VERSION ""

NS_ :

BS_:

BU_: WPC2 RLPSU DPSU APSU PSB SHVU_RR vHS_B2 FCS EMCU SLB ARS RCM CGW_CCU vDummy_HS_B ATS RLHV SGU PFSU ALBCU DSAU SWRC SHVU_FR RCS RRPSU BLTN_CAM SCM DLBCU OHCL RWPC RRHV WPC HOD ASAU

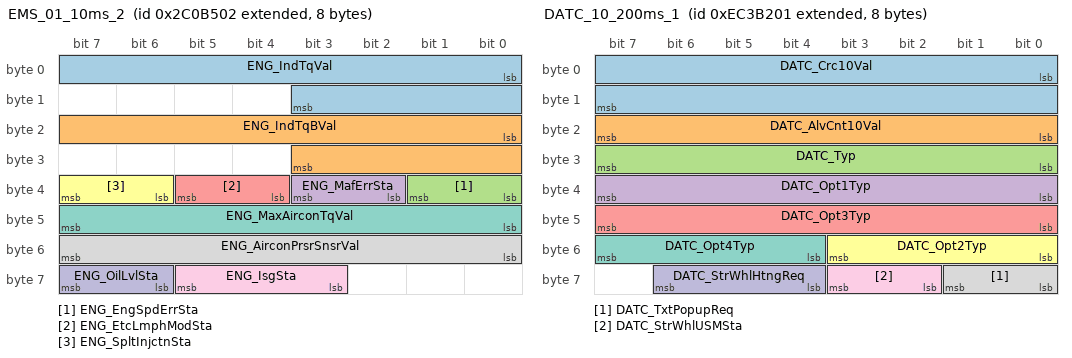
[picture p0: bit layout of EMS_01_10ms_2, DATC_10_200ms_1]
BO_ 2193667330 EMS_01_10ms_2: 8 CGW_CCU
 SG_ ENG_IndTqVal : 0|12@1- (1,0) [0|0] "Nm"  Vector__XXX
 SG_ ENG_IndTqBVal : 16|12@1- (1,0) [0|0] "Nm"  Vector__XXX
 SG_ ENG_EngSpdErrSta : 32|2@1+ (1,0) [0|0] ""  Vector__XXX
 SG_ ENG_MafErrSta : 34|2@1+ (1,0) [0|0] ""  Vector__XXX
 SG_ ENG_EtcLmphModSta : 36|2@1+ (1,0) [0|0] ""  Vector__XXX
 SG_ ENG_SpltInjctnSta : 38|2@1+ (1,0) [0|0] ""  Vector__XXX
 SG_ ENG_MaxAirconTqVal : 40|8@1+ (0.2,0) [0|0] "Nm"  Vector__XXX
 SG_ ENG_AirconPrsrSnsrVal : 48|8@1+ (125,0) [0|0] "hPa"  Vector__XXX
 SG_ ENG_IsgSta : 59|3@1+ (1,0) [0|0] ""  APSU,RLHV,RRHV,SHVU_FR,SHVU_RR,DPSU,RRPSU,RLPSU,EMCU
 SG_ ENG_OilLvlSta : 62|2@1+ (1,0) [0|0] ""  Vector__XXX

BO_ 2395189761 DATC_10_200ms_1: 8 CGW_CCU
 SG_ DATC_Crc10Val : 0|16@1+ (1,0) [0|0] ""  Vector__XXX
 SG_ DATC_AlvCnt10Val : 16|8@1+ (1,0) [0|0] ""  Vector__XXX
 SG_ DATC_Typ : 24|8@1+ (1,0) [0|0] ""  RLHV,RRHV,SHVU_FR,SHVU_RR,ATS
 SG_ DATC_Opt1Typ : 32|8@1+ (1,0) [0|0] ""  ATS
 SG_ DATC_Opt3Typ : 40|8@1+ (1,0) [0|0] ""  ATS
 SG_ DATC_Opt2Typ : 48|4@1+ (1,0) [0|0] ""  ATS
 SG_ DATC_Opt4Typ : 52|4@1+ (1,0) [0|0] ""  ATS
 SG_ DATC_TxtPopupReq : 56|2@1+ (1,0) [0|0] ""  Vector__XXX
 SG_ DATC_StrWhlUSMSta : 58|2@1+ (1,0) [0|0] ""  APSU
 SG_ DATC_StrWhlHtngReq : 60|3@1+ (1,0) [0|0] ""  Vector__XXX

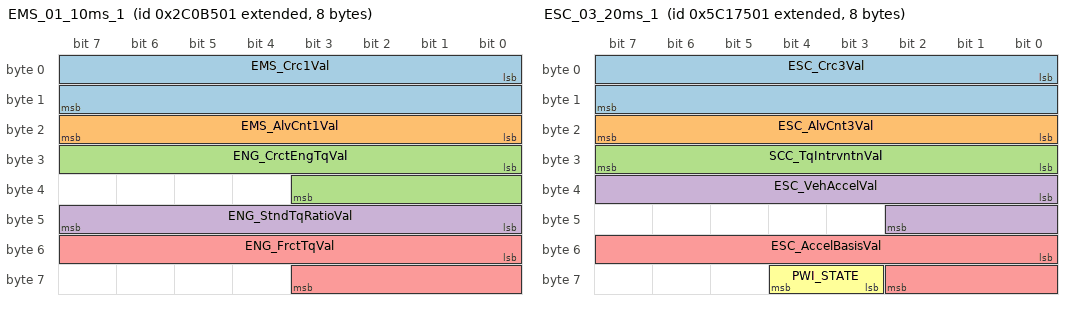
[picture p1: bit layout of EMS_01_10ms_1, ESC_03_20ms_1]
BO_ 2193667329 EMS_01_10ms_1: 8 CGW_CCU
 SG_ EMS_Crc1Val : 0|16@1+ (1,0) [0|0] ""  Vector__XXX
 SG_ EMS_AlvCnt1Val : 16|8@1+ (1,0) [0|0] ""  Vector__XXX
 SG_ ENG_CrctEngTqVal : 24|12@1- (1,0) [0|0] "Nm"  Vector__XXX
 SG_ ENG_StndTqRatioVal : 40|8@1+ (0.0078,0) [0|0] ""  Vector__XXX
 SG_ ENG_FrctTqVal : 48|12@1- (1,0) [0|0] "Nm"  Vector__XXX

BO_ 2214659332 EMS_07_10ms_4: 8 CGW_CCU

BO_ 2214659331 EMS_07_10ms_3: 8 CGW_CCU

BO_ 2244048129 ESC_03_20ms_1: 8 CGW_CCU
 SG_ ESC_Crc3Val : 0|16@1+ (1,0) [0|0] ""  Vector__XXX
 SG_ ESC_AlvCnt3Val : 16|8@1+ (1,0) [0|0] ""  Vector__XXX
 SG_ SCC_TqIntrvntnVal : 24|8@1+ (0.390625,0) [0|0] "%"  Vector__XXX
 SG_ ESC_VehAccelVal : 32|11@1+ (0.01,-10.23) [0|0] "m/s^2"  Vector__XXX
 SG_ ESC_AccelBasisVal : 48|11@1+ (0.01,-10.23) [0|0] "m/s^2"  Vector__XXX
 SG_ PWI_STATE : 59|2@1+ (1,0) [0|0] ""  Vector__XXX

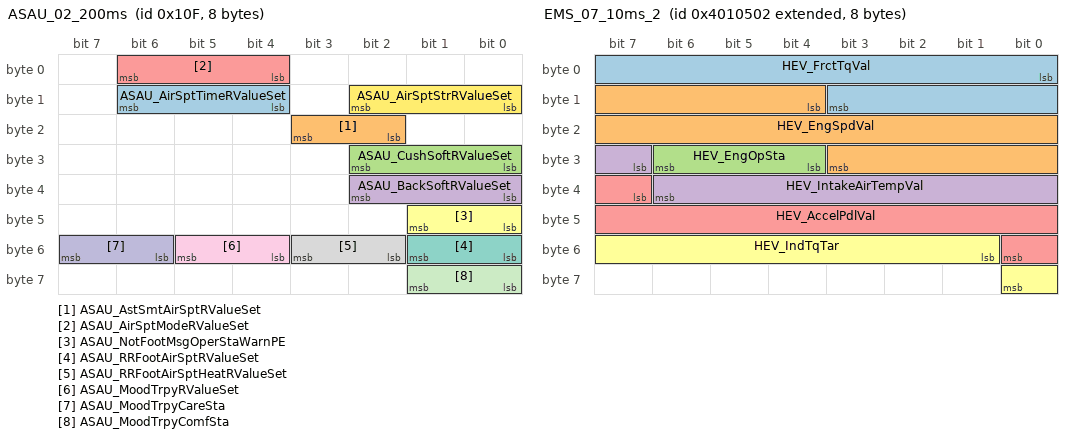
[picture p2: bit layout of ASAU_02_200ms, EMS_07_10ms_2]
BO_ 271 ASAU_02_200ms: 8 ASAU
 SG_ ASAU_AirSptTimeRValueSet : 12|3@1+ (1,0) [0|0] ""  CGW_CCU
 SG_ ASAU_AstSmtAirSptRValueSet : 18|2@1+ (1,0) [0|0] ""  CGW_CCU
 SG_ ASAU_CushSoftRValueSet : 24|3@1+ (1,0) [0|0] ""  CGW_CCU
 SG_ ASAU_BackSoftRValueSet : 32|3@1+ (1,0) [0|0] ""  CGW_CCU
 SG_ ASAU_AirSptModeRValueSet : 4|3@1+ (1,0) [0|0] ""  CGW_CCU
 SG_ ASAU_NotFootMsgOperStaWarnPE : 40|2@1+ (1,0) [0|0] ""  ATS
 SG_ ASAU_RRFootAirSptRValueSet : 48|2@1+ (1,0) [0|0] ""  ATS
 SG_ ASAU_RRFootAirSptHeatRValueSet : 50|2@1+ (1,0) [0|0] ""  ATS
 SG_ ASAU_MoodTrpyRValueSet : 52|2@1+ (1,0) [0|0] ""  CGW_CCU
 SG_ ASAU_MoodTrpyCareSta : 54|2@1+ (1,0) [0|0] ""  CGW_CCU
 SG_ ASAU_MoodTrpyComfSta : 56|2@1+ (1,0) [0|0] ""  CGW_CCU
 SG_ ASAU_AirSptStrRValueSet : 8|3@1+ (1,0) [0|0] ""  CGW_CCU

BO_ 2214659330 EMS_07_10ms_2: 8 CGW_CCU
 SG_ HEV_FrctTqVal : 0|12@1+ (0.1,0) [0|0] "Nm"  Vector__XXX
 SG_ HEV_EngSpdVal : 12|16@1+ (0.25,0) [0|0] "rpm"  Vector__XXX
 SG_ HEV_EngOpSta : 28|3@1+ (1,0) [0|0] ""  WPC,RWPC,PFSU,WPC2
 SG_ HEV_IntakeAirTempVal : 31|8@1+ (0.75,-48) [0|0] "¡É"  Vector__XXX
 SG_ HEV_AccelPdlVal : 39|10@1+ (0.09784,0) [0|0] "%"  BLTN_CAM
 SG_ HEV_IndTqTar : 49|8@1+ (0.3906,0) [0|0] "%"  Vector__XXX

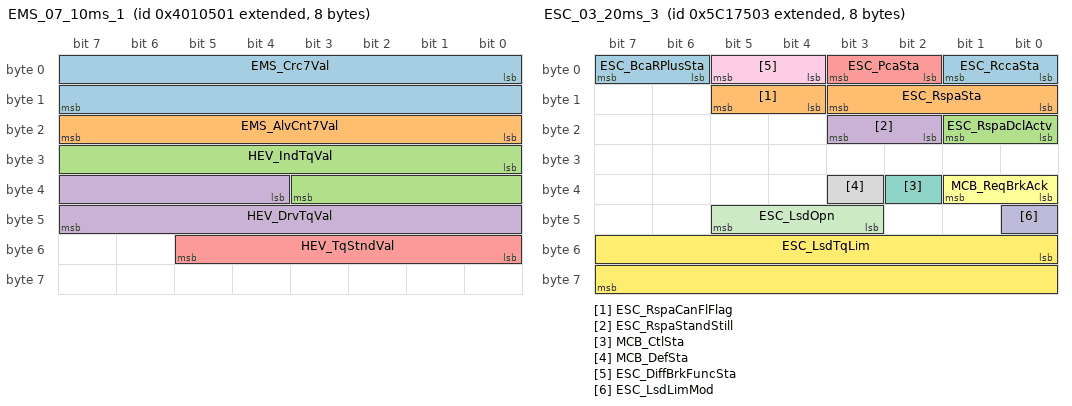
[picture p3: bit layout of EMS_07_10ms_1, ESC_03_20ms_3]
BO_ 2214659329 EMS_07_10ms_1: 8 CGW_CCU
 SG_ EMS_Crc7Val : 0|16@1+ (1,0) [0|0] ""  Vector__XXX
 SG_ EMS_AlvCnt7Val : 16|8@1+ (1,0) [0|0] ""  Vector__XXX
 SG_ HEV_IndTqVal : 24|12@1+ (0.1,0) [0|0] "Nm"  Vector__XXX
 SG_ HEV_DrvTqVal : 36|12@1+ (0.390625,0) [0|0] "%"  Vector__XXX
 SG_ HEV_TqStndVal : 48|6@1+ (10,0) [0|0] "Nm"  Vector__XXX

BO_ 2244048131 ESC_03_20ms_3: 8 CGW_CCU
 SG_ ESC_RccaSta : 0|2@1+ (1,0) [0|0] ""  Vector__XXX
 SG_ ESC_RspaCanFlFlag : 12|2@1+ (1,0) [0|0] ""  Vector__XXX
 SG_ ESC_RspaDclActv : 16|2@1+ (1,0) [0|0] ""  Vector__XXX
 SG_ ESC_RspaStandStill : 18|2@1+ (1,0) [0|0] ""  Vector__XXX
 SG_ ESC_PcaSta : 2|2@1+ (1,0) [0|0] ""  Vector__XXX
 SG_ MCB_ReqBrkAck : 32|2@1+ (1,0) [0|0] ""  Vector__XXX
 SG_ MCB_CtlSta : 34|1@1+ (1,0) [0|0] ""  Vector__XXX
 SG_ MCB_DefSta : 35|1@1+ (1,0) [0|0] ""  Vector__XXX
 SG_ ESC_DiffBrkFuncSta : 4|2@1+ (1,0) [0|0] ""  Vector__XXX
 SG_ ESC_LsdLimMod : 40|1@1+ (1,0) [0|0] ""  Vector__XXX
 SG_ ESC_LsdOpn : 43|3@1+ (1,0) [0|0] ""  Vector__XXX
 SG_ ESC_LsdTqLim : 48|16@1+ (1,0) [0|0] "Nm"  Vector__XXX
 SG_ ESC_BcaRPlusSta : 6|2@1+ (1,0) [0|0] ""  Vector__XXX
 SG_ ESC_RspaSta : 8|4@1+ (1,0) [0|0] ""  Vector__XXX

BO_ 2244048130 ESC_03_20ms_2: 8 CGW_CCU
 SG_ SCC_OptTyp : 0|2@1+ (1,0) [0|0] ""  Vector__XXX
 SG_ ESC_BrkLtReq : 10|2@1+ (1,0) [0|0] ""  Vector__XXX
 SG_ ESC_DclEnblReq : 12|2@1+ (1,0) [0|0] ""  Vector__XXX
 SG_ ESC_DrvOvrdSta : 16|2@1+ (1,0) [0|0] ""  Vector__XXX
 SG_ ESC_DrvBrkSta : 18|2@1+ (1,0) [0|0] ""  Vector__XXX
 SG_ SCC_EnblReq : 2|2@1+ (1,0) [0|0] ""  Vector__XXX
 SG_ ESC_DrvBrkActvSta : 20|2@1+ (1,0) [0|0] ""  Vector__XXX
 SG_ ESC_PrkBrkActvSta : 22|2@1+ (1,0) [0|0] ""  Vector__XXX
 SG_ ESC_HDP_FltMonSta : 24|3@1+ (1,0) [0|0] ""  PSB
 SG_ FCA_EquipSta : 32|2@1+ (1,0) [0|0] ""  Vector__XXX
 SG_ FCA_AvlblSta : 34|2@1+ (1,0) [0|0] ""  Vector__XXX
 SG_ ESC_FCA_ActvSta : 36|2@1+ (1,0) [0|0] ""  Vector__XXX
 SG_ ESC_DBS_ActvSta : 38|2@1+ (1,0) [0|0] ""  Vector__XXX
 SG_ SCC_TqReq : 4|2@1+ (1,0) [0|0] ""  Vector__XXX
 SG_ ESC_HDP_EgSta : 40|3@1+ (1,0) [0|0] ""  Vector__XXX
 SG_ ESC_HDP_EnblReq : 43|3@1+ (1,0) [0|0] ""  Vector__XXX
 SG_ CSC_WrngSta : 50|2@1+ (1,0) [0|0] ""  Vector__XXX
 SG_ ESC_BrkdFltStndstill : 56|2@1+ (1,0) [0|0] ""  Vector__XXX
 SG_ SCC_ReqLimSta : 6|2@1+ (1,0) [0|0] ""  Vector__XXX
 SG_ ESC_StdStillVal : 8|2@1+ (1,0) [0|0] ""  Vector__XXX

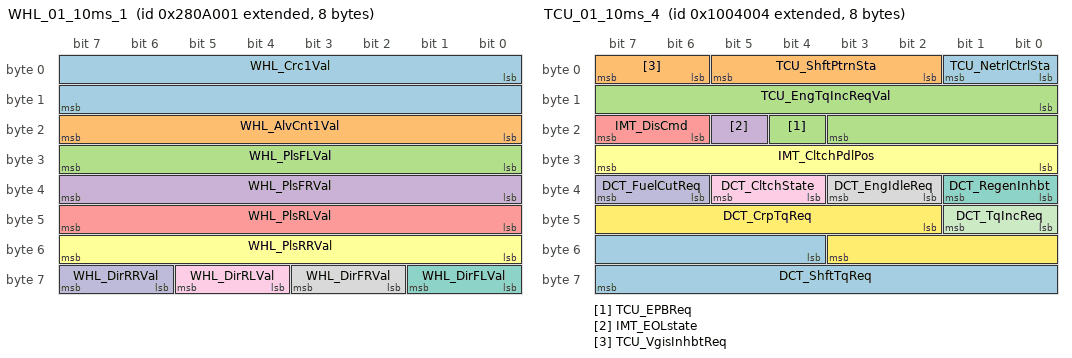
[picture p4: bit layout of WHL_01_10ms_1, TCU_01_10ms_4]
BO_ 2189467649 WHL_01_10ms_1: 8 CGW_CCU
 SG_ WHL_Crc1Val : 0|16@1+ (1,0) [0|0] ""  Vector__XXX
 SG_ WHL_AlvCnt1Val : 16|8@1+ (1,0) [0|0] ""  Vector__XXX
 SG_ WHL_PlsFLVal : 24|8@1+ (0.5,0) [0|0] "pulse count"  Vector__XXX
 SG_ WHL_PlsFRVal : 32|8@1+ (0.5,0) [0|0] "pulse count"  Vector__XXX
 SG_ WHL_PlsRLVal : 40|8@1+ (0.5,0) [0|0] "pulse count"  Vector__XXX
 SG_ WHL_PlsRRVal : 48|8@1+ (0.5,0) [0|0] "pulse count"  Vector__XXX
 SG_ WHL_DirFLVal : 56|2@1+ (1,0) [0|0] ""  Vector__XXX
 SG_ WHL_DirFRVal : 58|2@1+ (1,0) [0|0] ""  Vector__XXX
 SG_ WHL_DirRLVal : 60|2@1+ (1,0) [0|0] ""  Vector__XXX
 SG_ WHL_DirRRVal : 62|2@1+ (1,0) [0|0] ""  Vector__XXX

BO_ 2164277252 TCU_01_10ms_4: 8 CGW_CCU
 SG_ TCU_NetrlCtrlSta : 0|2@1+ (1,0) [0|0] ""  Vector__XXX
 SG_ TCU_ShftPtrnSta : 2|4@1+ (1,0) [0|0] ""  Vector__XXX
 SG_ TCU_EPBReq : 20|1@1+ (1,0) [0|0] ""  Vector__XXX
 SG_ IMT_EOLstate : 21|1@1+ (1,0) [0|0] ""  Vector__XXX
 SG_ IMT_DisCmd : 22|2@1+ (1,0) [0|0] ""  Vector__XXX
 SG_ IMT_CltchPdlPos : 24|8@1+ (0.390625,0) [0|0] "%"  Vector__XXX
 SG_ DCT_RegenInhbt : 32|2@1+ (1,0) [0|0] ""  Vector__XXX
 SG_ DCT_EngIdleReq : 34|2@1+ (1,0) [0|0] ""  Vector__XXX
 SG_ DCT_CltchState : 36|2@1+ (1,0) [0|0] ""  Vector__XXX
 SG_ DCT_FuelCutReq : 38|2@1+ (1,0) [0|0] ""  Vector__XXX
 SG_ DCT_TqIncReq : 40|2@1+ (1,0) [0|0] ""  Vector__XXX
 SG_ DCT_CrpTqReq : 42|10@1+ (1,-512) [0|0] "Nm"  Vector__XXX
 SG_ DCT_ShftTqReq : 52|12@1- (1,0) [0|0] "Nm"  Vector__XXX
 SG_ TCU_VgisInhbtReq : 6|2@1+ (1,0) [0|0] ""  Vector__XXX
 SG_ TCU_EngTqIncReqVal : 8|12@1- (1,0) [0|0] "Nm"  Vector__XXX

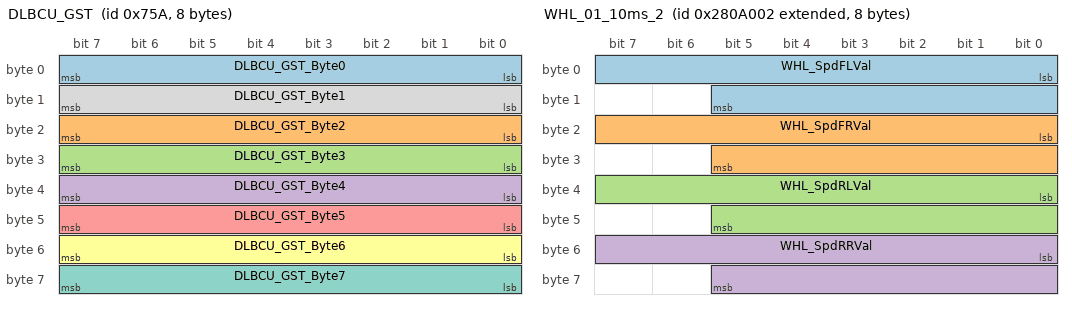
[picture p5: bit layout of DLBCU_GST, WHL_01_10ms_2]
BO_ 1882 DLBCU_GST: 8 DLBCU
 SG_ DLBCU_GST_Byte0 : 0|8@1+ (1,0) [0|0] ""  CGW_CCU
 SG_ DLBCU_GST_Byte2 : 16|8@1+ (1,0) [0|0] ""  CGW_CCU
 SG_ DLBCU_GST_Byte3 : 24|8@1+ (1,0) [0|0] ""  CGW_CCU
 SG_ DLBCU_GST_Byte4 : 32|8@1+ (1,0) [0|0] ""  CGW_CCU
 SG_ DLBCU_GST_Byte5 : 40|8@1+ (1,0) [0|0] ""  CGW_CCU
 SG_ DLBCU_GST_Byte6 : 48|8@1+ (1,0) [0|0] ""  CGW_CCU
 SG_ DLBCU_GST_Byte7 : 56|8@1+ (1,0) [0|0] ""  CGW_CCU
 SG_ DLBCU_GST_Byte1 : 8|8@1+ (1,0) [0|0] ""  CGW_CCU

BO_ 2189467650 WHL_01_10ms_2: 8 CGW_CCU
 SG_ WHL_SpdFLVal : 0|14@1+ (0.03125,0) [0|0] "km^h"  PSB
 SG_ WHL_SpdFRVal : 16|14@1+ (0.03125,0) [0|0] "km^h"  PSB
 SG_ WHL_SpdRLVal : 32|14@1+ (0.03125,0) [0|0] "km^h"  PSB,APSU
 SG_ WHL_SpdRRVal : 48|14@1+ (0.03125,0) [0|0] "km^h"  PSB,APSU

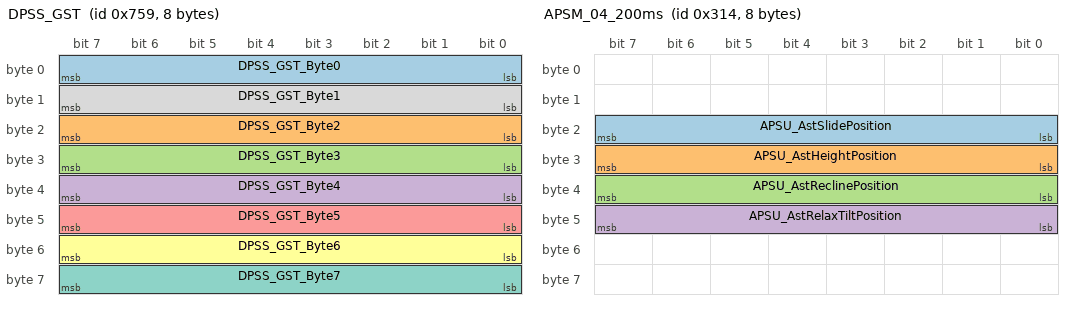
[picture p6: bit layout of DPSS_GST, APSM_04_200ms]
BO_ 1881 DPSS_GST: 8 DPSU
 SG_ DPSS_GST_Byte0 : 0|8@1+ (1,0) [0|0] ""  CGW_CCU
 SG_ DPSS_GST_Byte2 : 16|8@1+ (1,0) [0|0] ""  CGW_CCU
 SG_ DPSS_GST_Byte3 : 24|8@1+ (1,0) [0|0] ""  CGW_CCU
 SG_ DPSS_GST_Byte4 : 32|8@1+ (1,0) [0|0] ""  CGW_CCU
 SG_ DPSS_GST_Byte5 : 40|8@1+ (1,0) [0|0] ""  CGW_CCU
 SG_ DPSS_GST_Byte6 : 48|8@1+ (1,0) [0|0] ""  CGW_CCU
 SG_ DPSS_GST_Byte7 : 56|8@1+ (1,0) [0|0] ""  CGW_CCU
 SG_ DPSS_GST_Byte1 : 8|8@1+ (1,0) [0|0] ""  CGW_CCU

BO_ 2189467651 WHL_01_10ms_3: 8 CGW_CCU
 SG_ WHL_SpdCalParmtr : 8|9@1+ (0.5,200) [0|0] "mm"  Vector__XXX

BO_ 788 APSM_04_200ms: 8 APSU
 SG_ APSU_AstSlidePosition : 16|8@1+ (1,0) [0|0] ""  CGW_CCU
 SG_ APSU_AstHeightPosition : 24|8@1+ (1,0) [0|0] ""  CGW_CCU
 SG_ APSU_AstReclinePosition : 32|8@1+ (1,0) [0|0] ""  CGW_CCU
 SG_ APSU_AstRelaxTiltPosition : 40|8@1+ (1,0) [0|0] ""  CGW_CCU

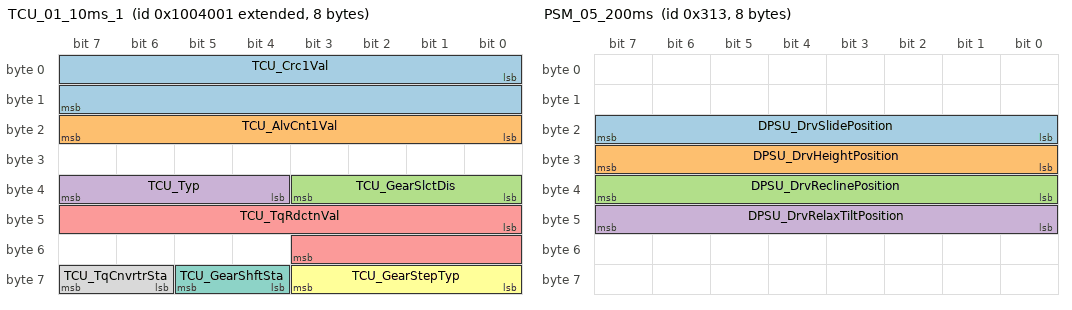
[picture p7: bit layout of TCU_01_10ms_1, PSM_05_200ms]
BO_ 2164277249 TCU_01_10ms_1: 8 CGW_CCU
 SG_ TCU_Crc1Val : 0|16@1+ (1,0) [0|0] ""  Vector__XXX
 SG_ TCU_AlvCnt1Val : 16|8@1+ (1,0) [0|0] ""  EMCU
 SG_ TCU_GearSlctDis : 32|4@1+ (1,0) [0|0] ""  SWRC,APSU,RLHV,RRHV,PFSU,RRPSU,RLPSU,BLTN_CAM
 SG_ TCU_Typ : 36|4@1+ (1,0) [0|0] ""  APSU,PFSU
 SG_ TCU_TqRdctnVal : 40|12@1- (1,0) [0|0] "Nm"  Vector__XXX
 SG_ TCU_GearStepTyp : 56|4@1+ (1,0) [0|0] ""  Vector__XXX
 SG_ TCU_GearShftSta : 60|2@1+ (1,0) [0|0] ""  Vector__XXX
 SG_ TCU_TqCnvrtrSta : 62|2@1+ (1,0) [0|0] ""  EMCU

BO_ 787 PSM_05_200ms: 8 DPSU
 SG_ DPSU_DrvSlidePosition : 16|8@1+ (1,0) [0|0] ""  CGW_CCU
 SG_ DPSU_DrvHeightPosition : 24|8@1+ (1,0) [0|0] ""  CGW_CCU
 SG_ DPSU_DrvReclinePosition : 32|8@1+ (1,0) [0|0] ""  CGW_CCU
 SG_ DPSU_DrvRelaxTiltPosition : 40|8@1+ (1,0) [0|0] ""  CGW_CCU

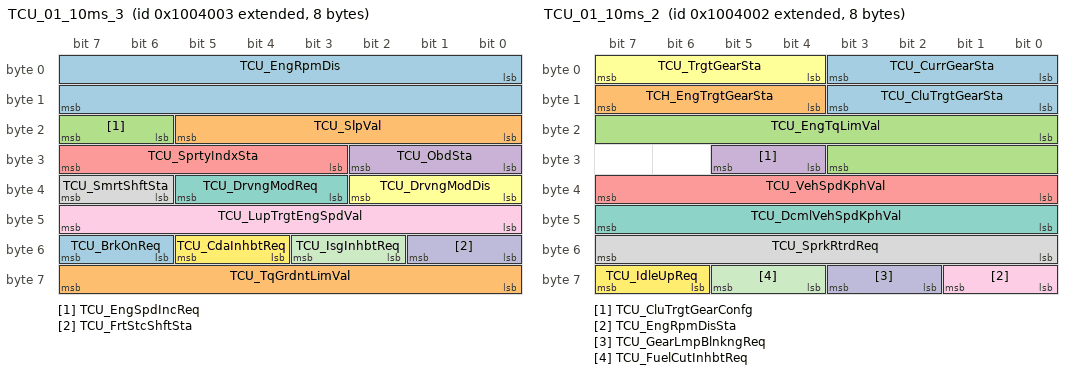
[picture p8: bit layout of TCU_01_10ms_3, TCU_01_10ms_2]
BO_ 2164277251 TCU_01_10ms_3: 8 CGW_CCU
 SG_ TCU_EngRpmDis : 0|16@1+ (0.25,0) [0|0] "rpm"  Vector__XXX
 SG_ TCU_SlpVal : 16|6@1+ (0.5,-16) [0|0] "%"  Vector__XXX
 SG_ TCU_EngSpdIncReq : 22|2@1+ (1,0) [0|0] ""  Vector__XXX
 SG_ TCU_ObdSta : 24|3@1+ (1,0) [0|0] ""  Vector__XXX
 SG_ TCU_SprtyIndxSta : 27|5@1+ (1,0) [0|0] ""  Vector__XXX
 SG_ TCU_DrvngModDis : 32|3@1+ (1,0) [0|0] ""  Vector__XXX
 SG_ TCU_DrvngModReq : 35|3@1+ (1,0) [0|0] ""  Vector__XXX
 SG_ TCU_SmrtShftSta : 38|2@1+ (1,0) [0|0] ""  Vector__XXX
 SG_ TCU_LupTrgtEngSpdVal : 40|8@1+ (10,500) [0|0] "rpm"  Vector__XXX
 SG_ TCU_FrtStcShftSta : 48|2@1+ (1,0) [0|0] ""  Vector__XXX
 SG_ TCU_IsgInhbtReq : 50|2@1+ (1,0) [0|0] ""  Vector__XXX
 SG_ TCU_CdaInhbtReq : 52|2@1+ (1,0) [0|0] ""  Vector__XXX
 SG_ TCU_BrkOnReq : 54|2@1+ (1,0) [0|0] ""  Vector__XXX
 SG_ TCU_TqGrdntLimVal : 56|8@1+ (10,0) [0|0] "Nm/s"  Vector__XXX

BO_ 2164277250 TCU_01_10ms_2: 8 CGW_CCU
 SG_ TCU_CurrGearSta : 0|4@1+ (1,0) [0|0] ""  EMCU
 SG_ TCH_EngTrgtGearSta : 12|4@1+ (1,0) [0|0] ""  Vector__XXX
 SG_ TCU_EngTqLimVal : 16|12@1- (1,0) [0|0] "Nm"  Vector__XXX
 SG_ TCU_CluTrgtGearConfg : 28|2@1+ (1,0) [0|0] ""  Vector__XXX
 SG_ TCU_VehSpdKphVal : 32|8@1+ (1,0) [0|0] "km/h"  Vector__XXX
 SG_ TCU_TrgtGearSta : 4|4@1+ (1,0) [0|0] ""  Vector__XXX
 SG_ TCU_DcmlVehSpdKphVal : 40|8@1+ (0.0078125,0) [0|0] "km/h"  Vector__XXX
 SG_ TCU_SprkRtrdReq : 48|8@1+ (0.375,-23.625) [0|0] "¢ª"  Vector__XXX
 SG_ TCU_EngRpmDisSta : 56|2@1+ (1,0) [0|0] ""  Vector__XXX
 SG_ TCU_GearLmpBlnkngReq : 58|2@1+ (1,0) [0|0] ""  Vector__XXX
 SG_ TCU_FuelCutInhbtReq : 60|2@1+ (1,0) [0|0] ""  Vector__XXX
 SG_ TCU_IdleUpReq : 62|2@1+ (1,0) [0|0] ""  Vector__XXX
 SG_ TCU_CluTrgtGearSta : 8|4@1+ (1,0) [0|0] ""  Vector__XXX

BO_ 799 SBCM_DRV_01_200ms: 8 CGW_CCU
 SG_ SBCM_DRV_Crc1Val : 0|8@1+ (1,0) [0|0] ""  Vector__XXX
 SG_ DRV_CrashUnlockCmd : 10|1@1+ (1,0) [0|0] ""  BLTN_CAM
 SG_ C_ApprOpenStatus : 11|1@1+ (1,0) [0|0] ""  Vector__XXX
 SG_ SBCM_DRV_AlvCnt1Val : 12|4@1+ (1,0) [0|0] ""  Vector__XXX
 SG_ DoorLock_DrvKeyLkSwSta_SBCM : 16|2@1+ (1,0) [0|0] ""  Vector__XXX
 SG_ DoorLock_DrvKeyUnLkSwSta_SBCM : 18|2@1+ (1,0) [0|0] ""  Vector__XXX
 SG_ Warn_DrvDrSwSta_SBCM : 20|2@1+ (1,0) [0|0] ""  WPC,RWPC,DPSU,ATS,BLTN_CAM,WPC2
 SG_ DoorLock_DrvDrUnLkSta_SBCM : 22|2@1+ (1,0) [0|0] ""  ATS
 SG_ DRV_SEAWarn_LH : 24|2@1+ (1,0) [0|0] ""  Vector__XXX
 SG_ DRV_SEAWarn_RH : 26|2@1+ (1,0) [0|0] ""  Vector__XXX
 SG_ DRV_SEWWarn_LH : 28|2@1+ (1,0) [0|0] ""  Vector__XXX
 SG_ DRV_SEWWarn_RH : 30|2@1+ (1,0) [0|0] ""  Vector__XXX
 SG_ DRV_MRActivationAlarm : 32|2@1+ (1,0) [0|0] ""  Vector__XXX
 SG_ DRV_ReleaseWarn : 34|2@1+ (1,0) [0|0] ""  Vector__XXX
 SG_ Latch_TypeOption_DRV : 36|2@1+ (1,0) [0|0] ""  Vector__XXX
 SG_ DRV_SWFailAlarm : 38|2@1+ (1,0) [0|0] ""  Vector__XXX
 SG_ USM_PwrDRApprOpnSetSta : 40|2@1+ (1,0) [0|0] ""  Vector__XXX
 SG_ USM_PwrDRApprOpnSetOpt : 42|2@1+ (1,0) [0|0] ""  Vector__XXX
 SG_ USM_PwrDRCloseByRKELockSta : 44|2@1+ (1,0) [0|0] ""  Vector__XXX
 SG_ USM_PwrDRCloseByRKELockOpt : 46|2@1+ (1,0) [0|0] ""  Vector__XXX
 SG_ USM_PwrDRCloseByBrakeSta : 48|2@1+ (1,0) [0|0] ""  Vector__XXX
 SG_ USM_PwrDRCloseByBrakeOpt : 50|2@1+ (1,0) [0|0] ""  Vector__XXX
 SG_ USM_PwrDRBuzzerSta : 52|2@1+ (1,0) [0|0] ""  Vector__XXX
 SG_ USM_PwrDRBuzzerOpt : 54|2@1+ (1,0) [0|0] ""  Vector__XXX
 SG_ PDS_TypeOption_DRV : 56|2@1+ (1,0) [0|0] ""  Vector__XXX
 SG_ C_DrvDoorApproachOpen : 58|2@1+ (1,0) [0|0] ""  Vector__XXX
 SG_ C_DrvDoorApproachClose : 60|2@1+ (1,0) [0|0] ""  Vector__XXX
 SG_ DoorLock_PDSLkSwSta_DRV : 62|2@1+ (1,0) [0|0] ""  Vector__XXX
 SG_ DRVDoorPushAlarm : 8|2@1+ (1,0) [0|0] ""  Vector__XXX

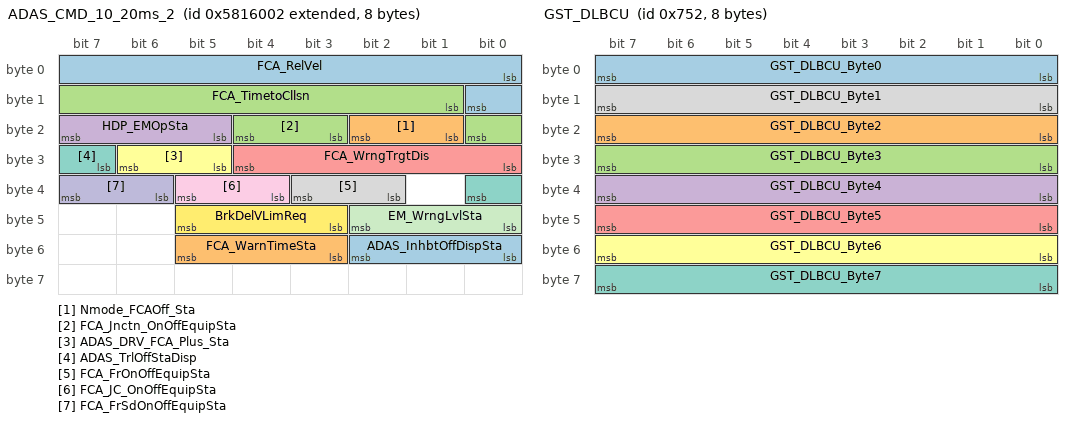
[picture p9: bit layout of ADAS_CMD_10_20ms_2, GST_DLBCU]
BO_ 2239848450 ADAS_CMD_10_20ms_2: 8 CGW_CCU
 SG_ FCA_RelVel : 0|9@1+ (0.1,-25.5) [0|0] "m/s"  Vector__XXX
 SG_ Nmode_FCAOff_Sta : 17|2@1+ (1,0) [0|0] ""  Vector__XXX
 SG_ FCA_Jnctn_OnOffEquipSta : 19|2@1+ (1,0) [0|0] ""  PSB
 SG_ HDP_EMOpSta : 21|3@1+ (1,0) [0|0] ""  Vector__XXX
 SG_ FCA_WrngTrgtDis : 24|5@1+ (1,0) [0|0] ""  APSU
 SG_ ADAS_DRV_FCA_Plus_Sta : 29|2@1+ (1,0) [0|0] ""  Vector__XXX
 SG_ ADAS_TrlOffStaDisp : 31|2@1+ (1,0) [0|0] ""  Vector__XXX
 SG_ FCA_FrOnOffEquipSta : 34|2@1+ (1,0) [0|0] ""  Vector__XXX
 SG_ FCA_JC_OnOffEquipSta : 36|2@1+ (1,0) [0|0] ""  Vector__XXX
 SG_ FCA_FrSdOnOffEquipSta : 38|2@1+ (1,0) [0|0] ""  Vector__XXX
 SG_ EM_WrngLvlSta : 40|3@1+ (1,0) [0|0] ""  Vector__XXX
 SG_ BrkDelVLimReq : 43|3@1+ (1,0) [0|0] ""  Vector__XXX
 SG_ ADAS_InhbtOffDispSta : 48|3@1+ (1,0) [0|0] ""  Vector__XXX
 SG_ FCA_WarnTimeSta : 51|3@1+ (1,0) [0|0] ""  Vector__XXX
 SG_ FCA_TimetoCllsn : 9|8@1+ (10,0) [0|0] "ms"  Vector__XXX

BO_ 1874 GST_DLBCU: 8 CGW_CCU
 SG_ GST_DLBCU_Byte0 : 0|8@1+ (1,0) [0|0] ""  DLBCU
 SG_ GST_DLBCU_Byte2 : 16|8@1+ (1,0) [0|0] ""  DLBCU
 SG_ GST_DLBCU_Byte3 : 24|8@1+ (1,0) [0|0] ""  DLBCU
 SG_ GST_DLBCU_Byte4 : 32|8@1+ (1,0) [0|0] ""  DLBCU
 SG_ GST_DLBCU_Byte5 : 40|8@1+ (1,0) [0|0] ""  DLBCU
 SG_ GST_DLBCU_Byte6 : 48|8@1+ (1,0) [0|0] ""  DLBCU
 SG_ GST_DLBCU_Byte7 : 56|8@1+ (1,0) [0|0] ""  DLBCU
 SG_ GST_DLBCU_Byte1 : 8|8@1+ (1,0) [0|0] ""  DLBCU

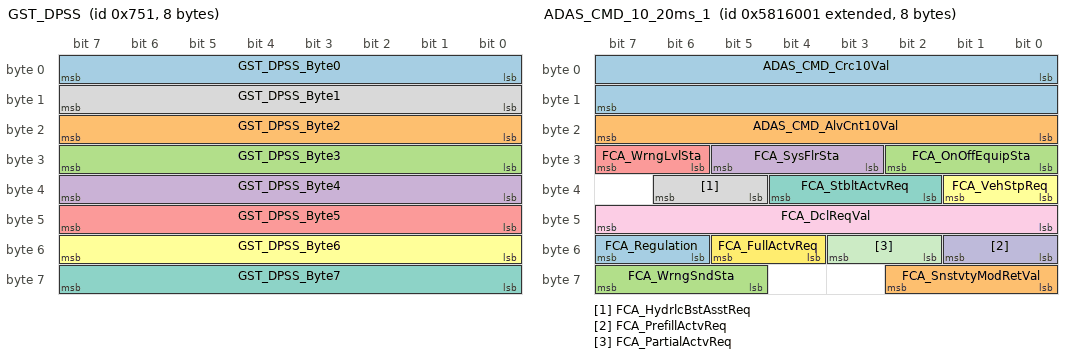
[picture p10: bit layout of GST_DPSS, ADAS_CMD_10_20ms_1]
BO_ 1873 GST_DPSS: 8 CGW_CCU
 SG_ GST_DPSS_Byte0 : 0|8@1+ (1,0) [0|0] ""  DPSU
 SG_ GST_DPSS_Byte2 : 16|8@1+ (1,0) [0|0] ""  DPSU
 SG_ GST_DPSS_Byte3 : 24|8@1+ (1,0) [0|0] ""  DPSU
 SG_ GST_DPSS_Byte4 : 32|8@1+ (1,0) [0|0] ""  DPSU
 SG_ GST_DPSS_Byte5 : 40|8@1+ (1,0) [0|0] ""  DPSU
 SG_ GST_DPSS_Byte6 : 48|8@1+ (1,0) [0|0] ""  DPSU
 SG_ GST_DPSS_Byte7 : 56|8@1+ (1,0) [0|0] ""  DPSU
 SG_ GST_DPSS_Byte1 : 8|8@1+ (1,0) [0|0] ""  DPSU

BO_ 2239848449 ADAS_CMD_10_20ms_1: 8 CGW_CCU
 SG_ ADAS_CMD_Crc10Val : 0|16@1+ (1,0) [0|0] ""  PSB
 SG_ ADAS_CMD_AlvCnt10Val : 16|8@1+ (1,0) [0|0] ""  PSB
 SG_ FCA_OnOffEquipSta : 24|3@1+ (1,0) [0|0] ""  PSB
 SG_ FCA_SysFlrSta : 27|3@1+ (1,0) [0|0] ""  PSB
 SG_ FCA_WrngLvlSta : 30|2@1+ (1,0) [0|0] ""  SWRC,APSU,RRPSU,RLPSU
 SG_ FCA_VehStpReq : 32|2@1+ (1,0) [0|0] ""  SWRC
 SG_ FCA_StbltActvReq : 34|3@1+ (1,0) [0|0] ""  PSB
 SG_ FCA_HydrlcBstAsstReq : 37|2@1+ (1,0) [0|0] ""  Vector__XXX
 SG_ FCA_DclReqVal : 40|8@1+ (0.01,0) [0|0] "g"  Vector__XXX
 SG_ FCA_PrefillActvReq : 48|2@1+ (1,0) [0|0] ""  Vector__XXX
 SG_ FCA_PartialActvReq : 50|2@1+ (1,0) [0|0] ""  Vector__XXX
 SG_ FCA_FullActvReq : 52|2@1+ (1,0) [0|0] ""  APSU,RRPSU,RLPSU
 SG_ FCA_Regulation : 54|2@1+ (1,0) [0|0] ""  Vector__XXX
 SG_ FCA_SnstvtyModRetVal : 56|3@1+ (1,0) [0|0] ""  Vector__XXX
 SG_ FCA_WrngSndSta : 61|3@1+ (1,0) [0|0] ""  Vector__XXX

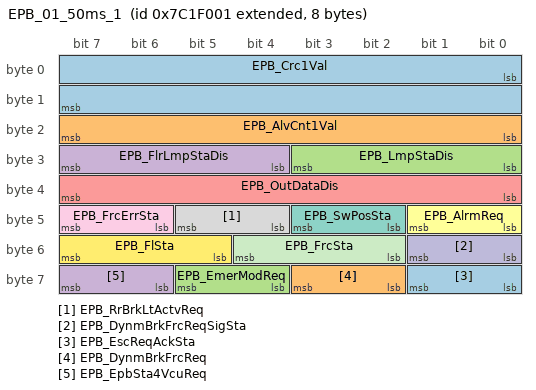
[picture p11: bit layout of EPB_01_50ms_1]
BO_ 2277634049 EPB_01_50ms_1: 8 CGW_CCU
 SG_ EPB_Crc1Val : 0|16@1+ (1,0) [0|0] ""  Vector__XXX
 SG_ EPB_AlvCnt1Val : 16|8@1+ (1,0) [0|0] ""  Vector__XXX
 SG_ EPB_LmpStaDis : 24|4@1+ (1,0) [0|0] ""  APSU,RLHV,RRHV,DPSU,PFSU,RRPSU,RLPSU
 SG_ EPB_FlrLmpStaDis : 28|4@1+ (1,0) [0|0] ""  Vector__XXX
 SG_ EPB_OutDataDis : 32|8@1+ (1,0) [0|0] ""  Vector__XXX
 SG_ EPB_AlrmReq : 40|2@1+ (1,0) [0|0] ""  Vector__XXX
 SG_ EPB_SwPosSta : 42|2@1+ (1,0) [0|0] ""  Vector__XXX
 SG_ EPB_RrBrkLtActvReq : 44|2@1+ (1,0) [0|0] ""  Vector__XXX
 SG_ EPB_FrcErrSta : 46|2@1+ (1,0) [0|0] ""  Vector__XXX
 SG_ EPB_DynmBrkFrcReqSigSta : 48|2@1+ (1,0) [0|0] ""  Vector__XXX
 SG_ EPB_FrcSta : 50|3@1+ (1,0) [0|0] ""  Vector__XXX
 SG_ EPB_FlSta : 53|3@1+ (1,0) [0|0] ""  Vector__XXX
 SG_ EPB_EscReqAckSta : 56|2@1+ (1,0) [0|0] ""  Vector__XXX
 SG_ EPB_DynmBrkFrcReq : 58|2@1+ (1,0) [0|0] ""  Vector__XXX
 SG_ EPB_EmerModReq : 60|2@1+ (1,0) [0|0] ""  Vector__XXX
 SG_ EPB_EpbSta4VcuReq : 62|2@1+ (1,0) [0|0] ""  Vector__XXX

BO_ 2277634050 EPB_01_50ms_2: 8 CGW_CCU
 SG_ EPB_ActlFrcVal : 0|12@1+ (1,-1000) [0|0] ""  Vector__XXX
 SG_ EPB_DynmBrkFrcDclReq : 16|8@1+ (0.01,0) [0|0] "g"  Vector__XXX

CM_ BO_ 2239848449 "[P] Periodic";
CM_ SG_ 2239848449 ADAS_CMD_Crc10Val "ADAS_CMD_CyclicRedundancyCheck10Value ##2G##FCA - FCA11 - CR_FCA_ChkSum";
CM_ SG_ 2239848449 ADAS_CMD_AlvCnt10Val "ADAS_CMD_AliveCounter10Value ##2G##FCA - FCA11 - CR_FCA_Alive";
CM_ SG_ 2239848449 FCA_OnOffEquipSta "FCA_OnOffEquipmentStatus ##2G##FCA - FCA12 - FCA_USM";
CM_ SG_ 2239848449 FCA_SysFlrSta "FCA_SystemFailureStatus ##2G##FCA - FCA11 - FCA_Failinfo";
CM_ SG_ 2239848449 FCA_WrngLvlSta "FCA_WarningLevelStatus ##2G##FCA - FCA11 - CF_VSM_Warn";
CM_ SG_ 2239848449 FCA_VehStpReq "FCA_VehicleStopRequest ##2G##FCA - FCA11 - FCA_StopReq";
CM_ SG_ 2239848449 FCA_StbltActvReq "FCA_SeatBeltActivateRequest ##2G##FCA - FCA11 - CF_VSM_BeltCmd";
CM_ SG_ 2239848449 FCA_HydrlcBstAsstReq "FCA_HydraulicBoostAssistRequest ##2G##FCA - FCA11 - CF_VSM_HBACmd";
CM_ SG_ 2239848449 FCA_DclReqVal "FCA_DecelerationRequestValue ##2G##FCA - FCA11 - CR_VSM_DecCmd";
CM_ SG_ 2239848449 FCA_PrefillActvReq "FCA_PrefillActivateRequest ##2G##FCA - FCA11 - CF_VSM_Prefill";
CM_ SG_ 2239848449 FCA_PartialActvReq "FCA_PartialActivateRequest";
CM_ SG_ 2239848449 FCA_FullActvReq "FCA_FullActivateRequest";
CM_ SG_ 2239848449 FCA_Regulation "FCA_Regulation";
CM_ SG_ 2239848449 FCA_SnstvtyModRetVal "FCA_SensitivityModeReturnValue ##2G##FCA - FCA12 - FCA_DrvSetState";
CM_ SG_ 2239848449 FCA_WrngSndSta "FCA warning sound status";
CM_ BO_ 2239848450 "[P] Periodic";
CM_ SG_ 2239848450 FCA_RelVel "FCA_RelativeVelocity ##2G##FCA - FCA11_FS - FCA_RelativeVelocity";
CM_ SG_ 2239848450 Nmode_FCAOff_Sta "Nmode_FCAOff_Status ##2G##FCA - FCA12 - Nmode_FCAOff_Status";
CM_ SG_ 2239848450 FCA_Jnctn_OnOffEquipSta "FCA_Junction_OnOffEquipStatus";
CM_ SG_ 2239848450 HDP_EMOpSta "HDP EM Operating State";
CM_ SG_ 2239848450 FCA_WrngTrgtDis "FCA_WarningTargetDisplay";
CM_ SG_ 2239848450 ADAS_DRV_FCA_Plus_Sta "Àü¹æÄ«¸Þ¶ó, Àü¹æ·¹ÀÌ´õ ¹× ÀüÃø¹æ ·¹ÀÌ´õ/ÈÄÃø¹æ ·¹ÀÌÅÍ Ç»Àü Æ®·¢À» ÅëÇØ FCA-Car Å¸°Ù ¹× ÀÚÂ÷ ÁÂÃø/¿ìÃø ¿µ¿ª È¸ÇÇ ºÒ°¡´É ¿©ºÎ¸¦ ÆÇ´ÜÇÏ¿© FCA-Car/Ped/Cyc+ Flag¸¦ Ãâ·Â";
CM_ SG_ 2239848450 ADAS_TrlOffStaDisp "ADAS_Trailer Off State Display";
CM_ SG_ 2239848450 FCA_FrOnOffEquipSta "FCA Front On Off Equipment State";
CM_ SG_ 2239848450 FCA_JC_OnOffEquipSta "FCA_JC On Off Equipment State";
CM_ SG_ 2239848450 FCA_FrSdOnOffEquipSta "FCA Front Side On Off Equipment State";
CM_ SG_ 2239848450 EM_WrngLvlSta "EM_WarningLevelStatus";
CM_ SG_ 2239848450 BrkDelVLimReq "Brake Delta V Limit Request";
CM_ SG_ 2239848450 ADAS_InhbtOffDispSta "ADAS Inhibit Off Display State";
CM_ SG_ 2239848450 FCA_WarnTimeSta "FCA Warning Timing State";
CM_ SG_ 2239848450 FCA_TimetoCllsn "FCA_TimetoCollision ##2G##FCA - FCA11_FS - FCA_TimetoCollision";
CM_ BO_ 788 "[PE] Periodic and On Event";
CM_ BO_ 271 "[PE] Periodic and On Event";
CM_ SG_ 271 ASAU_AirSptTimeRValueSet "Air Support Time(Massage Time) USM R Value";
CM_ SG_ 271 ASAU_AstSmtAirSptRValueSet "Seat Smart Air Support Function USM R Value";
CM_ SG_ 271 ASAU_CushSoftRValueSet "Cushion Soft R Value";
CM_ SG_ 271 ASAU_BackSoftRValueSet "Back Soft USM R Value";
CM_ SG_ 271 ASAU_AirSptModeRValueSet "Air Support Mode(Massage Mode) USM R Value";
CM_ SG_ 271 ASAU_NotFootMsgOperStaWarnPE "Passenger Foot Massage Operation Disable Mode";
CM_ SG_ 271 ASAU_RRFootAirSptRValueSet "Foot Air Support USM R Value";
CM_ SG_ 271 ASAU_RRFootAirSptHeatRValueSet "Foot Air Support Heat USM R Value";
CM_ SG_ 271 ASAU_MoodTrpyRValueSet "Passenger Seat Mood Therapy R Value";
CM_ SG_ 271 ASAU_MoodTrpyCareSta "Passenger Seat Mood Therapy Care Mode R Value";
CM_ SG_ 271 ASAU_MoodTrpyComfSta "Passenger Seat Mood Therapy Comfort Mode R Value";
CM_ SG_ 271 ASAU_AirSptStrRValueSet "Air Support Strenth(Massage Strenth) USM R Value";
CM_ BO_ 2395189761 "[PE] Periodic and On Event";
CM_ SG_ 2395189761 DATC_Crc10Val "DATC_CyclicRedundancyCheck10Value";
CM_ SG_ 2395189761 DATC_AlvCnt10Val "DATC_AliveCounter10Value";
CM_ SG_ 2395189761 DATC_Typ "DATC_Type";
CM_ SG_ 2395189761 DATC_Opt1Typ "DATC_Option1Type";
CM_ SG_ 2395189761 DATC_Opt3Typ "DATC_Option3Type";
CM_ SG_ 2395189761 DATC_Opt2Typ "DATC_Option2Type";
CM_ SG_ 2395189761 DATC_Opt4Typ "HTR CONTROL OPTION";
CM_ SG_ 2395189761 DATC_TxtPopupReq "DATC_TextPopupReq";
CM_ SG_ 2395189761 DATC_StrWhlUSMSta "DATC_SteeringWheelUSMState";
CM_ SG_ 2395189761 DATC_StrWhlHtngReq "DATC_SteeringWheelHeatReq";
CM_ BO_ 1882 "[TP] Transport Protocol";
CM_ BO_ 1881 "[TP] Transport Protocol";
CM_ BO_ 2193667329 "[P] Periodic";
CM_ SG_ 2193667329 EMS_Crc1Val "EMS_CyclicRedundancyCheck1Value";
CM_ SG_ 2193667329 EMS_AlvCnt1Val "EMS_AliveCounter1Value";
CM_ SG_ 2193667329 ENG_CrctEngTqVal "ENG_CorrectedEngineTorqueValue ##2G##EMS - EMS11 - TQI_ACOR";
CM_ SG_ 2193667329 ENG_StndTqRatioVal "ENG_StandardTorqueRatioValue ##2G##EMS - EMS11 - RATIO_TQI_BAS_MAX_STND";
CM_ SG_ 2193667329 ENG_FrctTqVal "ENG_FrictionTorqueValue ##2G##EMS - EMS11 - TQFR";
CM_ BO_ 2193667330 "[P] Periodic";
CM_ SG_ 2193667330 ENG_IndTqVal "ENG_IndicatedTorqueValue ##2G##EMS - EMS11 - TQI";
CM_ SG_ 2193667330 ENG_IndTqBVal "ENG_IndicatedTorqueBValue ##2G##EMS - EMS_H12 - TQI_B";
CM_ SG_ 2193667330 ENG_EngSpdErrSta "ENG_EngineSpeedErrorStatus ##2G##EMS - EMS11 - F_N_ENG";
CM_ SG_ 2193667330 ENG_MafErrSta "ENG_MassAirFlowErrorStatus ##2G##EMS - EMS11 - F_SUB_TQI";
CM_ SG_ 2193667330 ENG_EtcLmphModSta "ENG_EtcLimphomeModeStatus ##2G##EMS - EMS_H12 - CF_Ems_EtcLimpMod";
CM_ SG_ 2193667330 ENG_SpltInjctnSta "ENG_SplitInjectionStatus";
CM_ SG_ 2193667330 ENG_MaxAirconTqVal "ENG_MaximumAirconTorqueValue ##2G##EMS - EMS_H12 - R_TqAcnApvC";
CM_ SG_ 2193667330 ENG_AirconPrsrSnsrVal "ENG_AirconPressureSensorValue ##2G##EMS - EMS_H12 - R_PAcnC";
CM_ SG_ 2193667330 ENG_IsgSta "ENG_IsgStatus ##2G##EMS - EMS_H12 - CF_Ems_IsgStat";
CM_ SG_ 2193667330 ENG_OilLvlSta "ENG_OilLevelStatus ##2G##EMS - EMS_H12 - CF_Ems_OilChg";
CM_ BO_ 2214659329 "[P] Periodic";
CM_ SG_ 2214659329 EMS_Crc7Val "EMS_CyclicRedundancyCheck7Value";
CM_ SG_ 2214659329 EMS_AlvCnt7Val "EMS_AliveCounter7Value";
CM_ SG_ 2214659329 HEV_IndTqVal "HEV_IndicatedTorqueValue";
CM_ SG_ 2214659329 HEV_DrvTqVal "HEV_DriverTorqueValue";
CM_ SG_ 2214659329 HEV_TqStndVal "HEV_TorqueStandardValue";
CM_ BO_ 2214659330 "[P] Periodic";
CM_ SG_ 2214659330 HEV_FrctTqVal "HEV_FrictionTorqueValue";
CM_ SG_ 2214659330 HEV_EngSpdVal "HEV_EngineSpeedValue";
CM_ SG_ 2214659330 HEV_EngOpSta "HEV_EngineOperatingStatus";
CM_ SG_ 2214659330 HEV_IntakeAirTempVal "HEV_IntakeAirTemperatureValue";
CM_ SG_ 2214659330 HEV_AccelPdlVal "HEV_AcceleratorPedalValue";
CM_ SG_ 2214659330 HEV_IndTqTar "HEV_IndicatedTorqueTarget";
CM_ BO_ 2214659331 "[P] Periodic";
CM_ BO_ 2214659332 "[P] Periodic";
CM_ BO_ 2277634049 "[P] Periodic";
CM_ SG_ 2277634049 EPB_Crc1Val "EPB_CyclicRedundancyCheck1Value";
CM_ SG_ 2277634049 EPB_AlvCnt1Val "EPB_AliveCounter1Value";
CM_ SG_ 2277634049 EPB_LmpStaDis "EPB_LampStateDisplay ##2G##EPB - EPB11 - EPB_I_LAMP";
CM_ SG_ 2277634049 EPB_FlrLmpStaDis "EPB_FailureLampStateDisplay ##2G##EPB - EPB11 - EPB_F_LAMP";
CM_ SG_ 2277634049 EPB_OutDataDis "EPB_OutputDataDisplay ##2G##EPB - EPB11 - EPB_CLU";
CM_ SG_ 2277634049 EPB_AlrmReq "EPB_AlarmRequest ##2G##EPB - EPB11 - EPB_ALARM";
CM_ SG_ 2277634049 EPB_SwPosSta "EPB_SwitchPositionStatus ##2G##EPB - EPB11 - EPB_SWITCH";
CM_ SG_ 2277634049 EPB_RrBrkLtActvReq "EPB_RearBrakeLightActivationRequest ##2G##EPB - EPB11 - EPB_RBL";
CM_ SG_ 2277634049 EPB_FrcErrSta "EPB_ForceErrorStatus ##2G##EPB - EPB11 - EPB_FRC_ERR";
CM_ SG_ 2277634049 EPB_DynmBrkFrcReqSigSta "EPB_DynamicBrakingForceRequestSignalStatus ##2G##EPB - EPB11 - EPB_DBF_STAT";
CM_ SG_ 2277634049 EPB_FrcSta "EPB_ForceStatus ##2G##EPB - EPB11 - EPB_STATUS";
CM_ SG_ 2277634049 EPB_FlSta "EPB_FailStatus ##2G##EPB - EPB11 - EPB_FAIL";
CM_ SG_ 2277634049 EPB_EscReqAckSta "EPB_EscRequestAcknowledgeStatus ##2G##EPB - EPB11 - ESP_ACK";
CM_ SG_ 2277634049 EPB_DynmBrkFrcReq "EPB_DynamicBrakingForceRequest ##2G##EPB - EPB11 - EPB_DBF_REQ";
CM_ SG_ 2277634049 EPB_EmerModReq "EPB Emergency Mode Request";
CM_ SG_ 2277634049 EPB_EpbSta4VcuReq "EPB Status when VCU request of parking command or not parking command";
CM_ BO_ 2277634050 "[P] Periodic";
CM_ SG_ 2277634050 EPB_ActlFrcVal "EPB_ActualForceValue ##2G##EPB - EPB11 - EPB_FORCE";
CM_ SG_ 2277634050 EPB_DynmBrkFrcDclReq "EPB_DynamicBrakingForceDecelerationRequest ##2G##EPB - EPB11 - EPB_DBF_DECEL";
CM_ BO_ 2244048129 "[P] Periodic";
CM_ SG_ 2244048129 ESC_Crc3Val "ESC_CyclicRedundancyCheck3Value";
CM_ SG_ 2244048129 ESC_AlvCnt3Val "ESC_AliveCounter3Value";
CM_ SG_ 2244048129 SCC_TqIntrvntnVal "SCC_TorqueInterventionValue ##2G##ESC - TCS13 - TQI_ACC";
CM_ SG_ 2244048129 ESC_VehAccelVal "ESC_VehicleAccelerationValue ##2G##ESC - TCS13 - ACCEL_REF_ACC";
CM_ SG_ 2244048129 ESC_AccelBasisVal "ESC_AccelerationBasisValue ##2G##ESC - TCS13 - aBasis";
CM_ BO_ 2244048130 "[P] Periodic";
CM_ SG_ 2244048130 SCC_OptTyp "SCC_OptionType ##2G##ESC - TCS13 - ACC_EQUIP";
CM_ SG_ 2244048130 ESC_BrkLtReq "ESC_BrakeLightRequest ##2G##ESC - TCS13 - BrakeLight";
CM_ SG_ 2244048130 ESC_DclEnblReq "ESC_DecelerationEnableRequest ##2G##ESC - TCS13 - DCEnable";
CM_ SG_ 2244048130 ESC_DrvOvrdSta "ESC_OverrideRequest ##2G##ESC - TCS13 - DriverOverride";
CM_ SG_ 2244048130 ESC_DrvBrkSta "ESC_DriverBrakingStatus ##2G##ESC - TCS13 - CF_DriBkeStat";
CM_ SG_ 2244048130 SCC_EnblReq "SCC_EnableRequest ##2G##ESC - TCS13 - ACCEnable";
CM_ SG_ 2244048130 ESC_DrvBrkActvSta "ESC_DriverBrakingActiveStatus ##2G##ESC - TCS13 - DriverBraking";
CM_ SG_ 2244048130 ESC_PrkBrkActvSta "ESC_ParkingBrakeActiveStatus ##2G##ESC - TCS13 - PBRAKE_ACT";
CM_ SG_ 2244048130 ESC_HDP_FltMonSta "ESC_HDP_FaultStatus";
CM_ SG_ 2244048130 FCA_EquipSta "FCA_EquipmentStatus ##2G##ESC - TCS13 - FCA_EQUIP";
CM_ SG_ 2244048130 FCA_AvlblSta "VSM_AvailableStatus ##2G##ESC - TCS13 - CF_VSM_Avail";
CM_ SG_ 2244048130 ESC_FCA_ActvSta "Status of control for FCA control request flag";
CM_ SG_ 2244048130 ESC_DBS_ActvSta "ESC_DBS_ActvSta ##2G## ESC - TCS11 - DBS_ACK";
CM_ SG_ 2244048130 SCC_TqReq "SCC_TorqueRequest ##2G##ESC - TCS13 - ACC_REQ";
CM_ SG_ 2244048130 ESC_HDP_EgSta "ESC_HDP_EngagedStatus";
CM_ SG_ 2244048130 ESC_HDP_EnblReq "ESC_HDP_EnableRequest";
CM_ SG_ 2244048130 ESC_BrkdFltStndstill "Detect Indication of braked, flatland and standstill state";
CM_ SG_ 2244048130 SCC_ReqLimSta "SCC_RequestLimitedStatus ##2G##ESC - TCS13 - ACCReqLim";
CM_ SG_ 2244048130 ESC_StdStillVal "ESC_StandStillValue ##2G##ESC - TCS13 - StandStill";
CM_ BO_ 2244048131 "[P] Periodic";
CM_ SG_ 2244048131 ESC_RccaSta "ESC_RccaStatus ##2G##ESC - ESP11 - ESP_RCCA_STAT";
CM_ SG_ 2244048131 ESC_RspaCanFlFlag "##2G##ESC - ESP11 - ESC_RspaCanfailflag";
CM_ SG_ 2244048131 ESC_RspaDclActv "##2G##ESC - ESP11 - ESC_RSPA_DEC_ACT";
CM_ SG_ 2244048131 ESC_RspaStandStill "##2G##ESC - ESP11 - ESC_RSPA_STANDSTILL";
CM_ SG_ 2244048131 ESC_PcaSta "ESC_PcaStatus";
CM_ SG_ 2244048131 MCB_ReqBrkAck "Acknowledge Status for MCB Brake Request";
CM_ SG_ 2244048131 MCB_CtlSta "Status for MCB Activation";
CM_ SG_ 2244048131 MCB_DefSta "Status for MCB defect";
CM_ SG_ 2244048131 ESC_DiffBrkFuncSta "ESC_DifferentialBrakeFunctionStatus ##2G##ESC - TCS13 - DF_BF_STAT";
CM_ SG_ 2244048131 ESC_LsdLimMod "eLSD torque limit mode ##2G##ESC - ESP_LSD11 - LSD_LIM_MODE";
CM_ SG_ 2244048131 ESC_LsdOpn "eLSD clutch open mode ##2G##ESC - ESP_LSD11 - LSD_OPEN";
CM_ SG_ 2244048131 ESC_LsdTqLim "value of the torquel limit of eLSD ##2G##ESC - ESP_LSD11 - LSD_TQC_LIM";
CM_ SG_ 2244048131 ESC_BcaRPlusSta "ESC_BcaRPlusStatus";
CM_ SG_ 2244048131 ESC_RspaSta "ESC_RspaStatus ##2G##ESC - ESP11 - ESP_RSPA_STAT";
CM_ BO_ 1874 "[TP] Transport Protocol";
CM_ BO_ 1873 "[TP] Transport Protocol";
CM_ BO_ 787 "[PE] Periodic and On Event";
CM_ BO_ 799 "[PE] Periodic and On Event";
CM_ SG_ 799 SBCM_DRV_Crc1Val "SBCM_DRV_CyclicRedundancyCheck1Value";
CM_ SG_ 799 C_ApprOpenStatus "Stop fob searching signal";
CM_ SG_ 799 SBCM_DRV_AlvCnt1Val "SBCM_DRV_AliveCounter1Value";
CM_ SG_ 799 DoorLock_DrvKeyLkSwSta_SBCM "DoorLock_DriverKeyLockSwitchStatus ##2G## -  - C_DrvKeyLockSw";
CM_ SG_ 799 DoorLock_DrvKeyUnLkSwSta_SBCM "DoorLock_DriverKeyUnLockSwitchStatus ##2G## -  - C_DrvKeyUnlockSw";
CM_ SG_ 799 Warn_DrvDrSwSta_SBCM "DoorLock_DriverDoorSwitchStatus ##2G## -  - C_DrvDrSw,CF_Gway_DrvDrSw,Warn_DrvDrSwSta";
CM_ SG_ 799 DoorLock_DrvDrUnLkSta_SBCM "DoorLock_DriverDoorUnLockStatus ##2G## -  - C_DrvUnlockState,CF_Gway_DrvUnlockState";
CM_ SG_ 799 C_DrvDoorApproachOpen "Approach open";
CM_ BO_ 2164277249 "[P] Periodic";
CM_ SG_ 2164277249 TCU_Crc1Val "TCU_CyclicRedundancyCheck1Value";
CM_ SG_ 2164277249 TCU_AlvCnt1Val "TCU_AliveCounter1Value";
CM_ SG_ 2164277249 TCU_GearSlctDis "TCU_GearSelectDisplay";
CM_ SG_ 2164277249 TCU_Typ "TCU_Type";
CM_ SG_ 2164277249 TCU_TqRdctnVal "TCU_TorqueReductionValue";
CM_ SG_ 2164277249 TCU_GearStepTyp "TCU_GearStepType";
CM_ SG_ 2164277249 TCU_GearShftSta "TCU_GearShiftStatus";
CM_ SG_ 2164277249 TCU_TqCnvrtrSta "TCU_TorqueConverterStatus";
CM_ BO_ 2164277250 "[P] Periodic";
CM_ SG_ 2164277250 TCU_CurrGearSta "TCU_CurrentGearStatus";
CM_ SG_ 2164277250 TCH_EngTrgtGearSta "TCU_EngineTargetGear";
CM_ SG_ 2164277250 TCU_EngTqLimVal "TCU_EngineTorqueLimitValue";
CM_ SG_ 2164277250 TCU_CluTrgtGearConfg "Signal source Configuration of  Target gear for CLU";
CM_ SG_ 2164277250 TCU_VehSpdKphVal "TCU_VehicleSpeedKphValue";
CM_ SG_ 2164277250 TCU_TrgtGearSta "TCU_TargetGearStatus";
CM_ SG_ 2164277250 TCU_DcmlVehSpdKphVal "TCU_VehicleSpeedDecimalKphValue";
CM_ SG_ 2164277250 TCU_SprkRtrdReq "TCU_SparkRetardAngleValue";
CM_ SG_ 2164277250 TCU_EngRpmDisSta "TCU_EngineRpmDisplayStatus";
CM_ SG_ 2164277250 TCU_GearLmpBlnkngReq "TCU_GearLampBlinkingRequest";
CM_ SG_ 2164277250 TCU_FuelCutInhbtReq "TCU_FuelCutInhibitionRequest";
CM_ SG_ 2164277250 TCU_IdleUpReq "TCU_IdleUpRequest";
CM_ SG_ 2164277250 TCU_CluTrgtGearSta "TCU_ClusterTargetGear";
CM_ BO_ 2164277251 "[P] Periodic";
CM_ SG_ 2164277251 TCU_EngRpmDis "TCU_EngineRpmDisplay";
CM_ SG_ 2164277251 TCU_SlpVal "TCU_SlopeValue";
CM_ SG_ 2164277251 TCU_EngSpdIncReq "TCU_EngineSpeedIncreaseRequest";
CM_ SG_ 2164277251 TCU_ObdSta "TCU_ObdStatus";
CM_ SG_ 2164277251 TCU_SprtyIndxSta "TCU_SportyIndexStatus";
CM_ SG_ 2164277251 TCU_DrvngModDis "TCU_DrivingModeDisplay";
CM_ SG_ 2164277251 TCU_DrvngModReq "TCU_DrivingModeRequest";
CM_ SG_ 2164277251 TCU_SmrtShftSta "TCU_SmartShiftStatus";
CM_ SG_ 2164277251 TCU_LupTrgtEngSpdVal "TCU_LupTargetEngineSpeedValue";
CM_ SG_ 2164277251 TCU_FrtStcShftSta "TCU_FirstStaticShiftStatus";
CM_ SG_ 2164277251 TCU_IsgInhbtReq "TCU_IsgInhibitRequest";
CM_ SG_ 2164277251 TCU_CdaInhbtReq "TCU_CdaInhibitRequest";
CM_ SG_ 2164277251 TCU_BrkOnReq "TCU_BrakeOnRequest";
CM_ SG_ 2164277251 TCU_TqGrdntLimVal "TCU_TorqueGradientLimitationValue";
CM_ BO_ 2164277252 "[P] Periodic";
CM_ SG_ 2164277252 TCU_NetrlCtrlSta "TCU_NeutralControlStatus";
CM_ SG_ 2164277252 TCU_ShftPtrnSta "TCU_ShiftPatternStatus";
CM_ SG_ 2164277252 TCU_EPBReq "EPB Request signal for prevent P-D Shock on hill";
CM_ SG_ 2164277252 IMT_EOLstate "Gear Display for EOL mode to cluster. This signal is for IMT system only.";
CM_ SG_ 2164277252 IMT_DisCmd "Gear Display type command to cluster . this signal is for IMT system only.";
CM_ SG_ 2164277252 IMT_CltchPdlPos "Clutch Pedal Position. This signal is for IMT system only.";
CM_ SG_ 2164277252 DCT_RegenInhbt "The regen inhibit request from TCU";
CM_ SG_ 2164277252 DCT_EngIdleReq "Engine Idle Request";
CM_ SG_ 2164277252 DCT_CltchState "DCT clutch status";
CM_ SG_ 2164277252 DCT_FuelCutReq "TCU require ECU to perform ¡®Fuel Cut¡¯";
CM_ SG_ 2164277252 DCT_TqIncReq "Request for Torque Increase";
CM_ SG_ 2164277252 DCT_CrpTqReq "Pre-control torque for creeping";
CM_ SG_ 2164277252 DCT_ShftTqReq "Pre-control torque for shifting";
CM_ SG_ 2164277252 TCU_VgisInhbtReq "TCU_VgisInhibitionRequest";
CM_ SG_ 2164277252 TCU_EngTqIncReqVal "TCU_EngineTorqueIncreaseReqValue";
CM_ BO_ 2189467649 "[P] Periodic";
CM_ SG_ 2189467649 WHL_Crc1Val "WHL_CyclicRedundancyCheck1Value";
CM_ SG_ 2189467649 WHL_AlvCnt1Val "WHL_AliveCounter1Value";
CM_ SG_ 2189467649 WHL_PlsFLVal "WHL_PulseFrontLeftValue ##2G##ESC - WHL_PUL11 - WHL_PUL_FL";
CM_ SG_ 2189467649 WHL_PlsFRVal "WHL_PulseFrontRightValue ##2G##ESC - WHL_PUL11 - WHL_PUL_FR";
CM_ SG_ 2189467649 WHL_PlsRLVal "WHL_PulseRearLeftValue ##2G##ESC - WHL_PUL11 - WHL_PUL_RL";
CM_ SG_ 2189467649 WHL_PlsRRVal "WHL_PulseRearRightValue ##2G##ESC - WHL_PUL11 - WHL_PUL_RR";
CM_ SG_ 2189467649 WHL_DirFLVal "WHL_DirectionFrontLeftValue ##2G##ESC - WHL_PUL11 - WHL_DIR_FL";
CM_ SG_ 2189467649 WHL_DirFRVal "WHL_DirectionFrontRightValue ##2G##ESC - WHL_PUL11 - WHL_DIR_FR";
CM_ SG_ 2189467649 WHL_DirRLVal "WHL_DirectionRearLeftValue ##2G##ESC - WHL_PUL11 - WHL_DIR_RL";
CM_ SG_ 2189467649 WHL_DirRRVal "WHL_DirectionRearRightValue ##2G##ESC - WHL_PUL11 - WHL_DIR_RR";
CM_ BO_ 2189467650 "[P] Periodic";
CM_ SG_ 2189467650 WHL_SpdFLVal "WHL_SpeedFrontLeftValue ##2G##ESC - WHL_SPD11 - WHL_SPD_FL";
CM_ SG_ 2189467650 WHL_SpdFRVal "WHL_SpeedFrontRightValue ##2G##ESC - WHL_SPD11 - WHL_SPD_FR";
CM_ SG_ 2189467650 WHL_SpdRLVal "WHL_SpeedRearLeftValue ##2G##ESC - WHL_SPD11 - WHL_SPD_RL";
CM_ SG_ 2189467650 WHL_SpdRRVal "WHL_SpeedRearRightValue ##2G##ESC - WHL_SPD11 - WHL_SPD_RR";
CM_ BO_ 2189467651 "[P] Periodic";
CM_ SG_ 2189467651 WHL_SpdCalParmtr "WHL_SpeedCalculationParameter";
BA_DEF_ BO_ "DiagState" ENUM "No","Yes" ;
BA_DEF_ BO_ "DiagResponse" ENUM "No","Yes" ;
BA_DEF_ BO_ "DiagRequest" ENUM "No","Yes" ;
BA_DEF_ BO_ "TpMessage" ENUM "No","Yes" ;
BA_DEF_ BO_ "UsrMsgIDSforwardDeviation" INT 0 100 ;
BA_DEF_ BO_ "UsrMsgIDSbackwardDeviation" INT 50 1000 ;
BA_DEF_ BO_ "GenMsgCycleTime" INT 0 2000 ;
BA_DEF_ BO_ "GenMsgStartDelayTime" INT 0 2000 ;
BA_DEF_ BO_ "GenMsgSendType" ENUM "Cyclic","NoMsgSendType" ;
BA_DEF_ BO_ "GenMsgCycleTimeFast" INT 0 500 ;
BA_DEF_ BO_ "GenMsgDelayTime" INT 0 20 ;
BA_DEF_ BO_ "GenMsgILSupport" ENUM "No","Yes" ;
BA_DEF_ BO_ "GenMsgNrOfRepetition" INT 0 3 ;
BA_DEF_ BO_ "NmMessage" ENUM "No","Yes" ;
BA_DEF_ BO_ "NWM-Botschaft" ENUM "No","Yes" ;
BA_DEF_ BO_ "TpTxIndex" INT 0 255 ;
BA_DEF_ BO_ "VFrameFormat" ENUM "StandardCAN","ExtendedCAN","reserved","reserved","reserved","reserved","reserved","reserved","reserved","reserved","reserved","reserved","reserved","reserved","StandardCAN_FD","ExtendedCAN_FD" ;
BA_DEF_ SG_ "UserSigValidity" ENUM "B+","ACC","IG","IG1","IG2","IG3","IG1 or IG2","IG1 or IG3","Undef" ;
BA_DEF_ SG_ "TimeoutValue" STRING ;
BA_DEF_ SG_ "UsrSigPurpose" ENUM "Undef","FN","DIAG","DIAG(Req)","DIAG(Res)","DIAG(Phy)","DEV","CCP(Req)","CCP(Res)","NM","TP" ;
BA_DEF_ SG_ "GenSigStartValue" INT 0 1215752192 ;
BA_DEF_ SG_ "NetworkRequest" ENUM "Yes","No" ;
BA_DEF_ SG_ "NetworkRequestHoldingTime" INT 0 65535 ;
BA_DEF_ SG_ "Description" STRING ;
BA_DEF_ SG_ "Version" STRING ;
BA_DEF_ SG_ "GenSigEnvVarType" ENUM "Int","Float","Undef" ;
BA_DEF_ SG_ "GenSigSendType" ENUM "Cyclic","OnWrite","OnWriteWithRepetition","OnChange","OnChangeWithRepetition","IfActive","IfActiveWithRepetition","NoSigSendType","OnChangeAndIfActive","OnChangeAndIfActiveWithRepetition" ;
BA_DEF_ SG_ "GwSigLatencyTime" INT 0 65536 ;
BA_DEF_ SG_ "GwSigMissingSourceType" ENUM "Undef","OldValue","DefaultValue","InitialValue" ;
BA_DEF_ SG_ "NWM-WakeupAllowed" ENUM "<n.a.>" ;
BA_DEF_ SG_ "RoutingFactor" INT 1 1215752192 ;
BA_DEF_REL_ BU_SG_REL_ "GenSigTimeoutTime" INT 0 7000 ;
BA_DEF_DEF_ "DiagState" "No" ;
BA_DEF_DEF_ "DiagResponse" "No" ;
BA_DEF_DEF_ "DiagRequest" "No" ;
BA_DEF_DEF_ "TpMessage" "No" ;
BA_DEF_DEF_ "UsrMsgIDSforwardDeviation" 10 ;
BA_DEF_DEF_ "UsrMsgIDSbackwardDeviation" 100 ;
BA_DEF_DEF_ "GenMsgCycleTime" 200 ;
BA_DEF_DEF_ "GenMsgStartDelayTime" 0 ;
BA_DEF_DEF_ "GenMsgSendType" "NoMsgSendType" ;
BA_DEF_DEF_ "GenMsgCycleTimeFast" 40 ;
BA_DEF_DEF_ "GenMsgDelayTime" 20 ;
BA_DEF_DEF_ "GenMsgILSupport" "Yes" ;
BA_DEF_DEF_ "GenMsgNrOfRepetition" 3 ;
BA_DEF_DEF_ "NmMessage" "No" ;
BA_DEF_DEF_ "NWM-Botschaft" "No" ;
BA_DEF_DEF_ "TpTxIndex" 0 ;
BA_DEF_DEF_ "VFrameFormat" "StandardCAN" ;
BA_DEF_DEF_ "UserSigValidity" "IG" ;
BA_DEF_DEF_ "TimeoutValue" "" ;
BA_DEF_DEF_ "UsrSigPurpose" "FN" ;
BA_DEF_DEF_ "GenSigStartValue" 0 ;
BA_DEF_DEF_ "NetworkRequest" "No" ;
BA_DEF_DEF_ "NetworkRequestHoldingTime" 0 ;
BA_DEF_DEF_ "Description" "" ;
BA_DEF_DEF_ "Version" "" ;
BA_DEF_DEF_ "GenSigEnvVarType" "Undef" ;
BA_DEF_DEF_ "GenSigSendType" "NoSigSendType" ;
BA_DEF_DEF_ "GwSigLatencyTime" 40 ;
BA_DEF_DEF_ "GwSigMissingSourceType" "Undef" ;
BA_DEF_DEF_ "NWM-WakeupAllowed" "<n.a.>" ;
BA_DEF_DEF_ "RoutingFactor" 1 ;
BA_DEF_DEF_REL_ "GenSigTimeoutTime" 500 ;
BA_ "GenMsgSendType" BO_ 2239848449 0;
BA_ "GenMsgCycleTime" BO_ 2239848449 100;
BA_ "GenMsgCycleTimeFast" BO_ 2239848449 0;
BA_ "GenMsgNrOfRepetition" BO_ 2239848449 0;
BA_ "VFrameFormat" BO_ 2239848449 1;
BA_ "Description" SG_ 2239848449 ADAS_CMD_Crc10Val "The data area for CRC calculation is based on the data length (DLC) of the message DB.

The CRC shall be calculated over the entire data block (excluding the CRC bytes) including the user data, alive counter and Data ID

 

- CRC Polynomial (0x1021) , Initial Value : 0xFFFF, XOR value : 0x0000, Data ID : Message ID + 0xF800 

- The initial value is for CRC calculation and the message should be sent with the calculated result value. 

- The mathematical expression to 16 bit CRC polynomial is given here. G(x) = x16 + x12 + x5 + 1";
BA_ "GenSigStartValue" SG_ 2239848449 ADAS_CMD_Crc10Val 65535;
BA_ "UserSigValidity" SG_ 2239848449 ADAS_CMD_Crc10Val 3;
BA_REL_ "GenSigTimeoutTime" BU_SG_REL_ PSB SG_ 2239848449 ADAS_CMD_Crc10Val 1500;
BA_ "RoutingFactor" SG_ 2239848449 ADAS_CMD_Crc10Val 5;
BA_ "Version" SG_ 2239848449 ADAS_CMD_Crc10Val "18.11.08";
BA_ "Description" SG_ 2239848449 ADAS_CMD_AlvCnt10Val "For the first transmission request for a data element the counter shall be initialized with 0 and shall be incremented by 1 for every subsequent send request. 

When the counter reaches the maximum value(0xFF), then it shall restart with 0 for the next send request";
BA_ "UserSigValidity" SG_ 2239848449 ADAS_CMD_AlvCnt10Val 3;
BA_REL_ "GenSigTimeoutTime" BU_SG_REL_ PSB SG_ 2239848449 ADAS_CMD_AlvCnt10Val 1500;
BA_ "RoutingFactor" SG_ 2239848449 ADAS_CMD_AlvCnt10Val 5;
BA_ "Version" SG_ 2239848449 ADAS_CMD_AlvCnt10Val "18.11.08";
BA_ "Description" SG_ 2239848449 FCA_OnOffEquipSta "This signal describes the FCA Function.

- ½Ã½ºÅÛ ÀåÂø ¿©ºÎ ¹× ½Ã½ºÅÛ on/off Á¤º¸";
BA_ "UserSigValidity" SG_ 2239848449 FCA_OnOffEquipSta 3;
BA_REL_ "GenSigTimeoutTime" BU_SG_REL_ PSB SG_ 2239848449 FCA_OnOffEquipSta 1500;
BA_ "RoutingFactor" SG_ 2239848449 FCA_OnOffEquipSta 5;
BA_ "Version" SG_ 2239848449 FCA_OnOffEquipSta "17.12.00";
BA_ "Description" SG_ 2239848449 FCA_SysFlrSta "This signal describes the failure information of FCA Function.

- ½Ã½ºÅÛ Á¤»ó ¶Ç´Â Ä«¸Þ¶ó/·¹ÀÌ´õ/½Ã½ºÅÛ °íÀå»óÅÂ Á¤º¸

0x1: Temporary unavailable by Front View Camera (blockage, high temperature, etc) for Sensor Fusion FCA 

0x2: Temporary unavailable by Front Radar (blockage, high temperature, etc) for either Radar only FCA or Sensor Fusion FCA when logic is in Front Radar

0x3: System failure (Failure by Front View Camera failure, Front Radar failure or relative cooperative control units, etc)

0x4: Temporary unavailable by Front View Camera (blockage, high temperature, etc) for Front View Camera only FCA

0x5: Temporary unavailable of steering function by Front View Camera (blockage, high temperature, etc) for sensor fusion when logic is in ADAS_DRV

0x6: Temporary unavailable by Front Radar (blockage, high temperature, etc) for Sensor Fusion FCA when logic is in Front View Camera";
BA_ "UserSigValidity" SG_ 2239848449 FCA_SysFlrSta 3;
BA_REL_ "GenSigTimeoutTime" BU_SG_REL_ PSB SG_ 2239848449 FCA_SysFlrSta 1500;
BA_ "RoutingFactor" SG_ 2239848449 FCA_SysFlrSta 5;
BA_ "Version" SG_ 2239848449 FCA_SysFlrSta "19.08.04";
BA_ "Description" SG_ 2239848449 FCA_WrngLvlSta "Request CLU to activate the corresponding warning device(s) according to the FCA warning level. (Braking / Steering act)

- FCA ±â´ÉÀÇ Á¦µ¿ ¹× Á¶Çâ Á¦¾î ÀÛµ¿ »óÅÂ Ç¥½Ã¿ë Á¤º¸½ÅÈ£";
BA_ "UserSigValidity" SG_ 2239848449 FCA_WrngLvlSta 3;
BA_REL_ "GenSigTimeoutTime" BU_SG_REL_ SWRC SG_ 2239848449 FCA_WrngLvlSta 1500;
BA_REL_ "GenSigTimeoutTime" BU_SG_REL_ APSU SG_ 2239848449 FCA_WrngLvlSta 1500;
BA_REL_ "GenSigTimeoutTime" BU_SG_REL_ RRPSU SG_ 2239848449 FCA_WrngLvlSta 1500;
BA_REL_ "GenSigTimeoutTime" BU_SG_REL_ RLPSU SG_ 2239848449 FCA_WrngLvlSta 1500;
BA_ "RoutingFactor" SG_ 2239848449 FCA_WrngLvlSta 5;
BA_ "Version" SG_ 2239848449 FCA_WrngLvlSta "19.06.02";
BA_ "Description" SG_ 2239848449 FCA_VehStpReq "A control request flag for vehicle stop. FCA expects vehicle to be controlled to a complete stop and hold its state by ESC.



- FCA Á¦µ¿»óÈ² Á¾·áÈÄ Á¤Â÷ »óÅÂ À¯Áö¸¦ À§ÇÑ ½ÅÈ£";
BA_ "UserSigValidity" SG_ 2239848449 FCA_VehStpReq 3;
BA_REL_ "GenSigTimeoutTime" BU_SG_REL_ SWRC SG_ 2239848449 FCA_VehStpReq 1500;
BA_ "RoutingFactor" SG_ 2239848449 FCA_VehStpReq 5;
BA_ "Version" SG_ 2239848449 FCA_VehStpReq "17.12.00";
BA_ "Description" SG_ 2239848449 FCA_StbltActvReq "Depending on the driving situation, FCA tells PSB to release(no alert), retract or pull the seat belt for occupant protection or warning.

- FCA Á¦µ¿»óÈ²½Ã ½ÃÆ®º§Æ® ÀÛµ¿À» À§ÇÑ Á¤º¸ ½ÅÈ£";
BA_ "UserSigValidity" SG_ 2239848449 FCA_StbltActvReq 3;
BA_REL_ "GenSigTimeoutTime" BU_SG_REL_ PSB SG_ 2239848449 FCA_StbltActvReq 1500;
BA_ "RoutingFactor" SG_ 2239848449 FCA_StbltActvReq 5;
BA_ "Version" SG_ 2239848449 FCA_StbltActvReq "17.12.00";
BA_ "Description" SG_ 2239848449 FCA_HydrlcBstAsstReq "Depending on the driving situation, FCA tells ESC to use lowered HBA (Hydraulic Boost Assist) threshold to sensitize the HBA entrance. 

The boost assist function is more easily activated than under normal driving condition.

- FCA Á¦µ¿»óÈ²½Ã HBA ÀÛµ¿À» À§ÇÑ Á¤º¸ ½ÅÈ£";
BA_ "UserSigValidity" SG_ 2239848449 FCA_HydrlcBstAsstReq 3;
BA_ "RoutingFactor" SG_ 2239848449 FCA_HydrlcBstAsstReq 5;
BA_ "Version" SG_ 2239848449 FCA_HydrlcBstAsstReq "17.12.00";
BA_ "Description" SG_ 2239848449 FCA_DclReqVal "Depending on the driving situation, FCA gives ESC the deceleration command. ESC maintains the deceleration.

- FCA Á¦µ¿À» À§ÇÑ ¿ä±¸ °¨¼Óµµ °ª";
BA_ "UserSigValidity" SG_ 2239848449 FCA_DclReqVal 3;
BA_ "RoutingFactor" SG_ 2239848449 FCA_DclReqVal 5;
BA_ "Version" SG_ 2239848449 FCA_DclReqVal "17.12.00";
BA_ "Description" SG_ 2239848449 FCA_PrefillActvReq "A control requeset flag for FCA first warning. (Audible Warning)

- FCA 1Â÷ Á¦µ¿»óÈ² ¿äÃ»½ÅÈ£";
BA_ "UserSigValidity" SG_ 2239848449 FCA_PrefillActvReq 3;
BA_ "RoutingFactor" SG_ 2239848449 FCA_PrefillActvReq 5;
BA_ "Version" SG_ 2239848449 FCA_PrefillActvReq "17.12.00";
BA_ "Description" SG_ 2239848449 FCA_PartialActvReq "A control requeset flag for FCA second warning. (Partial braking)

- FCA 2Â÷ Á¦µ¿»óÈ² ¿äÃ»½ÅÈ£";
BA_ "UserSigValidity" SG_ 2239848449 FCA_PartialActvReq 3;
BA_ "RoutingFactor" SG_ 2239848449 FCA_PartialActvReq 5;
BA_ "Version" SG_ 2239848449 FCA_PartialActvReq "17.11.00";
BA_ "Description" SG_ 2239848449 FCA_FullActvReq "A control requeset flag for FCA third warning. (Full braking)

- FCA 3Â÷ Á¦µ¿»óÈ² ¿äÃ»½ÅÈ£";
BA_ "UserSigValidity" SG_ 2239848449 FCA_FullActvReq 3;
BA_REL_ "GenSigTimeoutTime" BU_SG_REL_ APSU SG_ 2239848449 FCA_FullActvReq 1500;
BA_REL_ "GenSigTimeoutTime" BU_SG_REL_ RRPSU SG_ 2239848449 FCA_FullActvReq 1500;
BA_REL_ "GenSigTimeoutTime" BU_SG_REL_ RLPSU SG_ 2239848449 FCA_FullActvReq 1500;
BA_ "RoutingFactor" SG_ 2239848449 FCA_FullActvReq 5;
BA_ "Version" SG_ 2239848449 FCA_FullActvReq "17.11.00";
BA_ "Description" SG_ 2239848449 FCA_Regulation "This signal contains FCA regulation compliance information.";
BA_ "UserSigValidity" SG_ 2239848449 FCA_Regulation 3;
BA_ "RoutingFactor" SG_ 2239848449 FCA_Regulation 5;
BA_ "Version" SG_ 2239848449 FCA_Regulation "20.12.01";
BA_ "Description" SG_ 2239848449 FCA_SnstvtyModRetVal "This signal is FCA sensitive set mode switch(USM) info return value to cluster.

- FCA ¹Î°¨µµ ¼³Á¤ °ü·Ã USM ¼³Á¤ ½ºÀ§Ä¡ Á¤º¸ÀÇ ¸®ÅÏ °ª";
BA_ "UserSigValidity" SG_ 2239848449 FCA_SnstvtyModRetVal 3;
BA_ "RoutingFactor" SG_ 2239848449 FCA_SnstvtyModRetVal 5;
BA_ "Version" SG_ 2239848449 FCA_SnstvtyModRetVal "17.12.00";
BA_ "Description" SG_ 2239848449 FCA_WrngSndSta "FCA warning sound status";
BA_ "UserSigValidity" SG_ 2239848449 FCA_WrngSndSta 3;
BA_ "RoutingFactor" SG_ 2239848449 FCA_WrngSndSta 5;
BA_ "Version" SG_ 2239848449 FCA_WrngSndSta "18.12.04";
BA_ "GenMsgSendType" BO_ 2239848450 0;
BA_ "GenMsgCycleTime" BO_ 2239848450 100;
BA_ "GenMsgCycleTimeFast" BO_ 2239848450 0;
BA_ "GenMsgNrOfRepetition" BO_ 2239848450 0;
BA_ "VFrameFormat" BO_ 2239848450 1;
BA_ "Description" SG_ 2239848450 FCA_RelVel "This signal indicates the relative velocity between the host vehicle and a forward vehicle.







(PH) = ((HEX)-0FFH)*0.1 [m/s/digit]



       = (HEX)*0.1 [m/s/digit] - 25.5 [m/s]



CAN Message Physical range : Max. Relative velocity : 0x1FE(25.5m/s), Zero : 0x0FF(0m/s), Min. Relative velocity : 0x000(-25.5m/s)";
BA_ "UserSigValidity" SG_ 2239848450 FCA_RelVel 3;
BA_ "RoutingFactor" SG_ 2239848450 FCA_RelVel 5;
BA_ "Version" SG_ 2239848450 FCA_RelVel "20.02.00";
BA_ "Description" SG_ 2239848450 Nmode_FCAOff_Sta "This signal describes status of FCA off when Nmode on";
BA_ "UserSigValidity" SG_ 2239848450 Nmode_FCAOff_Sta 3;
BA_ "RoutingFactor" SG_ 2239848450 Nmode_FCAOff_Sta 5;
BA_ "Version" SG_ 2239848450 Nmode_FCAOff_Sta "17.12.00";
BA_ "Description" SG_ 2239848450 FCA_Jnctn_OnOffEquipSta "This signal describes the FCA-JC Function.

- ½Ã½ºÅÛ ÀåÂø ¿©ºÎ ¹× ½Ã½ºÅÛ on/off Á¤º¸";
BA_ "UserSigValidity" SG_ 2239848450 FCA_Jnctn_OnOffEquipSta 3;
BA_REL_ "GenSigTimeoutTime" BU_SG_REL_ PSB SG_ 2239848450 FCA_Jnctn_OnOffEquipSta 1500;
BA_ "RoutingFactor" SG_ 2239848450 FCA_Jnctn_OnOffEquipSta 5;
BA_ "Version" SG_ 2239848450 FCA_Jnctn_OnOffEquipSta "17.11.00";
BA_ "Description" SG_ 2239848450 HDP_EMOpSta "EM On (Not Active/Active), Off status";
BA_ "UserSigValidity" SG_ 2239848450 HDP_EMOpSta 3;
BA_ "RoutingFactor" SG_ 2239848450 HDP_EMOpSta 5;
BA_ "Version" SG_ 2239848450 HDP_EMOpSta "20.06.05";
BA_ "Description" SG_ 2239848450 FCA_WrngTrgtDis "Request CLU to activate the corresponding warning device(s) according to the type of FCA warning target.

- FCA °æ°í ´ë»ó Á¾·ùº° Ç¥½Ã Á¤º¸½ÅÈ£";
BA_ "UserSigValidity" SG_ 2239848450 FCA_WrngTrgtDis 3;
BA_REL_ "GenSigTimeoutTime" BU_SG_REL_ APSU SG_ 2239848450 FCA_WrngTrgtDis 1500;
BA_ "RoutingFactor" SG_ 2239848450 FCA_WrngTrgtDis 5;
BA_ "Version" SG_ 2239848450 FCA_WrngTrgtDis "19.03.06";
BA_ "Description" SG_ 2239848450 ADAS_DRV_FCA_Plus_Sta "Àü¹æÄ«¸Þ¶ó, Àü¹æ·¹ÀÌ´õ ¹× ÀüÃø¹æ ·¹ÀÌ´õ/ÈÄÃø¹æ ·¹ÀÌÅÍ Ç»Àü Æ®·¢À» ÅëÇØ FCA-Car Å¸°Ù ¹× ÀÚÂ÷ ÁÂÃø/¿ìÃø ¿µ¿ª È¸ÇÇ ºÒ°¡´É ¿©ºÎ¸¦ ÆÇ´ÜÇÏ¿© FCA-Car/Ped/Cyc+ Flag¸¦ Ãâ·ÂÇÔ";
BA_ "UserSigValidity" SG_ 2239848450 ADAS_DRV_FCA_Plus_Sta 3;
BA_ "RoutingFactor" SG_ 2239848450 ADAS_DRV_FCA_Plus_Sta 5;
BA_ "Version" SG_ 2239848450 ADAS_DRV_FCA_Plus_Sta "18.08.06";
BA_ "Description" SG_ 2239848450 ADAS_TrlOffStaDisp "This signal describes ADAS system automatically off by trailer connected.";
BA_ "UserSigValidity" SG_ 2239848450 ADAS_TrlOffStaDisp 3;
BA_ "RoutingFactor" SG_ 2239848450 ADAS_TrlOffStaDisp 5;
BA_ "Version" SG_ 2239848450 ADAS_TrlOffStaDisp "20.12.01";
BA_ "Description" SG_ 2239848450 FCA_FrOnOffEquipSta "This signal describes the FCA-Car/Ped/Cyc/JT state.

- Front Camera Only: FCA-Car/Ped/Cyc

- Sensor Fusion: FCA-Car/Ped/Cyc/JT



 FCA-Car/Ped/Cyc/JT Àû¿ë ¿©ºÎ ¹× On/Off Á¤º¸

- Àü¹æ Ä«¸Þ¶ó ´Üµ¶: FCA-Car/Ped/Cyc

- ¼¾¼­Ç»Àü: FCA-Car/Ped/Cyc/JT";
BA_ "UserSigValidity" SG_ 2239848450 FCA_FrOnOffEquipSta 3;
BA_ "RoutingFactor" SG_ 2239848450 FCA_FrOnOffEquipSta 5;
BA_ "Version" SG_ 2239848450 FCA_FrOnOffEquipSta "20.12.03";
BA_ "Description" SG_ 2239848450 FCA_JC_OnOffEquipSta "This signal describes the FCA-JC state.

 - FCA-JC Àû¿ë ¿©ºÎ ¹× On/Off Á¤º¸";
BA_ "UserSigValidity" SG_ 2239848450 FCA_JC_OnOffEquipSta 3;
BA_ "RoutingFactor" SG_ 2239848450 FCA_JC_OnOffEquipSta 5;
BA_ "Version" SG_ 2239848450 FCA_JC_OnOffEquipSta "20.12.03";
BA_ "Description" SG_ 2239848450 FCA_FrSdOnOffEquipSta "This signal describes the FCA-LO/LS, w/ ESA state.

 - FCA-LO/LS, w/ ESA Àû¿ë ¿©ºÎ ¹×  On/Off Á¤º¸";
BA_ "UserSigValidity" SG_ 2239848450 FCA_FrSdOnOffEquipSta 3;
BA_ "RoutingFactor" SG_ 2239848450 FCA_FrSdOnOffEquipSta 5;
BA_ "Version" SG_ 2239848450 FCA_FrSdOnOffEquipSta "20.12.03";
BA_ "Description" SG_ 2239848450 EM_WrngLvlSta "Request CLU to activate the corresponding warning device(s) according to the EM warning level. (Braking / Steering act)

- EM ±â´ÉÀÇ Á¦µ¿ ¹× Á¶Çâ Á¦¾î ÀÛµ¿ »óÅÂ Ç¥½Ã¿ë Á¤º¸½ÅÈ£";
BA_ "UserSigValidity" SG_ 2239848450 EM_WrngLvlSta 3;
BA_ "RoutingFactor" SG_ 2239848450 EM_WrngLvlSta 5;
BA_ "Version" SG_ 2239848450 EM_WrngLvlSta "19.12.00";
BA_ "Description" SG_ 2239848450 BrkDelVLimReq "- Request ESC whether to release brake control or not when FCA or EM function reduces vehicle¡¯s velocity over 50km/h for ISO 26262.

- FCA ¶Ç´Â EM ÀÛµ¿ Áß ESC°¡ 50km/h ÃÊ°ú °¨¼Ó ½Ã Á¦µ¿Á¦¾î ÇØÁ¦/¹ÌÇØÁ¦ ¿äÃ» ½ÅÈ£ (ISO 26262 ´ëÀÀ)";
BA_ "UserSigValidity" SG_ 2239848450 BrkDelVLimReq 3;
BA_ "RoutingFactor" SG_ 2239848450 BrkDelVLimReq 5;
BA_ "Version" SG_ 2239848450 BrkDelVLimReq "20.03.00";
BA_ "Description" SG_ 2239848450 ADAS_InhbtOffDispSta "This Signal dispaly the ADAS System off inhibition state 

- »óÈ²¿¡ µû¸¥ ADAS ½Ã½ºÅÛ ²ô±â ±ÝÁö »óÅÂ Ç¥½Ã ½ÅÈ£";
BA_ "UserSigValidity" SG_ 2239848450 ADAS_InhbtOffDispSta 3;
BA_ "RoutingFactor" SG_ 2239848450 ADAS_InhbtOffDispSta 5;
BA_ "Version" SG_ 2239848450 ADAS_InhbtOffDispSta "20.12.00";
BA_ "Description" SG_ 2239848450 FCA_WarnTimeSta "This signal describes the FCA warning timing state.

 - FCA °æ°í ½ÃÁ¡ Á¤º¸";
BA_ "UserSigValidity" SG_ 2239848450 FCA_WarnTimeSta 3;
BA_ "RoutingFactor" SG_ 2239848450 FCA_WarnTimeSta 5;
BA_ "Version" SG_ 2239848450 FCA_WarnTimeSta "20.12.00";
BA_ "Description" SG_ 2239848450 FCA_TimetoCllsn "This signal indicates predictive time to Collision between the host vehicle and a forward vehicle.







(PH) = 10*(HEX) [ms]



CAN Message Physical range : 0 ~ 2540 [ms], Resolution : 10ms";
BA_ "GenSigStartValue" SG_ 2239848450 FCA_TimetoCllsn 254;
BA_ "UserSigValidity" SG_ 2239848450 FCA_TimetoCllsn 3;
BA_ "RoutingFactor" SG_ 2239848450 FCA_TimetoCllsn 5;
BA_ "Version" SG_ 2239848450 FCA_TimetoCllsn "19.06.03";
BA_ "GenMsgSendType" BO_ 788 0;
BA_ "Description" SG_ 788 APSU_AstSlidePosition "ASSIST SEAT SLIDE POSITION (UNIT: mm)";
BA_ "GenSigSendType" SG_ 788 APSU_AstSlidePosition 4;
BA_ "UserSigValidity" SG_ 788 APSU_AstSlidePosition 0;
BA_REL_ "GenSigTimeoutTime" BU_SG_REL_ CGW_CCU SG_ 788 APSU_AstSlidePosition 1500;
BA_ "NetworkRequest" SG_ 788 APSU_AstSlidePosition 0;
BA_ "NetworkRequestHoldingTime" SG_ 788 APSU_AstSlidePosition 5000;
BA_ "Version" SG_ 788 APSU_AstSlidePosition "22.02.05";
BA_ "Description" SG_ 788 APSU_AstHeightPosition "ASSIST SEAT HEIGHT POSITION (UNIT: mm)";
BA_ "GenSigSendType" SG_ 788 APSU_AstHeightPosition 4;
BA_ "UserSigValidity" SG_ 788 APSU_AstHeightPosition 0;
BA_REL_ "GenSigTimeoutTime" BU_SG_REL_ CGW_CCU SG_ 788 APSU_AstHeightPosition 1500;
BA_ "NetworkRequest" SG_ 788 APSU_AstHeightPosition 0;
BA_ "NetworkRequestHoldingTime" SG_ 788 APSU_AstHeightPosition 5000;
BA_ "Version" SG_ 788 APSU_AstHeightPosition "22.02.05";
BA_ "Description" SG_ 788 APSU_AstReclinePosition "ASSIST SEAT RECLINE POSITION (UNIT: ¢ª)";
BA_ "GenSigSendType" SG_ 788 APSU_AstReclinePosition 4;
BA_ "UserSigValidity" SG_ 788 APSU_AstReclinePosition 0;
BA_REL_ "GenSigTimeoutTime" BU_SG_REL_ CGW_CCU SG_ 788 APSU_AstReclinePosition 1500;
BA_ "NetworkRequest" SG_ 788 APSU_AstReclinePosition 0;
BA_ "NetworkRequestHoldingTime" SG_ 788 APSU_AstReclinePosition 5000;
BA_ "Version" SG_ 788 APSU_AstReclinePosition "22.02.05";
BA_ "Description" SG_ 788 APSU_AstRelaxTiltPosition "DRIVER SEAT RELAX TILT POSITION (UNIT: ¢ª)";
BA_ "GenSigSendType" SG_ 788 APSU_AstRelaxTiltPosition 4;
BA_ "UserSigValidity" SG_ 788 APSU_AstRelaxTiltPosition 0;
BA_REL_ "GenSigTimeoutTime" BU_SG_REL_ CGW_CCU SG_ 788 APSU_AstRelaxTiltPosition 1500;
BA_ "NetworkRequest" SG_ 788 APSU_AstRelaxTiltPosition 0;
BA_ "NetworkRequestHoldingTime" SG_ 788 APSU_AstRelaxTiltPosition 5000;
BA_ "Version" SG_ 788 APSU_AstRelaxTiltPosition "22.02.05";
BA_ "GenMsgSendType" BO_ 271 0;
BA_ "Description" SG_ 271 ASAU_AirSptTimeRValueSet "Air Support Time(Massage Time) USM R Value";
BA_ "GenSigSendType" SG_ 271 ASAU_AirSptTimeRValueSet 4;
BA_ "UserSigValidity" SG_ 271 ASAU_AirSptTimeRValueSet 3;
BA_REL_ "GenSigTimeoutTime" BU_SG_REL_ CGW_CCU SG_ 271 ASAU_AirSptTimeRValueSet 1500;
BA_ "NetworkRequest" SG_ 271 ASAU_AirSptTimeRValueSet 0;
BA_ "NetworkRequestHoldingTime" SG_ 271 ASAU_AirSptTimeRValueSet 5000;
BA_ "Version" SG_ 271 ASAU_AirSptTimeRValueSet "19.11.06";
BA_ "Description" SG_ 271 ASAU_AstSmtAirSptRValueSet "Seat Smart Air Support Function USM R Value";
BA_ "GenSigSendType" SG_ 271 ASAU_AstSmtAirSptRValueSet 4;
BA_ "UserSigValidity" SG_ 271 ASAU_AstSmtAirSptRValueSet 3;
BA_REL_ "GenSigTimeoutTime" BU_SG_REL_ CGW_CCU SG_ 271 ASAU_AstSmtAirSptRValueSet 1500;
BA_ "NetworkRequest" SG_ 271 ASAU_AstSmtAirSptRValueSet 0;
BA_ "NetworkRequestHoldingTime" SG_ 271 ASAU_AstSmtAirSptRValueSet 5000;
BA_ "Version" SG_ 271 ASAU_AstSmtAirSptRValueSet "19.12.00";
BA_ "Description" SG_ 271 ASAU_CushSoftRValueSet "Cushion Soft R Value";
BA_ "GenSigSendType" SG_ 271 ASAU_CushSoftRValueSet 4;
BA_ "UserSigValidity" SG_ 271 ASAU_CushSoftRValueSet 3;
BA_REL_ "GenSigTimeoutTime" BU_SG_REL_ CGW_CCU SG_ 271 ASAU_CushSoftRValueSet 1500;
BA_ "NetworkRequest" SG_ 271 ASAU_CushSoftRValueSet 0;
BA_ "NetworkRequestHoldingTime" SG_ 271 ASAU_CushSoftRValueSet 5000;
BA_ "Version" SG_ 271 ASAU_CushSoftRValueSet "20.04.02";
BA_ "Description" SG_ 271 ASAU_BackSoftRValueSet "Back Soft USM R Value";
BA_ "GenSigSendType" SG_ 271 ASAU_BackSoftRValueSet 4;
BA_ "UserSigValidity" SG_ 271 ASAU_BackSoftRValueSet 3;
BA_REL_ "GenSigTimeoutTime" BU_SG_REL_ CGW_CCU SG_ 271 ASAU_BackSoftRValueSet 1500;
BA_ "NetworkRequest" SG_ 271 ASAU_BackSoftRValueSet 0;
BA_ "NetworkRequestHoldingTime" SG_ 271 ASAU_BackSoftRValueSet 5000;
BA_ "Version" SG_ 271 ASAU_BackSoftRValueSet "20.04.02";
BA_ "Description" SG_ 271 ASAU_AirSptModeRValueSet "Air Support Mode(Massage Mode) USM R Value";
BA_ "GenSigSendType" SG_ 271 ASAU_AirSptModeRValueSet 4;
BA_ "UserSigValidity" SG_ 271 ASAU_AirSptModeRValueSet 3;
BA_REL_ "GenSigTimeoutTime" BU_SG_REL_ CGW_CCU SG_ 271 ASAU_AirSptModeRValueSet 1500;
BA_ "NetworkRequest" SG_ 271 ASAU_AirSptModeRValueSet 0;
BA_ "NetworkRequestHoldingTime" SG_ 271 ASAU_AirSptModeRValueSet 5000;
BA_ "Version" SG_ 271 ASAU_AirSptModeRValueSet "19.11.06";
BA_ "Description" SG_ 271 ASAU_NotFootMsgOperStaWarnPE "Passenger Foot Massage Operation Disable Mode";
BA_ "GenSigSendType" SG_ 271 ASAU_NotFootMsgOperStaWarnPE 4;
BA_ "UserSigValidity" SG_ 271 ASAU_NotFootMsgOperStaWarnPE 3;
BA_REL_ "GenSigTimeoutTime" BU_SG_REL_ ATS SG_ 271 ASAU_NotFootMsgOperStaWarnPE 1500;
BA_ "NetworkRequest" SG_ 271 ASAU_NotFootMsgOperStaWarnPE 0;
BA_ "NetworkRequestHoldingTime" SG_ 271 ASAU_NotFootMsgOperStaWarnPE 5000;
BA_ "Version" SG_ 271 ASAU_NotFootMsgOperStaWarnPE "20.08.00";
BA_ "Description" SG_ 271 ASAU_RRFootAirSptRValueSet "Foot Air Support USM R Value";
BA_ "GenSigSendType" SG_ 271 ASAU_RRFootAirSptRValueSet 4;
BA_ "UserSigValidity" SG_ 271 ASAU_RRFootAirSptRValueSet 3;
BA_REL_ "GenSigTimeoutTime" BU_SG_REL_ ATS SG_ 271 ASAU_RRFootAirSptRValueSet 1500;
BA_ "NetworkRequest" SG_ 271 ASAU_RRFootAirSptRValueSet 0;
BA_ "NetworkRequestHoldingTime" SG_ 271 ASAU_RRFootAirSptRValueSet 5000;
BA_ "Version" SG_ 271 ASAU_RRFootAirSptRValueSet "19.12.00";
BA_ "Description" SG_ 271 ASAU_RRFootAirSptHeatRValueSet "Foot Air Support Heat USM R Value";
BA_ "GenSigSendType" SG_ 271 ASAU_RRFootAirSptHeatRValueSet 4;
BA_ "UserSigValidity" SG_ 271 ASAU_RRFootAirSptHeatRValueSet 3;
BA_REL_ "GenSigTimeoutTime" BU_SG_REL_ ATS SG_ 271 ASAU_RRFootAirSptHeatRValueSet 1500;
BA_ "NetworkRequest" SG_ 271 ASAU_RRFootAirSptHeatRValueSet 0;
BA_ "NetworkRequestHoldingTime" SG_ 271 ASAU_RRFootAirSptHeatRValueSet 5000;
BA_ "Version" SG_ 271 ASAU_RRFootAirSptHeatRValueSet "20.01.02";
BA_ "Description" SG_ 271 ASAU_MoodTrpyRValueSet "Passenger Seat Mood Therapy R Value";
BA_ "GenSigSendType" SG_ 271 ASAU_MoodTrpyRValueSet 4;
BA_ "UserSigValidity" SG_ 271 ASAU_MoodTrpyRValueSet 3;
BA_REL_ "GenSigTimeoutTime" BU_SG_REL_ CGW_CCU SG_ 271 ASAU_MoodTrpyRValueSet 1500;
BA_ "NetworkRequest" SG_ 271 ASAU_MoodTrpyRValueSet 0;
BA_ "NetworkRequestHoldingTime" SG_ 271 ASAU_MoodTrpyRValueSet 5000;
BA_ "Version" SG_ 271 ASAU_MoodTrpyRValueSet "20.07.03";
BA_ "Description" SG_ 271 ASAU_MoodTrpyCareSta "Passenger Seat Mood Therapy Care Mode R Value";
BA_ "GenSigSendType" SG_ 271 ASAU_MoodTrpyCareSta 4;
BA_ "UserSigValidity" SG_ 271 ASAU_MoodTrpyCareSta 3;
BA_REL_ "GenSigTimeoutTime" BU_SG_REL_ CGW_CCU SG_ 271 ASAU_MoodTrpyCareSta 1500;
BA_ "NetworkRequest" SG_ 271 ASAU_MoodTrpyCareSta 0;
BA_ "NetworkRequestHoldingTime" SG_ 271 ASAU_MoodTrpyCareSta 5000;
BA_ "Version" SG_ 271 ASAU_MoodTrpyCareSta "20.07.12";
BA_ "Description" SG_ 271 ASAU_MoodTrpyComfSta "Passenger Seat Mood Therapy Comfort Mode R Value";
BA_ "GenSigSendType" SG_ 271 ASAU_MoodTrpyComfSta 4;
BA_ "UserSigValidity" SG_ 271 ASAU_MoodTrpyComfSta 3;
BA_REL_ "GenSigTimeoutTime" BU_SG_REL_ CGW_CCU SG_ 271 ASAU_MoodTrpyComfSta 1500;
BA_ "NetworkRequest" SG_ 271 ASAU_MoodTrpyComfSta 0;
BA_ "NetworkRequestHoldingTime" SG_ 271 ASAU_MoodTrpyComfSta 5000;
BA_ "Version" SG_ 271 ASAU_MoodTrpyComfSta "20.07.12";
BA_ "Description" SG_ 271 ASAU_AirSptStrRValueSet "Air Support Strenth(Massage Strenth) USM R Value";
BA_ "GenSigSendType" SG_ 271 ASAU_AirSptStrRValueSet 4;
BA_ "UserSigValidity" SG_ 271 ASAU_AirSptStrRValueSet 3;
BA_REL_ "GenSigTimeoutTime" BU_SG_REL_ CGW_CCU SG_ 271 ASAU_AirSptStrRValueSet 1500;
BA_ "NetworkRequest" SG_ 271 ASAU_AirSptStrRValueSet 0;
BA_ "NetworkRequestHoldingTime" SG_ 271 ASAU_AirSptStrRValueSet 5000;
BA_ "Version" SG_ 271 ASAU_AirSptStrRValueSet "20.07.11";
BA_ "GenMsgSendType" BO_ 2395189761 0;
BA_ "VFrameFormat" BO_ 2395189761 1;
BA_ "Description" SG_ 2395189761 DATC_Crc10Val "The data area for CRC calculation is based on the data length (DLC) of the message DB.

The CRC shall be calculated over the entire data block (excluding the CRC bytes) including the user data, alive counter and Data ID

 

- CRC Polynomial (0x1021) , Initial Value : 0xFFFF, XOR value : 0x0000, Data ID : Message ID + 0xF800 

- The initial value is for CRC calculation and the message should be sent with the calculated result value. 

- The mathematical expression to 16 bit CRC polynomial is given here. G(x) = x16 + x12 + x5 + 1";
BA_ "GenSigSendType" SG_ 2395189761 DATC_Crc10Val 4;
BA_ "GenSigStartValue" SG_ 2395189761 DATC_Crc10Val 65535;
BA_ "UserSigValidity" SG_ 2395189761 DATC_Crc10Val 3;
BA_ "Version" SG_ 2395189761 DATC_Crc10Val "18.11.08";
BA_ "Description" SG_ 2395189761 DATC_AlvCnt10Val "For the first transmission request for a data element the counter shall be initialized with 0 and shall be incremented by 1 for every subsequent send request. 

When the counter reaches the maximum value(0xFF), then it shall restart with 0 for the next send request";
BA_ "GenSigSendType" SG_ 2395189761 DATC_AlvCnt10Val 4;
BA_ "UserSigValidity" SG_ 2395189761 DATC_AlvCnt10Val 3;
BA_ "Version" SG_ 2395189761 DATC_AlvCnt10Val "18.11.08";
BA_ "Description" SG_ 2395189761 DATC_Typ "HTR CONTROL TYPE

Bit0 (FR Control) : 0 ? ATC / 1 ? MTC

Bit1~2 (Temp) : 0 ? Single / 1 ? Dual / 2 ? 3Zone / 3 ? 4Zone

Bit3~4 (Mode) : 0 ? Single / 1 ? Dual / 2 ? 3Zone / 3 ? 4Zone

Bit5 (Rear Control) : 0 ? None or MTC / 1- ATC

Bit6 (RHD) : 0 ? LHD / 1 ? RHD

Bit7 (EU) : 0 ? Others / 1 ? EU";
BA_ "GenSigSendType" SG_ 2395189761 DATC_Typ 4;
BA_ "UserSigValidity" SG_ 2395189761 DATC_Typ 3;
BA_REL_ "GenSigTimeoutTime" BU_SG_REL_ RLHV SG_ 2395189761 DATC_Typ 1500;
BA_REL_ "GenSigTimeoutTime" BU_SG_REL_ RRHV SG_ 2395189761 DATC_Typ 1500;
BA_REL_ "GenSigTimeoutTime" BU_SG_REL_ SHVU_FR SG_ 2395189761 DATC_Typ 1500;
BA_REL_ "GenSigTimeoutTime" BU_SG_REL_ SHVU_RR SG_ 2395189761 DATC_Typ 1500;
BA_REL_ "GenSigTimeoutTime" BU_SG_REL_ ATS SG_ 2395189761 DATC_Typ 1500;
BA_ "Version" SG_ 2395189761 DATC_Typ "20.03.01";
BA_ "Description" SG_ 2395189761 DATC_Opt1Typ "Bit0 : (ADS) : 0 - Non ADS / 1 - ADS

Bit1 : (AQS) : 0 - Non AQS / 1 ? AQS

Bit2 : (MAX AC) : 0 - Non MAX AC / 1 - MAX AC

Bit3 : (SYNC) : 0 - Non SYNC / 1 - SYNC

Bit4 : (DUST) : 0 - Non AIR PURIFIER / 1 - AIR PURIFIER

Bit5 : (Smart_Vent) : 0 - Non SMART VENT / 1 ? SMART VENT

Bit6 : (CO2) : 0 - Non CO2 / 1 - CO2

Bit7 : (REAR LOCK) : 0 - NON REAR LOCK / 1 - REAR LOCK

HTR CONTROL OPTION";
BA_ "GenSigSendType" SG_ 2395189761 DATC_Opt1Typ 4;
BA_ "UserSigValidity" SG_ 2395189761 DATC_Opt1Typ 3;
BA_REL_ "GenSigTimeoutTime" BU_SG_REL_ ATS SG_ 2395189761 DATC_Opt1Typ 1500;
BA_ "Version" SG_ 2395189761 DATC_Opt1Typ "18.05.00";
BA_ "Description" SG_ 2395189761 DATC_Opt3Typ "This signal indicates Option of HTR Control.



Bit0~1 (Button Type)  : 0 ? Not Display in AVN /

                              1 ? Single (Blower-Temp-Mode) /

                              2 ? Single (Temp-Mode-Blower) / 

                              3 ? Dual ¡¤ 3zone ¡¤ 4zone / 

Bit2 : 0 - Defogging USM Not Apply / 1 - Defogging USM Apply 

Bit3 : 0 - Automatic Ventilation USM Not Apply / 1 - Automatic Ventilation USM Apply

Bit4 : 0 ? Auto AirCleaningSystem USM Not Apply / 1 - Auto AirCleaningSystem USM Apply

Bit5 : 0 ? Washer fluid Control USM Not Apply / 1 - Washer fluid Control USM Apply

Bit6~7 : 0 - Haptic Intensity USM Not Apply 

              1 - Haptic Intensity USM Apply (3-Level)

              2 - Haptic Intensity USM Apply (5-Level)

              3 - Reserved

0xFF : Invalid";
BA_ "GenSigSendType" SG_ 2395189761 DATC_Opt3Typ 4;
BA_ "UserSigValidity" SG_ 2395189761 DATC_Opt3Typ 3;
BA_REL_ "GenSigTimeoutTime" BU_SG_REL_ ATS SG_ 2395189761 DATC_Opt3Typ 1500;
BA_ "Version" SG_ 2395189761 DATC_Opt3Typ "18.11.00";
BA_ "Description" SG_ 2395189761 DATC_Opt2Typ "Bit0 : (FRONT BLOWER) : 0 - SINGLE BLOWER / 1 ? DUAL BLOWER

Bit1 : (FRONT AUTO ZONE) : 0 - SINGLE AUTO / 1 - DUAL AUTO

Bit2 : (LCD / NON LCD TYPE) : 0 - NON LCD /  1 - LCD TYPE

Bit3 : (INDIRECT VENT) : 0 - NON INDIRECT VENT /  1 - INDIRECT VENT

HTR CONTROL OPTION";
BA_ "GenSigSendType" SG_ 2395189761 DATC_Opt2Typ 4;
BA_ "UserSigValidity" SG_ 2395189761 DATC_Opt2Typ 3;
BA_REL_ "GenSigTimeoutTime" BU_SG_REL_ ATS SG_ 2395189761 DATC_Opt2Typ 1500;
BA_ "Version" SG_ 2395189761 DATC_Opt2Typ "19.04.06";
BA_ "Description" SG_ 2395189761 DATC_Opt4Typ "This signal indicates Option of HTR Control.



Bit0 (Driver Only Button) :  0 ? NOT Apply / 1 ? Apply

Bit1 (HEAT Button) :  0 ? NOT Apply / 1 ? Apply

Bit2 (Multi-Air Mode) : 0 ? Not Apply / 1 - Apply

Bit3 : (Scheduled Ventilation) : 0 ? Not Apply / 1 ? Apply

0xF : invalid";
BA_ "GenSigSendType" SG_ 2395189761 DATC_Opt4Typ 4;
BA_ "UserSigValidity" SG_ 2395189761 DATC_Opt4Typ 7;
BA_REL_ "GenSigTimeoutTime" BU_SG_REL_ ATS SG_ 2395189761 DATC_Opt4Typ 1500;
BA_ "Version" SG_ 2395189761 DATC_Opt4Typ "19.08.08";
BA_ "Description" SG_ 2395189761 DATC_TxtPopupReq "DATC TEXT Pop-up";
BA_ "GenSigSendType" SG_ 2395189761 DATC_TxtPopupReq 4;
BA_ "UserSigValidity" SG_ 2395189761 DATC_TxtPopupReq 3;
BA_ "Version" SG_ 2395189761 DATC_TxtPopupReq "17.11.00";
BA_ "Description" SG_ 2395189761 DATC_StrWhlUSMSta "DATC and Steering Wheel heat Control Display request signal";
BA_ "GenSigSendType" SG_ 2395189761 DATC_StrWhlUSMSta 4;
BA_ "UserSigValidity" SG_ 2395189761 DATC_StrWhlUSMSta 3;
BA_REL_ "GenSigTimeoutTime" BU_SG_REL_ APSU SG_ 2395189761 DATC_StrWhlUSMSta 1500;
BA_ "Version" SG_ 2395189761 DATC_StrWhlUSMSta "18.03.05";
BA_ "Description" SG_ 2395189761 DATC_StrWhlHtngReq "Steering Wheel heat function on/off request";
BA_ "GenSigSendType" SG_ 2395189761 DATC_StrWhlHtngReq 4;
BA_ "UserSigValidity" SG_ 2395189761 DATC_StrWhlHtngReq 3;
BA_ "Version" SG_ 2395189761 DATC_StrWhlHtngReq "18.01.07";
BA_ "GenMsgCycleTime" BO_ 1882 0;
BA_ "GenMsgCycleTimeFast" BO_ 1882 0;
BA_ "GenMsgNrOfRepetition" BO_ 1882 0;
BA_ "DiagResponse" BO_ 1882 1;
BA_ "GenMsgILSupport" BO_ 1882 0;
BA_ "TpMessage" BO_ 1882 1;
BA_ "TpTxIndex" BO_ 1882 121;
BA_ "Description" SG_ 1882 DLBCU_GST_Byte0 "TP Index : 121";
BA_ "UsrSigPurpose" SG_ 1882 DLBCU_GST_Byte0 4;
BA_ "UserSigValidity" SG_ 1882 DLBCU_GST_Byte0 0;
BA_REL_ "GenSigTimeoutTime" BU_SG_REL_ CGW_CCU SG_ 1882 DLBCU_GST_Byte0 0;
BA_ "NetworkRequest" SG_ 1882 DLBCU_GST_Byte0 0;
BA_ "NetworkRequestHoldingTime" SG_ 1882 DLBCU_GST_Byte0 5000;
BA_ "Version" SG_ 1882 DLBCU_GST_Byte0 "21.02.04";
BA_ "Description" SG_ 1882 DLBCU_GST_Byte2 "TP Index : 121";
BA_ "UsrSigPurpose" SG_ 1882 DLBCU_GST_Byte2 4;
BA_ "UserSigValidity" SG_ 1882 DLBCU_GST_Byte2 0;
BA_REL_ "GenSigTimeoutTime" BU_SG_REL_ CGW_CCU SG_ 1882 DLBCU_GST_Byte2 0;
BA_ "NetworkRequest" SG_ 1882 DLBCU_GST_Byte2 0;
BA_ "NetworkRequestHoldingTime" SG_ 1882 DLBCU_GST_Byte2 5000;
BA_ "Version" SG_ 1882 DLBCU_GST_Byte2 "21.02.04";
BA_ "Description" SG_ 1882 DLBCU_GST_Byte3 "TP Index : 121";
BA_ "UsrSigPurpose" SG_ 1882 DLBCU_GST_Byte3 4;
BA_ "UserSigValidity" SG_ 1882 DLBCU_GST_Byte3 0;
BA_REL_ "GenSigTimeoutTime" BU_SG_REL_ CGW_CCU SG_ 1882 DLBCU_GST_Byte3 0;
BA_ "NetworkRequest" SG_ 1882 DLBCU_GST_Byte3 0;
BA_ "NetworkRequestHoldingTime" SG_ 1882 DLBCU_GST_Byte3 5000;
BA_ "Version" SG_ 1882 DLBCU_GST_Byte3 "21.02.04";
BA_ "Description" SG_ 1882 DLBCU_GST_Byte4 "TP Index : 121";
BA_ "UsrSigPurpose" SG_ 1882 DLBCU_GST_Byte4 4;
BA_ "UserSigValidity" SG_ 1882 DLBCU_GST_Byte4 0;
BA_REL_ "GenSigTimeoutTime" BU_SG_REL_ CGW_CCU SG_ 1882 DLBCU_GST_Byte4 0;
BA_ "NetworkRequest" SG_ 1882 DLBCU_GST_Byte4 0;
BA_ "NetworkRequestHoldingTime" SG_ 1882 DLBCU_GST_Byte4 5000;
BA_ "Version" SG_ 1882 DLBCU_GST_Byte4 "21.02.04";
BA_ "Description" SG_ 1882 DLBCU_GST_Byte5 "TP Index : 121";
BA_ "UsrSigPurpose" SG_ 1882 DLBCU_GST_Byte5 4;
BA_ "UserSigValidity" SG_ 1882 DLBCU_GST_Byte5 0;
BA_REL_ "GenSigTimeoutTime" BU_SG_REL_ CGW_CCU SG_ 1882 DLBCU_GST_Byte5 0;
BA_ "NetworkRequest" SG_ 1882 DLBCU_GST_Byte5 0;
BA_ "NetworkRequestHoldingTime" SG_ 1882 DLBCU_GST_Byte5 5000;
BA_ "Version" SG_ 1882 DLBCU_GST_Byte5 "21.02.04";
BA_ "Description" SG_ 1882 DLBCU_GST_Byte6 "TP Index : 121";
BA_ "UsrSigPurpose" SG_ 1882 DLBCU_GST_Byte6 4;
BA_ "UserSigValidity" SG_ 1882 DLBCU_GST_Byte6 0;
BA_REL_ "GenSigTimeoutTime" BU_SG_REL_ CGW_CCU SG_ 1882 DLBCU_GST_Byte6 0;
BA_ "NetworkRequest" SG_ 1882 DLBCU_GST_Byte6 0;
BA_ "NetworkRequestHoldingTime" SG_ 1882 DLBCU_GST_Byte6 5000;
BA_ "Version" SG_ 1882 DLBCU_GST_Byte6 "21.02.04";
BA_ "Description" SG_ 1882 DLBCU_GST_Byte7 "TP Index : 121";
BA_ "UsrSigPurpose" SG_ 1882 DLBCU_GST_Byte7 4;
BA_ "UserSigValidity" SG_ 1882 DLBCU_GST_Byte7 0;
BA_REL_ "GenSigTimeoutTime" BU_SG_REL_ CGW_CCU SG_ 1882 DLBCU_GST_Byte7 0;
BA_ "NetworkRequest" SG_ 1882 DLBCU_GST_Byte7 0;
BA_ "NetworkRequestHoldingTime" SG_ 1882 DLBCU_GST_Byte7 5000;
BA_ "Version" SG_ 1882 DLBCU_GST_Byte7 "21.02.04";
BA_ "Description" SG_ 1882 DLBCU_GST_Byte1 "TP Index : 121";
BA_ "UsrSigPurpose" SG_ 1882 DLBCU_GST_Byte1 4;
BA_ "UserSigValidity" SG_ 1882 DLBCU_GST_Byte1 0;
BA_REL_ "GenSigTimeoutTime" BU_SG_REL_ CGW_CCU SG_ 1882 DLBCU_GST_Byte1 0;
BA_ "NetworkRequest" SG_ 1882 DLBCU_GST_Byte1 0;
BA_ "NetworkRequestHoldingTime" SG_ 1882 DLBCU_GST_Byte1 5000;
BA_ "Version" SG_ 1882 DLBCU_GST_Byte1 "21.02.04";
BA_ "GenMsgCycleTime" BO_ 1881 0;
BA_ "GenMsgCycleTimeFast" BO_ 1881 0;
BA_ "GenMsgNrOfRepetition" BO_ 1881 0;
BA_ "DiagResponse" BO_ 1881 1;
BA_ "GenMsgILSupport" BO_ 1881 0;
BA_ "TpMessage" BO_ 1881 1;
BA_ "TpTxIndex" BO_ 1881 122;
BA_ "Description" SG_ 1881 DPSS_GST_Byte0 "TP Index : 122";
BA_ "UsrSigPurpose" SG_ 1881 DPSS_GST_Byte0 4;
BA_ "UserSigValidity" SG_ 1881 DPSS_GST_Byte0 0;
BA_REL_ "GenSigTimeoutTime" BU_SG_REL_ CGW_CCU SG_ 1881 DPSS_GST_Byte0 0;
BA_ "NetworkRequest" SG_ 1881 DPSS_GST_Byte0 0;
BA_ "NetworkRequestHoldingTime" SG_ 1881 DPSS_GST_Byte0 5000;
BA_ "Version" SG_ 1881 DPSS_GST_Byte0 "21.02.04";
BA_ "Description" SG_ 1881 DPSS_GST_Byte2 "TP Index : 122";
BA_ "UsrSigPurpose" SG_ 1881 DPSS_GST_Byte2 4;
BA_ "UserSigValidity" SG_ 1881 DPSS_GST_Byte2 0;
BA_REL_ "GenSigTimeoutTime" BU_SG_REL_ CGW_CCU SG_ 1881 DPSS_GST_Byte2 0;
BA_ "NetworkRequest" SG_ 1881 DPSS_GST_Byte2 0;
BA_ "NetworkRequestHoldingTime" SG_ 1881 DPSS_GST_Byte2 5000;
BA_ "Version" SG_ 1881 DPSS_GST_Byte2 "21.02.04";
BA_ "Description" SG_ 1881 DPSS_GST_Byte3 "TP Index : 122";
BA_ "UsrSigPurpose" SG_ 1881 DPSS_GST_Byte3 4;
BA_ "UserSigValidity" SG_ 1881 DPSS_GST_Byte3 0;
BA_REL_ "GenSigTimeoutTime" BU_SG_REL_ CGW_CCU SG_ 1881 DPSS_GST_Byte3 0;
BA_ "NetworkRequest" SG_ 1881 DPSS_GST_Byte3 0;
BA_ "NetworkRequestHoldingTime" SG_ 1881 DPSS_GST_Byte3 5000;
BA_ "Version" SG_ 1881 DPSS_GST_Byte3 "21.02.04";
BA_ "Description" SG_ 1881 DPSS_GST_Byte4 "TP Index : 122";
BA_ "UsrSigPurpose" SG_ 1881 DPSS_GST_Byte4 4;
BA_ "UserSigValidity" SG_ 1881 DPSS_GST_Byte4 0;
BA_REL_ "GenSigTimeoutTime" BU_SG_REL_ CGW_CCU SG_ 1881 DPSS_GST_Byte4 0;
BA_ "NetworkRequest" SG_ 1881 DPSS_GST_Byte4 0;
BA_ "NetworkRequestHoldingTime" SG_ 1881 DPSS_GST_Byte4 5000;
BA_ "Version" SG_ 1881 DPSS_GST_Byte4 "21.02.04";
BA_ "Description" SG_ 1881 DPSS_GST_Byte5 "TP Index : 122";
BA_ "UsrSigPurpose" SG_ 1881 DPSS_GST_Byte5 4;
BA_ "UserSigValidity" SG_ 1881 DPSS_GST_Byte5 0;
BA_REL_ "GenSigTimeoutTime" BU_SG_REL_ CGW_CCU SG_ 1881 DPSS_GST_Byte5 0;
BA_ "NetworkRequest" SG_ 1881 DPSS_GST_Byte5 0;
BA_ "NetworkRequestHoldingTime" SG_ 1881 DPSS_GST_Byte5 5000;
BA_ "Version" SG_ 1881 DPSS_GST_Byte5 "21.02.04";
BA_ "Description" SG_ 1881 DPSS_GST_Byte6 "TP Index : 122";
BA_ "UsrSigPurpose" SG_ 1881 DPSS_GST_Byte6 4;
BA_ "UserSigValidity" SG_ 1881 DPSS_GST_Byte6 0;
BA_REL_ "GenSigTimeoutTime" BU_SG_REL_ CGW_CCU SG_ 1881 DPSS_GST_Byte6 0;
BA_ "NetworkRequest" SG_ 1881 DPSS_GST_Byte6 0;
BA_ "NetworkRequestHoldingTime" SG_ 1881 DPSS_GST_Byte6 5000;
BA_ "Version" SG_ 1881 DPSS_GST_Byte6 "21.02.04";
BA_ "Description" SG_ 1881 DPSS_GST_Byte7 "TP Index : 122";
BA_ "UsrSigPurpose" SG_ 1881 DPSS_GST_Byte7 4;
BA_ "UserSigValidity" SG_ 1881 DPSS_GST_Byte7 0;
BA_REL_ "GenSigTimeoutTime" BU_SG_REL_ CGW_CCU SG_ 1881 DPSS_GST_Byte7 0;
BA_ "NetworkRequest" SG_ 1881 DPSS_GST_Byte7 0;
BA_ "NetworkRequestHoldingTime" SG_ 1881 DPSS_GST_Byte7 5000;
BA_ "Version" SG_ 1881 DPSS_GST_Byte7 "21.02.04";
BA_ "Description" SG_ 1881 DPSS_GST_Byte1 "TP Index : 122";
BA_ "UsrSigPurpose" SG_ 1881 DPSS_GST_Byte1 4;
BA_ "UserSigValidity" SG_ 1881 DPSS_GST_Byte1 0;
BA_REL_ "GenSigTimeoutTime" BU_SG_REL_ CGW_CCU SG_ 1881 DPSS_GST_Byte1 0;
BA_ "NetworkRequest" SG_ 1881 DPSS_GST_Byte1 0;
BA_ "NetworkRequestHoldingTime" SG_ 1881 DPSS_GST_Byte1 5000;
BA_ "Version" SG_ 1881 DPSS_GST_Byte1 "21.02.04";
BA_ "GenMsgSendType" BO_ 2193667329 0;
BA_ "GenMsgCycleTime" BO_ 2193667329 50;
BA_ "GenMsgCycleTimeFast" BO_ 2193667329 0;
BA_ "GenMsgNrOfRepetition" BO_ 2193667329 0;
BA_ "VFrameFormat" BO_ 2193667329 1;
BA_ "Description" SG_ 2193667329 EMS_Crc1Val "The data area for CRC calculation is based on the data length (DLC) of the message DB.

The CRC shall be calculated over the entire data block (excluding the CRC bytes) including the user data, alive counter and Data ID

 

- CRC Polynomial (0x1021) , Initial Value : 0xFFFF, XOR value : 0x0000, Data ID : Message ID + 0xF800 

- The initial value is for CRC calculation and the message should be sent with the calculated result value. 

- The mathematical expression to 16 bit CRC polynomial is given here. G(x) = x16 + x12 + x5 + 1";
BA_ "GenSigStartValue" SG_ 2193667329 EMS_Crc1Val 65535;
BA_ "UserSigValidity" SG_ 2193667329 EMS_Crc1Val 3;
BA_ "RoutingFactor" SG_ 2193667329 EMS_Crc1Val 5;
BA_ "Version" SG_ 2193667329 EMS_Crc1Val "18.11.08";
BA_ "Description" SG_ 2193667329 EMS_AlvCnt1Val "For the first transmission request for a data element the counter shall be initialized with 0 and shall be incremented by 1 for every subsequent send request. 

When the counter reaches the maximum value(0xFF), then it shall restart with 0 for the next send request";
BA_ "UserSigValidity" SG_ 2193667329 EMS_AlvCnt1Val 3;
BA_ "RoutingFactor" SG_ 2193667329 EMS_AlvCnt1Val 5;
BA_ "Version" SG_ 2193667329 EMS_AlvCnt1Val "18.11.08";
BA_ "Description" SG_ 2193667329 ENG_CrctEngTqVal "This signal comprises the actual indicated engine torque (determined by calculation within the engine management system) (lambda control, knock control, catalyst overheating prevention function, temperature influences, TCS, TCU torque intervention etc. being taken into account).



If MSB is 1, this signal is - value.

else, this signal is +value.

0~10bit is used for absolute value.";
BA_ "UserSigValidity" SG_ 2193667329 ENG_CrctEngTqVal 3;
BA_ "RoutingFactor" SG_ 2193667329 ENG_CrctEngTqVal 5;
BA_ "Version" SG_ 2193667329 ENG_CrctEngTqVal "18.01.03";
BA_ "Description" SG_ 2193667329 ENG_StndTqRatioVal "This factor is calculated inside the ECU to express the long-term changes of the engine torque capabilities due to special operating conditions. It takes into consideration mainly the ambient pressure, the ambient air temperature, and the fuel quality. It is defined as follows :



Torque reduction factor = Possible indicated torque for current conditions / Possible indicated torque at standard conditions 



It is used by the TCU to adapt the gearshift strategy.";
BA_ "GenSigStartValue" SG_ 2193667329 ENG_StndTqRatioVal 127;
BA_ "UserSigValidity" SG_ 2193667329 ENG_StndTqRatioVal 3;
BA_ "RoutingFactor" SG_ 2193667329 ENG_StndTqRatioVal 5;
BA_ "Version" SG_ 2193667329 ENG_StndTqRatioVal "17.12.00";
BA_ "Description" SG_ 2193667329 ENG_FrctTqVal "This signal identifies the current engine friction loss torque. It is stored as a function of 'EngClntTempVal' and 'EngSpdVal' (FrctTqVal = f(EngClntTempVal, EngSpdVal)) in terms of an index table.

The index table is corrected depending on the current load under idle conditions.

The signal comprises the following influencing variables:

- Engine friction = f(EngClntTempVal, EngSpdVal, m)

- m= friction coefficient = f(oil,...)

- Charge cycle work

- Valve actuator

- Air conditioner compressor - interference compensation (intermittent)

- Accessories (e.g. water pump, generator, power-steering pump).

The engine friction losses are dominant in conjunction with the following influencing variables.

Peak loads are not included in the calculation.

Consequently, the engine output torque (flywheel torque) is calculated as follows:

TQ = CrctEngTqVal - FrctTqVal



If MSB is 1, this signal is - value.

else, this signal is +value.

0~10bit is used for absolute value.";
BA_ "UserSigValidity" SG_ 2193667329 ENG_FrctTqVal 3;
BA_ "RoutingFactor" SG_ 2193667329 ENG_FrctTqVal 5;
BA_ "Version" SG_ 2193667329 ENG_FrctTqVal "18.01.01";
BA_ "GenMsgSendType" BO_ 2193667330 0;
BA_ "GenMsgCycleTime" BO_ 2193667330 50;
BA_ "GenMsgCycleTimeFast" BO_ 2193667330 0;
BA_ "GenMsgNrOfRepetition" BO_ 2193667330 0;
BA_ "VFrameFormat" BO_ 2193667330 1;
BA_ "Description" SG_ 2193667330 ENG_IndTqVal "1) In cars equipped with gasoline engines with ETC system, the signal TQI is determined on the driver¡¯s demand including cruise control and other functions and corresponds to the theoretical

engine torque. The signal comprises influences, such as the ambient temperature, the atmospheric pressure, knock control, the catalyst overheating prevention function and other corrections but it does not depend on TCS/ESC and TCU interventions realised due to reduction of airflow into the

engine cylinders and due to ignition angle adjustment or injection/cylinder shut off.



TQI = f (drivers demand [with the influence of cruise control and other functions without the

influence of TCS/ESC and TCU interventions], ignition angle [without the influence of TCS/

ESC and TCU interventions])



2) In cars equipped with gasoline engines without ETC system, the signal TQI is determined on the basis of the measured air mass flow (MAF) which corresponds to the theoretical engine. The signal comprises influences, such as the ambient temperature, atmospheric pressure, knock control, the catalyst overheating prevention function and other corrections but it does not depend on TCS/ESC and TCU interventions realised due to ignition angle adjustment or injection/cylinder shut off.



TQI = f (MAF, ignition angle [without the influence of TCS/ESC and TCU interventions])



3) In cars equipped with Diesel engines, the signal TQI is determined on the basis of the

driver¡¯s demanding injected Diesel amount including cruise control and other functions but does not including the influence of TCS/ESC and TCU interventions. It corresponds to the theoretical engine torque and comprises influences such as the ambient temperature, the atmospheric pressure and

other corrections.



TQI = f (injected Diesel amount [without TCS/ESC and TCU interventions])



In case of failures of the load signal (either MAF error or other errors depending on the system configuration), a backup value is generated from specific index tables. The backup value mode is identified by the signal F_SUB_TQI.



There is a specific phase relationship between the signals TQI and F_SUB_TQI.



If MSB is 1, this signal is - value.

else, this signal is +value.

0~10bit is used for absolute value.";
BA_ "UserSigValidity" SG_ 2193667330 ENG_IndTqVal 3;
BA_ "RoutingFactor" SG_ 2193667330 ENG_IndTqVal 5;
BA_ "Version" SG_ 2193667330 ENG_IndTqVal "18.01.01";
BA_ "Description" SG_ 2193667330 ENG_IndTqBVal "TQI_B = f (actual torque + with the influence of TCS/ESC [without the influence of TCU interventions])

In cars equipped with gasoline engines with ETC system, the signal TQI is determined on actual torque.

The signal comprises influences, such as the ambient temperature, the atmospheric pressure, knock control, the catalyst overheating prevention function and other corrections but it does not include TCU interventions realised due to reduction of airflow into the engine cylinders and due to ignition angle adjustment or injection/cylinder shut off. But the signal does include TCS/ESC interventions.



If MSB is 1, this signal is - value.

else, this signal is +value.

0~10bit is used for absolute value.";
BA_ "UserSigValidity" SG_ 2193667330 ENG_IndTqBVal 3;
BA_ "RoutingFactor" SG_ 2193667330 ENG_IndTqBVal 5;
BA_ "Version" SG_ 2193667330 ENG_IndTqBVal "18.01.01";
BA_ "Description" SG_ 2193667330 ENG_EngSpdErrSta "This signal identifies an error on searching for a long tooth or on engine speed sensing.

Note : in some cases a limp-home function can be activated in the ECU (the engine speed signal is then based on the camshaft signal), and the engine may run even if an error is present on the crankshaft signal.



There is a specific phase relationship between the signals EngSpdVal and EngSpdErrSta.";
BA_ "UserSigValidity" SG_ 2193667330 ENG_EngSpdErrSta 3;
BA_ "RoutingFactor" SG_ 2193667330 ENG_EngSpdErrSta 5;
BA_ "Version" SG_ 2193667330 ENG_EngSpdErrSta "17.12.00";
BA_ "Description" SG_ 2193667330 ENG_MafErrSta "This signal indicates error on MAF signal";
BA_ "UserSigValidity" SG_ 2193667330 ENG_MafErrSta 3;
BA_ "RoutingFactor" SG_ 2193667330 ENG_MafErrSta 5;
BA_ "Version" SG_ 2193667330 ENG_MafErrSta "17.12.00";
BA_ "Description" SG_ 2193667330 ENG_EtcLmphModSta "When ETC Mal-function occurred, EMS requests Cluster to indicate limphome mode driving and inform driver to go to AS center as soon as possible.

- In case of ETC malfunction, EMS finishes ETC control so that a vehicle goes to limphome mode driving (Forced idle). Since sudden vehicle speed decrease can cause uncomfortable feeling to driver, EMS needs to indicate limphome mode condition on Cluster to induce driver to go to AS center as soon as possible.";
BA_ "UserSigValidity" SG_ 2193667330 ENG_EtcLmphModSta 3;
BA_ "RoutingFactor" SG_ 2193667330 ENG_EtcLmphModSta 5;
BA_ "Version" SG_ 2193667330 ENG_EtcLmphModSta "17.12.00";
BA_ "Description" SG_ 2193667330 ENG_SpltInjctnSta "The signal Split_Stat identifies the split injection status. 

 * Note This message is for the GDI Delphi engine applied vehicle only.";
BA_ "UserSigValidity" SG_ 2193667330 ENG_SpltInjctnSta 3;
BA_ "RoutingFactor" SG_ 2193667330 ENG_SpltInjctnSta 5;
BA_ "Version" SG_ 2193667330 ENG_SpltInjctnSta "17.11.00";
BA_ "Description" SG_ 2193667330 ENG_MaxAirconTqVal "EMS defines the maximum allowed A/C compressor torque for drivability and engine safety.

This signal offered to A/C ECU unit only in case of the external variable A/C system installed vehicle.";
BA_ "UserSigValidity" SG_ 2193667330 ENG_MaxAirconTqVal 3;
BA_ "RoutingFactor" SG_ 2193667330 ENG_MaxAirconTqVal 5;
BA_ "Version" SG_ 2193667330 ENG_MaxAirconTqVal "17.12.00";
BA_ "Description" SG_ 2193667330 ENG_AirconPrsrSnsrVal "An EMS senses A/C pitot-tube pressure (between compressor & evaporator) directly with APT sensor.

This signal offered to A/C ECU only in case of the external variable A/C system installed vehicle.";
BA_ "UserSigValidity" SG_ 2193667330 ENG_AirconPrsrSnsrVal 3;
BA_ "RoutingFactor" SG_ 2193667330 ENG_AirconPrsrSnsrVal 5;
BA_ "Version" SG_ 2193667330 ENG_AirconPrsrSnsrVal "17.12.00";
BA_ "Description" SG_ 2193667330 ENG_IsgSta "1. ISG Status expressing CAN message divided by CF_EMS_IsgStat and CF_EMS_IsgStat2 

2. In EMS , CF_EMS_IsgStat and CF_EMS_IsgStat2 do not duplicate the output condition

(EX: If CF_EMS_IsgStat is 01h~07h, CF_EMS_IsgStat2 is 00h)



0x0:ISG is not operating Normal engine operating without ISG/0x1:Idle stop is activated Idle is stopped by ECU during driving/0x2:Automatically started by ECU Engine is automatically started by ECU regardless driver¡¯s volition during idle stop because the condition that ISG function to be prohibited is satisfied, for example SOC is too low./0x3:ISG is prohibited Driver prohibits to activate ISG in order to avoid start lag when he met traffic jam for example./0x4:Fault is existing in ISG There is fault, which is related with ISG. So, idle stop is prohibited and engine started automatically if it is idle stop condition. But for the vehicles that use CF_EMS_ISGStat2, the condition for not-activated battery sensor can be ignored./0x5:Idle stop is inhibited by system automatically for safety and  convenient condition related with battery SOC, brake vacuum pressure etc. ISG function check for EOL./0x6:Auto start is deactivated system automatically to keep safety, Such as door open, hood open and seat belt unlock./0x7:If driver shift gear N to D range without braking to make auto starting. (Economy ISG Only)";
BA_ "UserSigValidity" SG_ 2193667330 ENG_IsgSta 3;
BA_ "RoutingFactor" SG_ 2193667330 ENG_IsgSta 5;
BA_ "Version" SG_ 2193667330 ENG_IsgSta "17.12.02";
BA_ "Description" SG_ 2193667330 ENG_OilLvlSta "This signal indicates the replace time of engine oil.";
BA_ "UserSigValidity" SG_ 2193667330 ENG_OilLvlSta 3;
BA_ "RoutingFactor" SG_ 2193667330 ENG_OilLvlSta 5;
BA_ "Version" SG_ 2193667330 ENG_OilLvlSta "17.12.00";
BA_ "GenMsgSendType" BO_ 2214659329 0;
BA_ "GenMsgCycleTime" BO_ 2214659329 50;
BA_ "GenMsgCycleTimeFast" BO_ 2214659329 0;
BA_ "GenMsgNrOfRepetition" BO_ 2214659329 0;
BA_ "VFrameFormat" BO_ 2214659329 1;
BA_ "Description" SG_ 2214659329 EMS_Crc7Val "The data area for CRC calculation is based on the data length (DLC) of the message DB.

The CRC shall be calculated over the entire data block (excluding the CRC bytes) including the user data, alive counter and Data ID

 

- CRC Polynomial (0x1021) , Initial Value : 0xFFFF, XOR value : 0x0000, Data ID : Message ID + 0xF800 

- The initial value is for CRC calculation and the message should be sent with the calculated result value. 

- The mathematical expression to 16 bit CRC polynomial is given here. G(x) = x16 + x12 + x5 + 1";
BA_ "GenSigStartValue" SG_ 2214659329 EMS_Crc7Val 65535;
BA_ "UserSigValidity" SG_ 2214659329 EMS_Crc7Val 3;
BA_ "RoutingFactor" SG_ 2214659329 EMS_Crc7Val 5;
BA_ "Version" SG_ 2214659329 EMS_Crc7Val "18.11.08";
BA_ "Description" SG_ 2214659329 EMS_AlvCnt7Val "For the first transmission request for a data element the counter shall be initialized with 0 and shall be incremented by 1 for every subsequent send request. 

When the counter reaches the maximum value(0xFF), then it shall restart with 0 for the next send request";
BA_ "UserSigValidity" SG_ 2214659329 EMS_AlvCnt7Val 3;
BA_ "RoutingFactor" SG_ 2214659329 EMS_AlvCnt7Val 5;
BA_ "Version" SG_ 2214659329 EMS_AlvCnt7Val "18.11.08";
BA_ "Description" SG_ 2214659329 HEV_IndTqVal "Indicated engine torque after torque coordination(intervention)";
BA_ "UserSigValidity" SG_ 2214659329 HEV_IndTqVal 3;
BA_ "RoutingFactor" SG_ 2214659329 HEV_IndTqVal 5;
BA_ "Version" SG_ 2214659329 HEV_IndTqVal "18.10.07";
BA_ "Description" SG_ 2214659329 HEV_DrvTqVal "Driver's demand torque";
BA_ "UserSigValidity" SG_ 2214659329 HEV_DrvTqVal 3;
BA_ "RoutingFactor" SG_ 2214659329 HEV_DrvTqVal 5;
BA_ "Version" SG_ 2214659329 HEV_DrvTqVal "18.05.04";
BA_ "Description" SG_ 2214659329 HEV_TqStndVal "Standard value for torque scaling in torque interface";
BA_ "UserSigValidity" SG_ 2214659329 HEV_TqStndVal 3;
BA_ "RoutingFactor" SG_ 2214659329 HEV_TqStndVal 5;
BA_ "Version" SG_ 2214659329 HEV_TqStndVal "18.05.04";
BA_ "GenMsgSendType" BO_ 2214659330 0;
BA_ "GenMsgCycleTime" BO_ 2214659330 50;
BA_ "GenMsgCycleTimeFast" BO_ 2214659330 0;
BA_ "GenMsgNrOfRepetition" BO_ 2214659330 0;
BA_ "VFrameFormat" BO_ 2214659330 1;
BA_ "Description" SG_ 2214659330 HEV_FrctTqVal "Friction Loss Torque";
BA_ "UserSigValidity" SG_ 2214659330 HEV_FrctTqVal 3;
BA_ "RoutingFactor" SG_ 2214659330 HEV_FrctTqVal 5;
BA_ "Version" SG_ 2214659330 HEV_FrctTqVal "18.10.07";
BA_ "Description" SG_ 2214659330 HEV_EngSpdVal "Engine Speed";
BA_ "UserSigValidity" SG_ 2214659330 HEV_EngSpdVal 3;
BA_ "RoutingFactor" SG_ 2214659330 HEV_EngSpdVal 5;
BA_ "Version" SG_ 2214659330 HEV_EngSpdVal "18.05.04";
BA_ "Description" SG_ 2214659330 HEV_EngOpSta "Engine Operating State";
BA_ "UserSigValidity" SG_ 2214659330 HEV_EngOpSta 3;
BA_ "RoutingFactor" SG_ 2214659330 HEV_EngOpSta 5;
BA_ "Version" SG_ 2214659330 HEV_EngOpSta "18.05.04";
BA_ "Description" SG_ 2214659330 HEV_IntakeAirTempVal "Intake air temperature";
BA_ "UserSigValidity" SG_ 2214659330 HEV_IntakeAirTempVal 3;
BA_ "RoutingFactor" SG_ 2214659330 HEV_IntakeAirTempVal 5;
BA_ "Version" SG_ 2214659330 HEV_IntakeAirTempVal "18.05.04";
BA_ "Description" SG_ 2214659330 HEV_AccelPdlVal "The signal is a measure of the Accelerator Pedal value.

The accelerator pedal value is determined via 2 pedal sensors, which are connected mechanically to the accelerator pedal. If the EMS-ECU recognizes that the accelerator pedal is not activated, then the value 00 H is carried over on the CAN. If the EMS-ECU detects that the accelerator pedal is fully activated, then 3FE H is carried over on the CAN bus.

If an error is detected on both pedal sensor channels, this is identified by the value 3FFH";
BA_ "UserSigValidity" SG_ 2214659330 HEV_AccelPdlVal 3;
BA_ "RoutingFactor" SG_ 2214659330 HEV_AccelPdlVal 5;
BA_ "Version" SG_ 2214659330 HEV_AccelPdlVal "19.11.11";
BA_ "Description" SG_ 2214659330 HEV_IndTqTar "Indicated Engine (Desired) Torque";
BA_ "UserSigValidity" SG_ 2214659330 HEV_IndTqTar 3;
BA_ "RoutingFactor" SG_ 2214659330 HEV_IndTqTar 5;
BA_ "Version" SG_ 2214659330 HEV_IndTqTar "18.05.04";
BA_ "GenMsgSendType" BO_ 2214659331 0;
BA_ "GenMsgCycleTime" BO_ 2214659331 50;
BA_ "GenMsgCycleTimeFast" BO_ 2214659331 0;
BA_ "GenMsgNrOfRepetition" BO_ 2214659331 0;
BA_ "VFrameFormat" BO_ 2214659331 1;
BA_ "GenMsgSendType" BO_ 2214659332 0;
BA_ "GenMsgCycleTime" BO_ 2214659332 50;
BA_ "GenMsgCycleTimeFast" BO_ 2214659332 0;
BA_ "GenMsgNrOfRepetition" BO_ 2214659332 0;
BA_ "VFrameFormat" BO_ 2214659332 1;
BA_ "GenMsgSendType" BO_ 2277634049 0;
BA_ "GenMsgCycleTime" BO_ 2277634049 150;
BA_ "GenMsgCycleTimeFast" BO_ 2277634049 0;
BA_ "GenMsgNrOfRepetition" BO_ 2277634049 0;
BA_ "VFrameFormat" BO_ 2277634049 1;
BA_ "Description" SG_ 2277634049 EPB_Crc1Val "The data area for CRC calculation is based on the data length (DLC) of the message DB.

The CRC shall be calculated over the entire data block (excluding the CRC bytes) including the user data, alive counter and Data ID

 

- CRC Polynomial (0x1021) , Initial Value : 0xFFFF, XOR value : 0x0000, Data ID : Message ID + 0xF800 

- The initial value is for CRC calculation and the message should be sent with the calculated result value. 

- The mathematical expression to 16 bit CRC polynomial is given here. G(x) = x16 + x12 + x5 + 1";
BA_ "GenSigStartValue" SG_ 2277634049 EPB_Crc1Val 65535;
BA_ "UserSigValidity" SG_ 2277634049 EPB_Crc1Val 3;
BA_ "RoutingFactor" SG_ 2277634049 EPB_Crc1Val 3;
BA_ "Version" SG_ 2277634049 EPB_Crc1Val "18.11.08";
BA_ "Description" SG_ 2277634049 EPB_AlvCnt1Val "For the first transmission request for a data element the counter shall be initialized with 0 and shall be incremented by 1 for every subsequent send request. 

When the counter reaches the maximum value(0xFF), then it shall restart with 0 for the next send request";
BA_ "UserSigValidity" SG_ 2277634049 EPB_AlvCnt1Val 3;
BA_ "RoutingFactor" SG_ 2277634049 EPB_AlvCnt1Val 3;
BA_ "Version" SG_ 2277634049 EPB_AlvCnt1Val "18.11.08";
BA_ "Description" SG_ 2277634049 EPB_LmpStaDis "This signal indicates status lamp request from EPB to lamp control unit.

- If a lamp control unit can not get this signal via CAN due to any errors, the last lamp state before the error should be maintained.

- When EPB apply switch is pressed in the IG-key off sate, the parking brake lamp should be on for 15 seconds and off. In this case, the cluster shall have CAN wake-up capability.



EPB_LmpStaDis(0H) - Parking brake lamp status (Off)

EPB_LmpStaDis(1H) - Parking brake lamp status (On)

EPB_LmpStaDis(2H) - Parking brake lamp status (Blinking at 1Hz)";
BA_ "UserSigValidity" SG_ 2277634049 EPB_LmpStaDis 3;
BA_REL_ "GenSigTimeoutTime" BU_SG_REL_ APSU SG_ 2277634049 EPB_LmpStaDis 1500;
BA_REL_ "GenSigTimeoutTime" BU_SG_REL_ RLHV SG_ 2277634049 EPB_LmpStaDis 1500;
BA_REL_ "GenSigTimeoutTime" BU_SG_REL_ RRHV SG_ 2277634049 EPB_LmpStaDis 1500;
BA_REL_ "GenSigTimeoutTime" BU_SG_REL_ DPSU SG_ 2277634049 EPB_LmpStaDis 1500;
BA_REL_ "GenSigTimeoutTime" BU_SG_REL_ PFSU SG_ 2277634049 EPB_LmpStaDis 1500;
BA_REL_ "GenSigTimeoutTime" BU_SG_REL_ RRPSU SG_ 2277634049 EPB_LmpStaDis 1500;
BA_REL_ "GenSigTimeoutTime" BU_SG_REL_ RLPSU SG_ 2277634049 EPB_LmpStaDis 1500;
BA_ "RoutingFactor" SG_ 2277634049 EPB_LmpStaDis 3;
BA_ "Version" SG_ 2277634049 EPB_LmpStaDis "20.07.03";
BA_ "Description" SG_ 2277634049 EPB_FlrLmpStaDis "Information about the failure lamp request from EPB to lamp control unit.



EPB_F_LAMP(0H) - Yellow failure lamp status(Off)

EPB_F_LAMP(1H) - Yellow failure lamp status(On)

EPB_F_LAMP(2H) - Yellow failure lamp status(Blinking at 1 Hz)";
BA_ "UserSigValidity" SG_ 2277634049 EPB_FlrLmpStaDis 3;
BA_ "RoutingFactor" SG_ 2277634049 EPB_FlrLmpStaDis 3;
BA_ "Version" SG_ 2277634049 EPB_FlrLmpStaDis "17.12.00";
BA_ "Description" SG_ 2277634049 EPB_OutDataDis "An EPB can show its information message to driver on a cluster or a display module with this signal. ¡Ø 0x4 is for China";
BA_ "UserSigValidity" SG_ 2277634049 EPB_OutDataDis 3;
BA_ "RoutingFactor" SG_ 2277634049 EPB_OutDataDis 3;
BA_ "Version" SG_ 2277634049 EPB_OutDataDis "19.11.02";
BA_ "Description" SG_ 2277634049 EPB_AlrmReq "This signal indicates that an EPB requests cluster or tone controller to ring the alarm according to the status of an EPB.



Conversion [Condition]

0H : Normal operation

1H : EPB_CLU = 2 or 3

(send signals three time in a row & 1st signal should be sent at the same time as corresponding EPB_CLU 1st Signal)

2H : Dynamic braking[ECD, RWU] (send signal continuously)

3H : Reserved";
BA_ "UserSigValidity" SG_ 2277634049 EPB_AlrmReq 3;
BA_ "RoutingFactor" SG_ 2277634049 EPB_AlrmReq 3;
BA_ "Version" SG_ 2277634049 EPB_AlrmReq "17.12.00";
BA_ "Description" SG_ 2277634049 EPB_SwPosSta "Information about the EPB control switch state";
BA_ "UserSigValidity" SG_ 2277634049 EPB_SwPosSta 3;
BA_ "RoutingFactor" SG_ 2277634049 EPB_SwPosSta 3;
BA_ "Version" SG_ 2277634049 EPB_SwPosSta "17.12.00";
BA_ "Description" SG_ 2277634049 EPB_RrBrkLtActvReq "If an EPB acts braking and the vehicle speed is higher than pre-defined condition then rear brake lamp shall be turned on. This signal requests ESC or brake lamp controller to turn on rear brake lamp.";
BA_ "UserSigValidity" SG_ 2277634049 EPB_RrBrkLtActvReq 3;
BA_ "RoutingFactor" SG_ 2277634049 EPB_RrBrkLtActvReq 3;
BA_ "Version" SG_ 2277634049 EPB_RrBrkLtActvReq "17.12.00";
BA_ "Description" SG_ 2277634049 EPB_FrcErrSta "Detail descriptions of error status of EPB force if EPB_FrcErrSta = 00H";
BA_ "UserSigValidity" SG_ 2277634049 EPB_FrcErrSta 3;
BA_ "RoutingFactor" SG_ 2277634049 EPB_FrcErrSta 3;
BA_ "Version" SG_ 2277634049 EPB_FrcErrSta "17.12.00";
BA_ "Description" SG_ 2277634049 EPB_DynmBrkFrcReqSigSta "This signal indicates the validity of EPB_DynmBrkFrcReqSigSta (EPB request for ESP to activate Dynamic Brake Function) signal.";
BA_ "GenSigStartValue" SG_ 2277634049 EPB_DynmBrkFrcReqSigSta 1;
BA_ "UserSigValidity" SG_ 2277634049 EPB_DynmBrkFrcReqSigSta 3;
BA_ "RoutingFactor" SG_ 2277634049 EPB_DynmBrkFrcReqSigSta 3;
BA_ "Version" SG_ 2277634049 EPB_DynmBrkFrcReqSigSta "17.12.00";
BA_ "Description" SG_ 2277634049 EPB_FrcSta "Information about the force status of the EPB";
BA_ "UserSigValidity" SG_ 2277634049 EPB_FrcSta 3;
BA_ "RoutingFactor" SG_ 2277634049 EPB_FrcSta 3;
BA_ "Version" SG_ 2277634049 EPB_FrcSta "17.12.00";
BA_ "Description" SG_ 2277634049 EPB_FlSta "Information about availability of EPB. If this bit is set (EPB is not available), EPB motor control is not possible, e.g. by external AVH request.";
BA_ "GenSigStartValue" SG_ 2277634049 EPB_FlSta 2;
BA_ "UserSigValidity" SG_ 2277634049 EPB_FlSta 3;
BA_ "RoutingFactor" SG_ 2277634049 EPB_FlSta 3;
BA_ "Version" SG_ 2277634049 EPB_FlSta "17.12.00";
BA_ "Description" SG_ 2277634049 EPB_EscReqAckSta "Acknowledge signal for ESC request (e.g. AVH).



ESC sends request to release (1) or clamping (2) via signal REQ_EPB_ACT. The EPB acknowledges this request with EPB_EscReqAckSta = 1 within the time tESP_REQ_OK (value tbd) and performs according to the requested action. If signal EPB_EscReqAckSta remains = 0 for longer than tESP_REQ_OK, the requested action will be discarded.";
BA_ "UserSigValidity" SG_ 2277634049 EPB_EscReqAckSta 3;
BA_ "RoutingFactor" SG_ 2277634049 EPB_EscReqAckSta 3;
BA_ "Version" SG_ 2277634049 EPB_EscReqAckSta "17.12.00";
BA_ "Description" SG_ 2277634049 EPB_DynmBrkFrcReq "EPB dynamic Braking Request";
BA_ "UserSigValidity" SG_ 2277634049 EPB_DynmBrkFrcReq 3;
BA_ "RoutingFactor" SG_ 2277634049 EPB_DynmBrkFrcReq 3;
BA_ "Version" SG_ 2277634049 EPB_DynmBrkFrcReq "17.12.00";
BA_ "Description" SG_ 2277634049 EPB_EmerModReq "This signal is for requesting EPB emergency mode to eEPB ECU.

- Emergency EPB Mode : Turning On the Relay in order to change into Emgergency mode 

- Normal EPB Mode : Turning Off the Relay in order to change into Normal mode";
BA_ "UserSigValidity" SG_ 2277634049 EPB_EmerModReq 3;
BA_ "RoutingFactor" SG_ 2277634049 EPB_EmerModReq 3;
BA_ "Version" SG_ 2277634049 EPB_EmerModReq "20.04.06";
BA_ "Description" SG_ 2277634049 EPB_EpbSta4VcuReq "This signal indicates the status of EPB parking actuation opearated by VCU's request.";
BA_ "UserSigValidity" SG_ 2277634049 EPB_EpbSta4VcuReq 3;
BA_ "RoutingFactor" SG_ 2277634049 EPB_EpbSta4VcuReq 3;
BA_ "Version" SG_ 2277634049 EPB_EpbSta4VcuReq "20.07.01";
BA_ "GenMsgSendType" BO_ 2277634050 0;
BA_ "GenMsgCycleTime" BO_ 2277634050 150;
BA_ "GenMsgCycleTimeFast" BO_ 2277634050 0;
BA_ "GenMsgNrOfRepetition" BO_ 2277634050 0;
BA_ "VFrameFormat" BO_ 2277634050 1;
BA_ "Description" SG_ 2277634050 EPB_ActlFrcVal "Actual braking force measured by EPB force sensor.";
BA_ "GenSigStartValue" SG_ 2277634050 EPB_ActlFrcVal 1000;
BA_ "UserSigValidity" SG_ 2277634050 EPB_ActlFrcVal 3;
BA_ "RoutingFactor" SG_ 2277634050 EPB_ActlFrcVal 3;
BA_ "Version" SG_ 2277634050 EPB_ActlFrcVal "17.12.00";
BA_ "Description" SG_ 2277634050 EPB_DynmBrkFrcDclReq "Requested deceleration for DBF. The ESC must consider this value if EPB_DynmBrkFrcReq is equal to 1.";
BA_ "UserSigValidity" SG_ 2277634050 EPB_DynmBrkFrcDclReq 3;
BA_ "RoutingFactor" SG_ 2277634050 EPB_DynmBrkFrcDclReq 3;
BA_ "Version" SG_ 2277634050 EPB_DynmBrkFrcDclReq "17.12.00";
BA_ "GenMsgSendType" BO_ 2244048129 0;
BA_ "GenMsgCycleTime" BO_ 2244048129 100;
BA_ "GenMsgCycleTimeFast" BO_ 2244048129 0;
BA_ "GenMsgNrOfRepetition" BO_ 2244048129 0;
BA_ "VFrameFormat" BO_ 2244048129 1;
BA_ "Description" SG_ 2244048129 ESC_Crc3Val "The data area for CRC calculation is based on the data length (DLC) of the message DB.

The CRC shall be calculated over the entire data block (excluding the CRC bytes) including the user data, alive counter and Data ID

 

- CRC Polynomial (0x1021) , Initial Value : 0xFFFF, XOR value : 0x0000, Data ID : Message ID + 0xF800 

- The initial value is for CRC calculation and the message should be sent with the calculated result value. 

- The mathematical expression to 16 bit CRC polynomial is given here. G(x) = x16 + x12 + x5 + 1";
BA_ "GenSigStartValue" SG_ 2244048129 ESC_Crc3Val 65535;
BA_ "UserSigValidity" SG_ 2244048129 ESC_Crc3Val 3;
BA_ "RoutingFactor" SG_ 2244048129 ESC_Crc3Val 5;
BA_ "Version" SG_ 2244048129 ESC_Crc3Val "18.11.08";
BA_ "Description" SG_ 2244048129 ESC_AlvCnt3Val "For the first transmission request for a data element the counter shall be initialized with 0 and shall be incremented by 1 for every subsequent send request. 

When the counter reaches the maximum value(0xFF), then it shall restart with 0 for the next send request";
BA_ "UserSigValidity" SG_ 2244048129 ESC_AlvCnt3Val 3;
BA_ "RoutingFactor" SG_ 2244048129 ESC_AlvCnt3Val 5;
BA_ "Version" SG_ 2244048129 ESC_AlvCnt3Val "18.11.08";
BA_ "Description" SG_ 2244048129 SCC_TqIntrvntnVal "The indicated torque command TQI_ACC is the basic control path to the engine power control. This command has the same priority in the torque-structure than the driver¡¯s demand torque. The maximum value of either TQI_ACC or the driver torque is selected fo";
BA_ "UserSigValidity" SG_ 2244048129 SCC_TqIntrvntnVal 3;
BA_ "RoutingFactor" SG_ 2244048129 SCC_TqIntrvntnVal 5;
BA_ "Version" SG_ 2244048129 SCC_TqIntrvntnVal "17.12.00";
BA_ "Description" SG_ 2244048129 ESC_VehAccelVal "The vehicle acceleration ACCEL_REF_ACC displays the feedback signal for the inner acceleration control loop since it is the SCC-internal acceleration command value. In addition this signal is used to calculate the target object acceleration. If the requirements demanded from this signal can¡¯t be guaranteed then SCC must be informed and SCC has to be switched off.

Alternatively SCC may calculate the vehicle acceleration itself. Then the wheel speed vxvTyrexx (or the wheel speed row signals vxvTyreRawxx and the wheel tolerances radTolxx of below diagram) should be

transmitted by TCS or ESC.";
BA_ "UserSigValidity" SG_ 2244048129 ESC_VehAccelVal 3;
BA_ "RoutingFactor" SG_ 2244048129 ESC_VehAccelVal 5;
BA_ "Version" SG_ 2244048129 ESC_VehAccelVal "17.12.00";
BA_ "Description" SG_ 2244048129 ESC_AccelBasisVal "This value is used to initialize the acceleration control when SCC is engaged or after driver override.";
BA_ "UserSigValidity" SG_ 2244048129 ESC_AccelBasisVal 3;
BA_ "RoutingFactor" SG_ 2244048129 ESC_AccelBasisVal 5;
BA_ "Version" SG_ 2244048129 ESC_AccelBasisVal "17.12.00";
BA_ "Description" SG_ 2244048129 PWI_STATE "This signal indicates brake pad wear state. If the brake pad is worn to the designted amount, this signal is used to indicate the alarm on the cluster";
BA_ "UserSigValidity" SG_ 2244048129 PWI_STATE 3;
BA_ "RoutingFactor" SG_ 2244048129 PWI_STATE 5;
BA_ "Version" SG_ 2244048129 PWI_STATE "21.04.02";
BA_ "GenMsgSendType" BO_ 2244048130 0;
BA_ "GenMsgCycleTime" BO_ 2244048130 100;
BA_ "GenMsgCycleTimeFast" BO_ 2244048130 0;
BA_ "GenMsgNrOfRepetition" BO_ 2244048130 0;
BA_ "VFrameFormat" BO_ 2244048130 1;
BA_ "Description" SG_ 2244048130 SCC_OptTyp "This value is used for SCC is equipped or not.

Do not recognize 0x3(Not Coded) as failure.";
BA_ "UserSigValidity" SG_ 2244048130 SCC_OptTyp 3;
BA_ "RoutingFactor" SG_ 2244048130 SCC_OptTyp 5;
BA_ "Version" SG_ 2244048130 SCC_OptTyp "18.12.04";
BA_ "Description" SG_ 2244048130 ESC_BrkLtReq "Flag from TCS which activates the illumination of the brake lights during automatic braking.";
BA_ "UserSigValidity" SG_ 2244048130 ESC_BrkLtReq 3;
BA_ "RoutingFactor" SG_ 2244048130 ESC_BrkLtReq 5;
BA_ "Version" SG_ 2244048130 ESC_BrkLtReq "17.12.00";
BA_ "Description" SG_ 2244048130 ESC_DclEnblReq "This signal enables the deceleration control to accept command values axvCv from SCC. This flag is complementary to the ACC_REQ flag if SCC is in active mode.";
BA_ "UserSigValidity" SG_ 2244048130 ESC_DclEnblReq 3;
BA_ "RoutingFactor" SG_ 2244048130 ESC_DclEnblReq 5;
BA_ "Version" SG_ 2244048130 ESC_DclEnblReq "17.12.00";
BA_ "Description" SG_ 2244048130 ESC_DrvOvrdSta "This signal indicates that acceleration or deceleration value of driver¡¯s requirement is greater than SCC setting value.";
BA_ "UserSigValidity" SG_ 2244048130 ESC_DrvOvrdSta 3;
BA_ "RoutingFactor" SG_ 2244048130 ESC_DrvOvrdSta 5;
BA_ "Version" SG_ 2244048130 ESC_DrvOvrdSta "17.12.00";
BA_ "Description" SG_ 2244048130 ESC_DrvBrkSta "This signal indicates flag from ESC to SCC to indicate the driver braking state";
BA_ "UserSigValidity" SG_ 2244048130 ESC_DrvBrkSta 3;
BA_ "RoutingFactor" SG_ 2244048130 ESC_DrvBrkSta 5;
BA_ "Version" SG_ 2244048130 ESC_DrvBrkSta "17.12.00";
BA_ "Description" SG_ 2244048130 SCC_EnblReq "This signal is set by the safety logic in the TCS/ESC. The safety logic shall monitor the following:

1. A temporary failure in the vehicle does not allow SCC (Brakes are overheated, etc¡¦). 

SCC is disabled reversible.

2. SCC communication failure (timeout";
BA_ "UserSigValidity" SG_ 2244048130 SCC_EnblReq 3;
BA_ "RoutingFactor" SG_ 2244048130 SCC_EnblReq 5;
BA_ "Version" SG_ 2244048130 SCC_EnblReq "17.12.00";
BA_ "Description" SG_ 2244048130 ESC_DrvBrkActvSta "This signal indicates that a driver is pressing the brake pedal or not.";
BA_ "UserSigValidity" SG_ 2244048130 ESC_DrvBrkActvSta 3;
BA_ "RoutingFactor" SG_ 2244048130 ESC_DrvBrkActvSta 5;
BA_ "Version" SG_ 2244048130 ESC_DrvBrkActvSta "17.12.00";
BA_ "Description" SG_ 2244048130 ESC_PrkBrkActvSta "This signal indicates whether the parking brake is activated or not.";
BA_ "UserSigValidity" SG_ 2244048130 ESC_PrkBrkActvSta 3;
BA_ "RoutingFactor" SG_ 2244048130 ESC_PrkBrkActvSta 5;
BA_ "Version" SG_ 2244048130 ESC_PrkBrkActvSta "17.12.00";
BA_ "Description" SG_ 2244048130 ESC_HDP_FltMonSta "ÀÌ ½ÅÈ£´Â IEB (ESC)°¡ HDP Á¦¾î±â(Main/Sub)ÀÇ »óÅÂ¸¦ ¸ð´ÏÅÍ¸µÇÑ °á°úÀÌ´Ù.

This signal is the result of the IEB (ESC) monitoring the state of the HDP controller (Main/Sub).";
BA_ "UserSigValidity" SG_ 2244048130 ESC_HDP_FltMonSta 3;
BA_REL_ "GenSigTimeoutTime" BU_SG_REL_ PSB SG_ 2244048130 ESC_HDP_FltMonSta 1500;
BA_ "RoutingFactor" SG_ 2244048130 ESC_HDP_FltMonSta 5;
BA_ "Version" SG_ 2244048130 ESC_HDP_FltMonSta "21.04.00";
BA_ "Description" SG_ 2244048130 FCA_EquipSta "FCA Equipment Status

Do not recognize 0x3(Not Coded) as failure.";
BA_ "UserSigValidity" SG_ 2244048130 FCA_EquipSta 3;
BA_ "RoutingFactor" SG_ 2244048130 FCA_EquipSta 5;
BA_ "Version" SG_ 2244048130 FCA_EquipSta "18.12.04";
BA_ "Description" SG_ 2244048130 FCA_AvlblSta "This signal indicates state signal from ESC to FCA which tells if ESC is 'Available', 'Temporarily not available', 'Permanently not available' or 'FCA Communication Error'.";
BA_ "UserSigValidity" SG_ 2244048130 FCA_AvlblSta 3;
BA_ "RoutingFactor" SG_ 2244048130 FCA_AvlblSta 5;
BA_ "Version" SG_ 2244048130 FCA_AvlblSta "18.02.00";
BA_ "Description" SG_ 2244048130 ESC_FCA_ActvSta "This signal specifies the status of control for FCA control request flag.

(FCA Á¦¾î ¿äÃ»¿¡ ´ëÇÑ Á¦µ¿ Á¦¾î±â ¼öÇà¿©ºÎ È®ÀÎÀ» À§ÇÑ Á¤º¸ ½ÅÈ£)";
BA_ "UserSigValidity" SG_ 2244048130 ESC_FCA_ActvSta 3;
BA_ "RoutingFactor" SG_ 2244048130 ESC_FCA_ActvSta 5;
BA_ "Version" SG_ 2244048130 ESC_FCA_ActvSta "19.11.02";
BA_ "Description" SG_ 2244048130 ESC_DBS_ActvSta "This signal specifies the status of control for DBS flag.

(DBS Á¦¾î ¿äÃ»¿¡ ´ëÇÑ Á¦µ¿ Á¦¾î±â ¼öÇà¿©ºÎ È®ÀÎ À§ÇÑ Á¤º¸ ½ÅÈ£)";
BA_ "UserSigValidity" SG_ 2244048130 ESC_DBS_ActvSta 3;
BA_ "RoutingFactor" SG_ 2244048130 ESC_DBS_ActvSta 5;
BA_ "Version" SG_ 2244048130 ESC_DBS_ActvSta "19.11.02";
BA_ "Description" SG_ 2244048130 SCC_TqReq "When it is set, the signal indicates that ESC requests engine torque control for SCC. When the signal is set, EMS should not conduct fuel-cut off control unless it is required to prevent the damage of the engine and the related components.";
BA_ "UserSigValidity" SG_ 2244048130 SCC_TqReq 3;
BA_ "RoutingFactor" SG_ 2244048130 SCC_TqReq 5;
BA_ "Version" SG_ 2244048130 SCC_TqReq "17.12.00";
BA_ "Description" SG_ 2244048130 ESC_HDP_EgSta "ÀÌ ½ÅÈ£´Â IEB (ESC) / RCU°¡ ¿¬°áµÈ HDP ÄÁÆ®·Ñ·¯ (¸ÞÀÎ / ¼­ºê)ÀÇ Á¤º¸ÀÔ´Ï´Ù.

This signal is the information which of the HDP controllers (Main/Sub) the IEB (ESC)/RCU is engaged.



IEB/RCU°¡ Main/Sub Á¦¾î±âÀÇ ÇùÁ¶Á¦¾î ´ëÀÀ»óÅÂ¸¦ ¾Ë·ÁÁÖ´Â ½ÅÈ£ (Engage)

0x0: Not engaged (HDP °ü·ÃÇÏ¿© ´ëÀÀÇÏÁö ¾Ê´Â »óÅÂ)

0x1: Engaged in main controller by IEB (ESC) (ADAS_DRV 2ÀÇ ½ÅÈ£¸¦ ¼ö½ÅÇÏ¿© ÀÛµ¿ÇÏ´Â »óÅÂ)

0x2: Engaged in sub controller by IEB (ESC) (FR_CMRÀÇ ½ÅÈ£¸¦ ¼ö½ÅÇÏ¿© ÀÛµ¿ÇÏ´Â »óÅÂ)

0x3: MRM with IEB (ESC) alone by IEB (ESC) (IEB ´Üµ¶ MRM ÀÛµ¿ »óÅÂ)

0x4: Engaged in main controller by RCU (ADAS_DRV 2ÀÇ ½ÅÈ£¸¦ ¼ö½ÅÇÏ¿© ÀÛµ¿ÇÏ´Â »óÅÂ)

0x5: Engaged in sub controller by RCU (FR_CMRÀÇ ½ÅÈ£¸¦ ¼ö½ÅÇÏ¿© ÀÛµ¿ÇÏ´Â »óÅÂ)

0x6: MRM with IEB (ESC) alone by RCU (RCU ´Üµ¶ MRM ÀÛµ¿ »óÅÂ)

0x7: Reserved";
BA_ "UserSigValidity" SG_ 2244048130 ESC_HDP_EgSta 3;
BA_ "RoutingFactor" SG_ 2244048130 ESC_HDP_EgSta 5;
BA_ "Version" SG_ 2244048130 ESC_HDP_EgSta "21.04.00";
BA_ "Description" SG_ 2244048130 ESC_HDP_EnblReq "ÀÌ ½ÅÈ£´Â HDP ±â´ÉÀ» ´ëÀÀÇÏ±â À§ÇÑ IEB (ESC)ÀÇ °íÀå»óÅÂÀÌ´Ù.

This signal is a fault state of the IEB (ESC) for the HDP function.



IEB/RCU°¡ ÀÚÃ¼ÀûÀ¸·Î HDP °ü·Ã °íÀåÀ» ÆÇ´ÜÇÏ¿© ´ëÀÀ °¡´É »óÅÂ¸¦ ¼¼ºÐÈ­ÇÏ¿© ¾Ë·ÁÁÖ´Â ½ÅÈ£

0x0: Á¤»óÀÛµ¿ »óÈ²

0x1: ÇùÁ¶Á¦¾î »ç¾ç¿¡ Á¤ÀÇµÈ ±â´ÉÀûÀÎ ÀÛµ¿À» Á¤»óÀûÀ¸·Î ¼öÇàÇÒ ¼ö ¾ø´Â °æ¿ì

0x2: ¿ä±¸°¡¼Óµµ ÃßÁ¾Á¦¾î ½Ã ÀÏºÎ ¼º´ÉÀúÇÏ°¡ ¹ß»ýÇÒ ¼ö ÀÖ´Â »óÈ²

0x3: ¿ä±¸°¡¼Óµµ ÃßÁ¾Á¦¾î¸¦ ¼öÇàÇÒ ¾øÁö¸¸ Á¦µ¿Á¦¾î´Â °¡´ÉÇÑ »óÈ²

0x4: ¿ä±¸°¡¼Óµµ ÃßÁ¾Á¦¾î ¹× Á¦µ¿Á¦¾î°¡ ºÒ°¡´ÉÇÑ »óÈ²

0x5: ¿ä±¸°¡¼Óµµ ÃßÁ¾Á¦¾î¸¦ ¼öÇàÇÒ ¼ö ÀÖÀ¸³ª ±¸µ¿Á¦¾î°¡ ºÒ°¡´ÉÇÑ »óÈ²

0x6~7: Reserved";
BA_ "UserSigValidity" SG_ 2244048130 ESC_HDP_EnblReq 3;
BA_ "RoutingFactor" SG_ 2244048130 ESC_HDP_EnblReq 5;
BA_ "Version" SG_ 2244048130 ESC_HDP_EnblReq "21.04.00";
BA_ "Description" SG_ 2244048130 CSC_WrngSta "This signal is used to display warning message on cluster and hud about crosswind stability control(CSC) function.";
BA_ "UserSigValidity" SG_ 2244048130 CSC_WrngSta 3;
BA_ "RoutingFactor" SG_ 2244048130 CSC_WrngSta 5;
BA_ "Version" SG_ 2244048130 CSC_WrngSta "22.01.06";
BA_ "Description" SG_ 2244048130 ESC_BrkdFltStndstill "The signal indicates state when vehicle is braked, flatland and standstill";
BA_ "UserSigValidity" SG_ 2244048130 ESC_BrkdFltStndstill 3;
BA_ "RoutingFactor" SG_ 2244048130 ESC_BrkdFltStndstill 5;
BA_ "Version" SG_ 2244048130 ESC_BrkdFltStndstill "20.12.04";
BA_ "Description" SG_ 2244048130 SCC_ReqLimSta "Due to limitaion of the actuators the acceleration or deceleration request from SCC can not be processed or only partly. 



Examples:

1. SCC is requesting more acceleration than the engine can deliver.

2. SCC is requesting deceleration on a low ¥ì surface.";
BA_ "UserSigValidity" SG_ 2244048130 SCC_ReqLimSta 3;
BA_ "RoutingFactor" SG_ 2244048130 SCC_ReqLimSta 5;
BA_ "Version" SG_ 2244048130 SCC_ReqLimSta "17.12.00";
BA_ "Description" SG_ 2244048130 ESC_StdStillVal "If an ESC uses active wheel speed sensors, wheel speeds down to 0 Km/h can be measured. And at 0 Km/h a StandStill flag is set in the ESC. This signal is used in the offset determination of the yaw rate and shall indicate that the vehicle has come to a complete stop.";
BA_ "UserSigValidity" SG_ 2244048130 ESC_StdStillVal 3;
BA_ "RoutingFactor" SG_ 2244048130 ESC_StdStillVal 5;
BA_ "Version" SG_ 2244048130 ESC_StdStillVal "17.12.00";
BA_ "GenMsgSendType" BO_ 2244048131 0;
BA_ "GenMsgCycleTime" BO_ 2244048131 100;
BA_ "GenMsgCycleTimeFast" BO_ 2244048131 0;
BA_ "GenMsgNrOfRepetition" BO_ 2244048131 0;
BA_ "VFrameFormat" BO_ 2244048131 1;
BA_ "Description" SG_ 2244048131 ESC_RccaSta "RCCA Brake Function Status";
BA_ "UserSigValidity" SG_ 2244048131 ESC_RccaSta 3;
BA_ "RoutingFactor" SG_ 2244048131 ESC_RccaSta 5;
BA_ "Version" SG_ 2244048131 ESC_RccaSta "17.12.00";
BA_ "Description" SG_ 2244048131 ESC_RspaCanFlFlag "This signal indicates RSPA CAN failure value.

E.g. Timeout, CRC error, Alive counter error, out of range signal value¡¦";
BA_ "UserSigValidity" SG_ 2244048131 ESC_RspaCanFlFlag 3;
BA_ "RoutingFactor" SG_ 2244048131 ESC_RspaCanFlFlag 5;
BA_ "Version" SG_ 2244048131 ESC_RspaCanFlFlag "17.12.00";
BA_ "Description" SG_ 2244048131 ESC_RspaDclActv "This signal indicates the additional braking control is activated for RSPA.

ESC activate additional deceleration to minimize vehicle speed overshoot.";
BA_ "UserSigValidity" SG_ 2244048131 ESC_RspaDclActv 3;
BA_ "RoutingFactor" SG_ 2244048131 ESC_RspaDclActv 5;
BA_ "Version" SG_ 2244048131 ESC_RspaDclActv "17.12.00";
BA_ "Description" SG_ 2244048131 ESC_RspaStandStill "This signal indicates confirmation for standstill of the vehicle.";
BA_ "UserSigValidity" SG_ 2244048131 ESC_RspaStandStill 3;
BA_ "RoutingFactor" SG_ 2244048131 ESC_RspaStandStill 5;
BA_ "Version" SG_ 2244048131 ESC_RspaStandStill "17.12.00";
BA_ "Description" SG_ 2244048131 ESC_PcaSta "PCA-R Brake Status";
BA_ "UserSigValidity" SG_ 2244048131 ESC_PcaSta 3;
BA_ "RoutingFactor" SG_ 2244048131 ESC_PcaSta 5;
BA_ "Version" SG_ 2244048131 ESC_PcaSta "17.12.06";
BA_ "Description" SG_ 2244048131 MCB_ReqBrkAck "This signal is about communication with ACU. It is changed with ACU_ReqBrk_By_PCB signal value.

If ESC receive 0x1 or 0x2 value of ACU_ReqBrk_By_PCB, signal value of MCB_ReqBrkAck change to 0x1.

If ESC receive 0x0 value of ACU_ReqBrk_By_PCB, signal value of MCB_ReqBrkAck change to 0x0.";
BA_ "UserSigValidity" SG_ 2244048131 MCB_ReqBrkAck 3;
BA_ "RoutingFactor" SG_ 2244048131 MCB_ReqBrkAck 5;
BA_ "Version" SG_ 2244048131 MCB_ReqBrkAck "18.12.05";
BA_ "Description" SG_ 2244048131 MCB_CtlSta "This signal indicate MCB activation status.";
BA_ "UserSigValidity" SG_ 2244048131 MCB_CtlSta 3;
BA_ "RoutingFactor" SG_ 2244048131 MCB_CtlSta 5;
BA_ "Version" SG_ 2244048131 MCB_CtlSta "19.05.02";
BA_ "Description" SG_ 2244048131 MCB_DefSta "This signal indicate MCB defective status.";
BA_ "UserSigValidity" SG_ 2244048131 MCB_DefSta 3;
BA_ "RoutingFactor" SG_ 2244048131 MCB_DefSta 5;
BA_ "Version" SG_ 2244048131 MCB_DefSta "19.05.02";
BA_ "Description" SG_ 2244048131 ESC_DiffBrkFuncSta "This is ESC status for Differential brake function.";
BA_ "UserSigValidity" SG_ 2244048131 ESC_DiffBrkFuncSta 3;
BA_ "RoutingFactor" SG_ 2244048131 ESC_DiffBrkFuncSta 5;
BA_ "Version" SG_ 2244048131 ESC_DiffBrkFuncSta "17.12.00";
BA_ "Description" SG_ 2244048131 ESC_LsdLimMod "This signal indicates the request for eLSD torque limit mode.

0x0:Maximum limitation mode

0x1:Minimum limitation mode";
BA_ "UserSigValidity" SG_ 2244048131 ESC_LsdLimMod 3;
BA_ "RoutingFactor" SG_ 2244048131 ESC_LsdLimMod 5;
BA_ "Version" SG_ 2244048131 ESC_LsdLimMod "18.05.02";
BA_ "Description" SG_ 2244048131 ESC_LsdOpn "This signal indicates the command for eLSD clutch open mode.";
BA_ "UserSigValidity" SG_ 2244048131 ESC_LsdOpn 3;
BA_ "RoutingFactor" SG_ 2244048131 ESC_LsdOpn 5;
BA_ "Version" SG_ 2244048131 ESC_LsdOpn "20.08.05";
BA_ "Description" SG_ 2244048131 ESC_LsdTqLim "This signal indicates the request for the value of the torquel limit of eLSD.

0xFFFF : Error";
BA_ "GenSigStartValue" SG_ 2244048131 ESC_LsdTqLim 64255;
BA_ "UserSigValidity" SG_ 2244048131 ESC_LsdTqLim 3;
BA_ "RoutingFactor" SG_ 2244048131 ESC_LsdTqLim 5;
BA_ "Version" SG_ 2244048131 ESC_LsdTqLim "18.05.02";
BA_ "Description" SG_ 2244048131 ESC_BcaRPlusSta "BCA-R+ Brake Function Status";
BA_ "UserSigValidity" SG_ 2244048131 ESC_BcaRPlusSta 3;
BA_ "RoutingFactor" SG_ 2244048131 ESC_BcaRPlusSta 5;
BA_ "Version" SG_ 2244048131 ESC_BcaRPlusSta "17.12.07";
BA_ "Description" SG_ 2244048131 ESC_RspaSta "This signal indicates RSPA assistant control mode of ESC";
BA_ "GenSigStartValue" SG_ 2244048131 ESC_RspaSta 1;
BA_ "UserSigValidity" SG_ 2244048131 ESC_RspaSta 3;
BA_ "RoutingFactor" SG_ 2244048131 ESC_RspaSta 5;
BA_ "Version" SG_ 2244048131 ESC_RspaSta "17.12.00";
BA_ "GenMsgCycleTime" BO_ 1874 0;
BA_ "GenMsgCycleTimeFast" BO_ 1874 0;
BA_ "GenMsgNrOfRepetition" BO_ 1874 0;
BA_ "DiagRequest" BO_ 1874 1;
BA_ "GenMsgILSupport" BO_ 1874 0;
BA_ "TpMessage" BO_ 1874 1;
BA_ "TpTxIndex" BO_ 1874 121;
BA_ "Description" SG_ 1874 GST_DLBCU_Byte0 "TP Index : 121";
BA_ "UsrSigPurpose" SG_ 1874 GST_DLBCU_Byte0 3;
BA_ "UserSigValidity" SG_ 1874 GST_DLBCU_Byte0 0;
BA_REL_ "GenSigTimeoutTime" BU_SG_REL_ DLBCU SG_ 1874 GST_DLBCU_Byte0 0;
BA_ "NetworkRequest" SG_ 1874 GST_DLBCU_Byte0 0;
BA_ "NetworkRequestHoldingTime" SG_ 1874 GST_DLBCU_Byte0 5000;
BA_ "Version" SG_ 1874 GST_DLBCU_Byte0 "21.02.04";
BA_ "Description" SG_ 1874 GST_DLBCU_Byte2 "TP Index : 121";
BA_ "UsrSigPurpose" SG_ 1874 GST_DLBCU_Byte2 3;
BA_ "UserSigValidity" SG_ 1874 GST_DLBCU_Byte2 0;
BA_REL_ "GenSigTimeoutTime" BU_SG_REL_ DLBCU SG_ 1874 GST_DLBCU_Byte2 0;
BA_ "NetworkRequest" SG_ 1874 GST_DLBCU_Byte2 0;
BA_ "NetworkRequestHoldingTime" SG_ 1874 GST_DLBCU_Byte2 5000;
BA_ "Version" SG_ 1874 GST_DLBCU_Byte2 "21.02.04";
BA_ "Description" SG_ 1874 GST_DLBCU_Byte3 "TP Index : 121";
BA_ "UsrSigPurpose" SG_ 1874 GST_DLBCU_Byte3 3;
BA_ "UserSigValidity" SG_ 1874 GST_DLBCU_Byte3 0;
BA_REL_ "GenSigTimeoutTime" BU_SG_REL_ DLBCU SG_ 1874 GST_DLBCU_Byte3 0;
BA_ "NetworkRequest" SG_ 1874 GST_DLBCU_Byte3 0;
BA_ "NetworkRequestHoldingTime" SG_ 1874 GST_DLBCU_Byte3 5000;
BA_ "Version" SG_ 1874 GST_DLBCU_Byte3 "21.02.04";
BA_ "Description" SG_ 1874 GST_DLBCU_Byte4 "TP Index : 121";
BA_ "UsrSigPurpose" SG_ 1874 GST_DLBCU_Byte4 3;
BA_ "UserSigValidity" SG_ 1874 GST_DLBCU_Byte4 0;
BA_REL_ "GenSigTimeoutTime" BU_SG_REL_ DLBCU SG_ 1874 GST_DLBCU_Byte4 0;
BA_ "NetworkRequest" SG_ 1874 GST_DLBCU_Byte4 0;
BA_ "NetworkRequestHoldingTime" SG_ 1874 GST_DLBCU_Byte4 5000;
BA_ "Version" SG_ 1874 GST_DLBCU_Byte4 "21.02.04";
BA_ "Description" SG_ 1874 GST_DLBCU_Byte5 "TP Index : 121";
BA_ "UsrSigPurpose" SG_ 1874 GST_DLBCU_Byte5 3;
BA_ "UserSigValidity" SG_ 1874 GST_DLBCU_Byte5 0;
BA_REL_ "GenSigTimeoutTime" BU_SG_REL_ DLBCU SG_ 1874 GST_DLBCU_Byte5 0;
BA_ "NetworkRequest" SG_ 1874 GST_DLBCU_Byte5 0;
BA_ "NetworkRequestHoldingTime" SG_ 1874 GST_DLBCU_Byte5 5000;
BA_ "Version" SG_ 1874 GST_DLBCU_Byte5 "21.02.04";
BA_ "Description" SG_ 1874 GST_DLBCU_Byte6 "TP Index : 121";
BA_ "UsrSigPurpose" SG_ 1874 GST_DLBCU_Byte6 3;
BA_ "UserSigValidity" SG_ 1874 GST_DLBCU_Byte6 0;
BA_REL_ "GenSigTimeoutTime" BU_SG_REL_ DLBCU SG_ 1874 GST_DLBCU_Byte6 0;
BA_ "NetworkRequest" SG_ 1874 GST_DLBCU_Byte6 0;
BA_ "NetworkRequestHoldingTime" SG_ 1874 GST_DLBCU_Byte6 5000;
BA_ "Version" SG_ 1874 GST_DLBCU_Byte6 "21.02.04";
BA_ "Description" SG_ 1874 GST_DLBCU_Byte7 "TP Index : 121";
BA_ "UsrSigPurpose" SG_ 1874 GST_DLBCU_Byte7 3;
BA_ "UserSigValidity" SG_ 1874 GST_DLBCU_Byte7 0;
BA_REL_ "GenSigTimeoutTime" BU_SG_REL_ DLBCU SG_ 1874 GST_DLBCU_Byte7 0;
BA_ "NetworkRequest" SG_ 1874 GST_DLBCU_Byte7 0;
BA_ "NetworkRequestHoldingTime" SG_ 1874 GST_DLBCU_Byte7 5000;
BA_ "Version" SG_ 1874 GST_DLBCU_Byte7 "21.02.04";
BA_ "Description" SG_ 1874 GST_DLBCU_Byte1 "TP Index : 121";
BA_ "UsrSigPurpose" SG_ 1874 GST_DLBCU_Byte1 3;
BA_ "UserSigValidity" SG_ 1874 GST_DLBCU_Byte1 0;
BA_REL_ "GenSigTimeoutTime" BU_SG_REL_ DLBCU SG_ 1874 GST_DLBCU_Byte1 0;
BA_ "NetworkRequest" SG_ 1874 GST_DLBCU_Byte1 0;
BA_ "NetworkRequestHoldingTime" SG_ 1874 GST_DLBCU_Byte1 5000;
BA_ "Version" SG_ 1874 GST_DLBCU_Byte1 "21.02.04";
BA_ "GenMsgCycleTime" BO_ 1873 0;
BA_ "GenMsgCycleTimeFast" BO_ 1873 0;
BA_ "GenMsgNrOfRepetition" BO_ 1873 0;
BA_ "DiagRequest" BO_ 1873 1;
BA_ "GenMsgILSupport" BO_ 1873 0;
BA_ "TpMessage" BO_ 1873 1;
BA_ "TpTxIndex" BO_ 1873 122;
BA_ "Description" SG_ 1873 GST_DPSS_Byte0 "TP Index : 122";
BA_ "UsrSigPurpose" SG_ 1873 GST_DPSS_Byte0 3;
BA_ "UserSigValidity" SG_ 1873 GST_DPSS_Byte0 0;
BA_REL_ "GenSigTimeoutTime" BU_SG_REL_ DPSU SG_ 1873 GST_DPSS_Byte0 0;
BA_ "NetworkRequest" SG_ 1873 GST_DPSS_Byte0 0;
BA_ "NetworkRequestHoldingTime" SG_ 1873 GST_DPSS_Byte0 5000;
BA_ "Version" SG_ 1873 GST_DPSS_Byte0 "21.02.04";
BA_ "Description" SG_ 1873 GST_DPSS_Byte2 "TP Index : 122";
BA_ "UsrSigPurpose" SG_ 1873 GST_DPSS_Byte2 3;
BA_ "UserSigValidity" SG_ 1873 GST_DPSS_Byte2 0;
BA_REL_ "GenSigTimeoutTime" BU_SG_REL_ DPSU SG_ 1873 GST_DPSS_Byte2 0;
BA_ "NetworkRequest" SG_ 1873 GST_DPSS_Byte2 0;
BA_ "NetworkRequestHoldingTime" SG_ 1873 GST_DPSS_Byte2 5000;
BA_ "Version" SG_ 1873 GST_DPSS_Byte2 "21.02.04";
BA_ "Description" SG_ 1873 GST_DPSS_Byte3 "TP Index : 122";
BA_ "UsrSigPurpose" SG_ 1873 GST_DPSS_Byte3 3;
BA_ "UserSigValidity" SG_ 1873 GST_DPSS_Byte3 0;
BA_REL_ "GenSigTimeoutTime" BU_SG_REL_ DPSU SG_ 1873 GST_DPSS_Byte3 0;
BA_ "NetworkRequest" SG_ 1873 GST_DPSS_Byte3 0;
BA_ "NetworkRequestHoldingTime" SG_ 1873 GST_DPSS_Byte3 5000;
BA_ "Version" SG_ 1873 GST_DPSS_Byte3 "21.02.04";
BA_ "Description" SG_ 1873 GST_DPSS_Byte4 "TP Index : 122";
BA_ "UsrSigPurpose" SG_ 1873 GST_DPSS_Byte4 3;
BA_ "UserSigValidity" SG_ 1873 GST_DPSS_Byte4 0;
BA_REL_ "GenSigTimeoutTime" BU_SG_REL_ DPSU SG_ 1873 GST_DPSS_Byte4 0;
BA_ "NetworkRequest" SG_ 1873 GST_DPSS_Byte4 0;
BA_ "NetworkRequestHoldingTime" SG_ 1873 GST_DPSS_Byte4 5000;
BA_ "Version" SG_ 1873 GST_DPSS_Byte4 "21.02.04";
BA_ "Description" SG_ 1873 GST_DPSS_Byte5 "TP Index : 122";
BA_ "UsrSigPurpose" SG_ 1873 GST_DPSS_Byte5 3;
BA_ "UserSigValidity" SG_ 1873 GST_DPSS_Byte5 0;
BA_REL_ "GenSigTimeoutTime" BU_SG_REL_ DPSU SG_ 1873 GST_DPSS_Byte5 0;
BA_ "NetworkRequest" SG_ 1873 GST_DPSS_Byte5 0;
BA_ "NetworkRequestHoldingTime" SG_ 1873 GST_DPSS_Byte5 5000;
BA_ "Version" SG_ 1873 GST_DPSS_Byte5 "21.02.04";
BA_ "Description" SG_ 1873 GST_DPSS_Byte6 "TP Index : 122";
BA_ "UsrSigPurpose" SG_ 1873 GST_DPSS_Byte6 3;
BA_ "UserSigValidity" SG_ 1873 GST_DPSS_Byte6 0;
BA_REL_ "GenSigTimeoutTime" BU_SG_REL_ DPSU SG_ 1873 GST_DPSS_Byte6 0;
BA_ "NetworkRequest" SG_ 1873 GST_DPSS_Byte6 0;
BA_ "NetworkRequestHoldingTime" SG_ 1873 GST_DPSS_Byte6 5000;
BA_ "Version" SG_ 1873 GST_DPSS_Byte6 "21.02.04";
BA_ "Description" SG_ 1873 GST_DPSS_Byte7 "TP Index : 122";
BA_ "UsrSigPurpose" SG_ 1873 GST_DPSS_Byte7 3;
BA_ "UserSigValidity" SG_ 1873 GST_DPSS_Byte7 0;
BA_REL_ "GenSigTimeoutTime" BU_SG_REL_ DPSU SG_ 1873 GST_DPSS_Byte7 0;
BA_ "NetworkRequest" SG_ 1873 GST_DPSS_Byte7 0;
BA_ "NetworkRequestHoldingTime" SG_ 1873 GST_DPSS_Byte7 5000;
BA_ "Version" SG_ 1873 GST_DPSS_Byte7 "21.02.04";
BA_ "Description" SG_ 1873 GST_DPSS_Byte1 "TP Index : 122";
BA_ "UsrSigPurpose" SG_ 1873 GST_DPSS_Byte1 3;
BA_ "UserSigValidity" SG_ 1873 GST_DPSS_Byte1 0;
BA_REL_ "GenSigTimeoutTime" BU_SG_REL_ DPSU SG_ 1873 GST_DPSS_Byte1 0;
BA_ "NetworkRequest" SG_ 1873 GST_DPSS_Byte1 0;
BA_ "NetworkRequestHoldingTime" SG_ 1873 GST_DPSS_Byte1 5000;
BA_ "Version" SG_ 1873 GST_DPSS_Byte1 "21.02.04";
BA_ "GenMsgSendType" BO_ 787 0;
BA_ "Description" SG_ 787 DPSU_DrvSlidePosition "DRIVER SEAT SLIDE POSITION (UNIT: mm)";
BA_ "GenSigSendType" SG_ 787 DPSU_DrvSlidePosition 4;
BA_ "UserSigValidity" SG_ 787 DPSU_DrvSlidePosition 0;
BA_REL_ "GenSigTimeoutTime" BU_SG_REL_ CGW_CCU SG_ 787 DPSU_DrvSlidePosition 1500;
BA_ "NetworkRequest" SG_ 787 DPSU_DrvSlidePosition 0;
BA_ "NetworkRequestHoldingTime" SG_ 787 DPSU_DrvSlidePosition 5000;
BA_ "Version" SG_ 787 DPSU_DrvSlidePosition "22.02.05";
BA_ "Description" SG_ 787 DPSU_DrvHeightPosition "DRIVER SEAT HEIGHT POSITION (UNIT: mm)";
BA_ "GenSigSendType" SG_ 787 DPSU_DrvHeightPosition 4;
BA_ "UserSigValidity" SG_ 787 DPSU_DrvHeightPosition 0;
BA_REL_ "GenSigTimeoutTime" BU_SG_REL_ CGW_CCU SG_ 787 DPSU_DrvHeightPosition 1500;
BA_ "NetworkRequest" SG_ 787 DPSU_DrvHeightPosition 0;
BA_ "NetworkRequestHoldingTime" SG_ 787 DPSU_DrvHeightPosition 5000;
BA_ "Version" SG_ 787 DPSU_DrvHeightPosition "22.02.05";
BA_ "Description" SG_ 787 DPSU_DrvReclinePosition "DRIVER SEAT RECLINE POSITION (UNIT: ¢ª)";
BA_ "GenSigSendType" SG_ 787 DPSU_DrvReclinePosition 4;
BA_ "UserSigValidity" SG_ 787 DPSU_DrvReclinePosition 0;
BA_REL_ "GenSigTimeoutTime" BU_SG_REL_ CGW_CCU SG_ 787 DPSU_DrvReclinePosition 1500;
BA_ "NetworkRequest" SG_ 787 DPSU_DrvReclinePosition 0;
BA_ "NetworkRequestHoldingTime" SG_ 787 DPSU_DrvReclinePosition 5000;
BA_ "Version" SG_ 787 DPSU_DrvReclinePosition "22.02.05";
BA_ "Description" SG_ 787 DPSU_DrvRelaxTiltPosition "DRIVER SEAT RELAX TILT POSITION (UNIT: ¢ª)";
BA_ "GenSigSendType" SG_ 787 DPSU_DrvRelaxTiltPosition 4;
BA_ "UserSigValidity" SG_ 787 DPSU_DrvRelaxTiltPosition 0;
BA_REL_ "GenSigTimeoutTime" BU_SG_REL_ CGW_CCU SG_ 787 DPSU_DrvRelaxTiltPosition 1500;
BA_ "NetworkRequest" SG_ 787 DPSU_DrvRelaxTiltPosition 0;
BA_ "NetworkRequestHoldingTime" SG_ 787 DPSU_DrvRelaxTiltPosition 5000;
BA_ "Version" SG_ 787 DPSU_DrvRelaxTiltPosition "22.02.05";
BA_ "GenMsgSendType" BO_ 799 0;
BA_ "Description" SG_ 799 SBCM_DRV_Crc1Val "The data area for CRC calculation is based on the data length (DLC) of the message DB.

The CRC shall be calculated over the entire data block (excluding the CRC bytes) including the user data, alive counter and Data ID 

 

- CRC Polynomial (0x1D) , Initial Value : 0x00, XOR value : 0xFF, Data ID Mode : Both, Data ID : Message ID + 0xF800 

- The initial value is for CRC calculation and the message should be sent with the calculated result value. 

The mathematical expression to 8 bit CRC polynomial is given here. G(x) = x8 + x4 + x3 + x2 + 1";
BA_ "GenSigSendType" SG_ 799 SBCM_DRV_Crc1Val 4;
BA_ "GenSigStartValue" SG_ 799 SBCM_DRV_Crc1Val 255;
BA_ "UserSigValidity" SG_ 799 SBCM_DRV_Crc1Val 0;
BA_ "Version" SG_ 799 SBCM_DRV_Crc1Val "19.07.06";
BA_ "Description" SG_ 799 DRV_CrashUnlockCmd "Drive Crash Unlock Command";
BA_ "GenSigSendType" SG_ 799 DRV_CrashUnlockCmd 4;
BA_ "UserSigValidity" SG_ 799 DRV_CrashUnlockCmd 0;
BA_REL_ "GenSigTimeoutTime" BU_SG_REL_ BLTN_CAM SG_ 799 DRV_CrashUnlockCmd 1500;
BA_ "NetworkRequest" SG_ 799 DRV_CrashUnlockCmd 0;
BA_ "Version" SG_ 799 DRV_CrashUnlockCmd "20.09.00";
BA_ "Description" SG_ 799 C_ApprOpenStatus "This is for Power Door System enable/disable signal.";
BA_ "GenSigSendType" SG_ 799 C_ApprOpenStatus 4;
BA_ "UserSigValidity" SG_ 799 C_ApprOpenStatus 0;
BA_ "Version" SG_ 799 C_ApprOpenStatus "20.09.00";
BA_ "Description" SG_ 799 SBCM_DRV_AlvCnt1Val "For the first transmission request for a data element the counter shall be initialized with 0 and shall be incremented by 1

for every subsequent send request. When the counter reaches the maximum value(0xE), then it shall restart with 0 for the next send request";
BA_ "GenSigSendType" SG_ 799 SBCM_DRV_AlvCnt1Val 4;
BA_ "UserSigValidity" SG_ 799 SBCM_DRV_AlvCnt1Val 0;
BA_ "Version" SG_ 799 SBCM_DRV_AlvCnt1Val "19.07.06";
BA_ "Description" SG_ 799 DoorLock_DrvKeyLkSwSta_SBCM "Door Lock Driver Mechanical Key Input Signal";
BA_ "GenSigSendType" SG_ 799 DoorLock_DrvKeyLkSwSta_SBCM 4;
BA_ "UserSigValidity" SG_ 799 DoorLock_DrvKeyLkSwSta_SBCM 0;
BA_ "NetworkRequest" SG_ 799 DoorLock_DrvKeyLkSwSta_SBCM 0;
BA_ "Version" SG_ 799 DoorLock_DrvKeyLkSwSta_SBCM "19.07.06";
BA_ "Description" SG_ 799 DoorLock_DrvKeyUnLkSwSta_SBCM "Door Drive Mechanical Key Unlock Switch State";
BA_ "GenSigSendType" SG_ 799 DoorLock_DrvKeyUnLkSwSta_SBCM 4;
BA_ "UserSigValidity" SG_ 799 DoorLock_DrvKeyUnLkSwSta_SBCM 0;
BA_ "NetworkRequest" SG_ 799 DoorLock_DrvKeyUnLkSwSta_SBCM 0;
BA_ "Version" SG_ 799 DoorLock_DrvKeyUnLkSwSta_SBCM "19.07.06";
BA_ "Description" SG_ 799 Warn_DrvDrSwSta_SBCM "Warning Drive Door Switch State";
BA_ "GenSigSendType" SG_ 799 Warn_DrvDrSwSta_SBCM 4;
BA_ "UserSigValidity" SG_ 799 Warn_DrvDrSwSta_SBCM 0;
BA_REL_ "GenSigTimeoutTime" BU_SG_REL_ WPC SG_ 799 Warn_DrvDrSwSta_SBCM 1500;
BA_REL_ "GenSigTimeoutTime" BU_SG_REL_ RWPC SG_ 799 Warn_DrvDrSwSta_SBCM 1500;
BA_REL_ "GenSigTimeoutTime" BU_SG_REL_ DPSU SG_ 799 Warn_DrvDrSwSta_SBCM 1500;
BA_REL_ "GenSigTimeoutTime" BU_SG_REL_ ATS SG_ 799 Warn_DrvDrSwSta_SBCM 1500;
BA_REL_ "GenSigTimeoutTime" BU_SG_REL_ BLTN_CAM SG_ 799 Warn_DrvDrSwSta_SBCM 1500;
BA_REL_ "GenSigTimeoutTime" BU_SG_REL_ WPC2 SG_ 799 Warn_DrvDrSwSta_SBCM 1500;
BA_ "NetworkRequest" SG_ 799 Warn_DrvDrSwSta_SBCM 0;
BA_ "Version" SG_ 799 Warn_DrvDrSwSta_SBCM "21.07.07";
BA_ "Description" SG_ 799 DoorLock_DrvDrUnLkSta_SBCM "Drive Door Lock Unlock Status";
BA_ "GenSigSendType" SG_ 799 DoorLock_DrvDrUnLkSta_SBCM 4;
BA_ "UserSigValidity" SG_ 799 DoorLock_DrvDrUnLkSta_SBCM 0;
BA_REL_ "GenSigTimeoutTime" BU_SG_REL_ ATS SG_ 799 DoorLock_DrvDrUnLkSta_SBCM 1500;
BA_ "NetworkRequest" SG_ 799 DoorLock_DrvDrUnLkSta_SBCM 0;
BA_ "Version" SG_ 799 DoorLock_DrvDrUnLkSta_SBCM "19.07.06";
BA_ "Description" SG_ 799 DRV_SEAWarn_LH "Drive (FLH) Door SEA Warning";
BA_ "GenSigSendType" SG_ 799 DRV_SEAWarn_LH 4;
BA_ "UserSigValidity" SG_ 799 DRV_SEAWarn_LH 0;
BA_ "NetworkRequest" SG_ 799 DRV_SEAWarn_LH 0;
BA_ "Version" SG_ 799 DRV_SEAWarn_LH "19.12.00";
BA_ "Description" SG_ 799 DRV_SEAWarn_RH "Drive (FRH) Door SEA Warning";
BA_ "GenSigSendType" SG_ 799 DRV_SEAWarn_RH 4;
BA_ "UserSigValidity" SG_ 799 DRV_SEAWarn_RH 0;
BA_ "NetworkRequest" SG_ 799 DRV_SEAWarn_RH 0;
BA_ "Version" SG_ 799 DRV_SEAWarn_RH "19.12.07";
BA_ "Description" SG_ 799 DRV_SEWWarn_LH "Drive (FLH) Door Safety Exit Warning";
BA_ "GenSigSendType" SG_ 799 DRV_SEWWarn_LH 4;
BA_ "UserSigValidity" SG_ 799 DRV_SEWWarn_LH 0;
BA_ "NetworkRequest" SG_ 799 DRV_SEWWarn_LH 0;
BA_ "Version" SG_ 799 DRV_SEWWarn_LH "20.09.00";
BA_ "Description" SG_ 799 DRV_SEWWarn_RH "Drive (FRH) Door Safety Exit Warning";
BA_ "GenSigSendType" SG_ 799 DRV_SEWWarn_RH 4;
BA_ "UserSigValidity" SG_ 799 DRV_SEWWarn_RH 0;
BA_ "NetworkRequest" SG_ 799 DRV_SEWWarn_RH 0;
BA_ "Version" SG_ 799 DRV_SEWWarn_RH "20.09.00";
BA_ "GenSigSendType" SG_ 799 DRV_MRActivationAlarm 4;
BA_ "UserSigValidity" SG_ 799 DRV_MRActivationAlarm 0;
BA_ "NetworkRequest" SG_ 799 DRV_MRActivationAlarm 0;
BA_ "NetworkRequestHoldingTime" SG_ 799 DRV_MRActivationAlarm 5000;
BA_ "Version" SG_ 799 DRV_MRActivationAlarm "19.11.05";
BA_ "GenSigSendType" SG_ 799 DRV_ReleaseWarn 4;
BA_ "UserSigValidity" SG_ 799 DRV_ReleaseWarn 0;
BA_ "NetworkRequest" SG_ 799 DRV_ReleaseWarn 0;
BA_ "NetworkRequestHoldingTime" SG_ 799 DRV_ReleaseWarn 5000;
BA_ "Version" SG_ 799 DRV_ReleaseWarn "19.11.05";
BA_ "Description" SG_ 799 Latch_TypeOption_DRV "If the E-Lacth is applied, the signal will be send for identify the door lock/unlock function and option.";
BA_ "GenSigSendType" SG_ 799 Latch_TypeOption_DRV 4;
BA_ "UserSigValidity" SG_ 799 Latch_TypeOption_DRV 0;
BA_ "NetworkRequest" SG_ 799 Latch_TypeOption_DRV 0;
BA_ "Version" SG_ 799 Latch_TypeOption_DRV "20.09.00";
BA_ "GenSigSendType" SG_ 799 DRV_SWFailAlarm 4;
BA_ "UserSigValidity" SG_ 799 DRV_SWFailAlarm 0;
BA_ "NetworkRequest" SG_ 799 DRV_SWFailAlarm 0;
BA_ "NetworkRequestHoldingTime" SG_ 799 DRV_SWFailAlarm 5000;
BA_ "Version" SG_ 799 DRV_SWFailAlarm "19.11.05";
BA_ "GenSigSendType" SG_ 799 USM_PwrDRApprOpnSetSta 4;
BA_ "UserSigValidity" SG_ 799 USM_PwrDRApprOpnSetSta 0;
BA_ "NetworkRequest" SG_ 799 USM_PwrDRApprOpnSetSta 0;
BA_ "NetworkRequestHoldingTime" SG_ 799 USM_PwrDRApprOpnSetSta 5000;
BA_ "Version" SG_ 799 USM_PwrDRApprOpnSetSta "20.12.03";
BA_ "GenSigSendType" SG_ 799 USM_PwrDRApprOpnSetOpt 4;
BA_ "UserSigValidity" SG_ 799 USM_PwrDRApprOpnSetOpt 0;
BA_ "NetworkRequest" SG_ 799 USM_PwrDRApprOpnSetOpt 0;
BA_ "NetworkRequestHoldingTime" SG_ 799 USM_PwrDRApprOpnSetOpt 5000;
BA_ "Version" SG_ 799 USM_PwrDRApprOpnSetOpt "20.12.03";
BA_ "GenSigSendType" SG_ 799 USM_PwrDRCloseByRKELockSta 4;
BA_ "UserSigValidity" SG_ 799 USM_PwrDRCloseByRKELockSta 0;
BA_ "NetworkRequest" SG_ 799 USM_PwrDRCloseByRKELockSta 0;
BA_ "NetworkRequestHoldingTime" SG_ 799 USM_PwrDRCloseByRKELockSta 5000;
BA_ "Version" SG_ 799 USM_PwrDRCloseByRKELockSta "20.12.03";
BA_ "GenSigSendType" SG_ 799 USM_PwrDRCloseByRKELockOpt 4;
BA_ "UserSigValidity" SG_ 799 USM_PwrDRCloseByRKELockOpt 0;
BA_ "NetworkRequest" SG_ 799 USM_PwrDRCloseByRKELockOpt 0;
BA_ "NetworkRequestHoldingTime" SG_ 799 USM_PwrDRCloseByRKELockOpt 5000;
BA_ "Version" SG_ 799 USM_PwrDRCloseByRKELockOpt "20.12.03";
BA_ "GenSigSendType" SG_ 799 USM_PwrDRCloseByBrakeSta 4;
BA_ "UserSigValidity" SG_ 799 USM_PwrDRCloseByBrakeSta 0;
BA_ "NetworkRequest" SG_ 799 USM_PwrDRCloseByBrakeSta 0;
BA_ "NetworkRequestHoldingTime" SG_ 799 USM_PwrDRCloseByBrakeSta 5000;
BA_ "Version" SG_ 799 USM_PwrDRCloseByBrakeSta "20.12.03";
BA_ "GenSigSendType" SG_ 799 USM_PwrDRCloseByBrakeOpt 4;
BA_ "UserSigValidity" SG_ 799 USM_PwrDRCloseByBrakeOpt 0;
BA_ "NetworkRequest" SG_ 799 USM_PwrDRCloseByBrakeOpt 0;
BA_ "NetworkRequestHoldingTime" SG_ 799 USM_PwrDRCloseByBrakeOpt 5000;
BA_ "Version" SG_ 799 USM_PwrDRCloseByBrakeOpt "20.12.03";
BA_ "GenSigSendType" SG_ 799 USM_PwrDRBuzzerSta 4;
BA_ "UserSigValidity" SG_ 799 USM_PwrDRBuzzerSta 0;
BA_ "NetworkRequest" SG_ 799 USM_PwrDRBuzzerSta 0;
BA_ "NetworkRequestHoldingTime" SG_ 799 USM_PwrDRBuzzerSta 5000;
BA_ "Version" SG_ 799 USM_PwrDRBuzzerSta "20.12.03";
BA_ "GenSigSendType" SG_ 799 USM_PwrDRBuzzerOpt 4;
BA_ "UserSigValidity" SG_ 799 USM_PwrDRBuzzerOpt 0;
BA_ "NetworkRequest" SG_ 799 USM_PwrDRBuzzerOpt 0;
BA_ "NetworkRequestHoldingTime" SG_ 799 USM_PwrDRBuzzerOpt 5000;
BA_ "Version" SG_ 799 USM_PwrDRBuzzerOpt "20.12.03";
BA_ "GenSigSendType" SG_ 799 PDS_TypeOption_DRV 4;
BA_ "UserSigValidity" SG_ 799 PDS_TypeOption_DRV 0;
BA_ "NetworkRequest" SG_ 799 PDS_TypeOption_DRV 0;
BA_ "Version" SG_ 799 PDS_TypeOption_DRV "20.09.00";
BA_ "Description" SG_ 799 C_DrvDoorApproachOpen "Fob searching start and stop signal for PDS.";
BA_ "GenSigSendType" SG_ 799 C_DrvDoorApproachOpen 4;
BA_ "UserSigValidity" SG_ 799 C_DrvDoorApproachOpen 0;
BA_ "Version" SG_ 799 C_DrvDoorApproachOpen "20.09.00";
BA_ "Description" SG_ 799 C_DrvDoorApproachClose "To close the door automatically, request the fob searching signal";
BA_ "GenSigSendType" SG_ 799 C_DrvDoorApproachClose 4;
BA_ "UserSigValidity" SG_ 799 C_DrvDoorApproachClose 0;
BA_ "Version" SG_ 799 C_DrvDoorApproachClose "20.09.00";
BA_ "GenSigSendType" SG_ 799 DoorLock_PDSLkSwSta_DRV 4;
BA_ "UserSigValidity" SG_ 799 DoorLock_PDSLkSwSta_DRV 0;
BA_ "NetworkRequest" SG_ 799 DoorLock_PDSLkSwSta_DRV 0;
BA_ "Version" SG_ 799 DoorLock_PDSLkSwSta_DRV "20.09.00";
BA_ "GenSigSendType" SG_ 799 DRVDoorPushAlarm 4;
BA_ "UserSigValidity" SG_ 799 DRVDoorPushAlarm 0;
BA_ "NetworkRequest" SG_ 799 DRVDoorPushAlarm 0;
BA_ "NetworkRequestHoldingTime" SG_ 799 DRVDoorPushAlarm 5000;
BA_ "Version" SG_ 799 DRVDoorPushAlarm "20.09.00";
BA_ "GenMsgSendType" BO_ 2164277249 0;
BA_ "GenMsgCycleTime" BO_ 2164277249 50;
BA_ "GenMsgCycleTimeFast" BO_ 2164277249 0;
BA_ "GenMsgNrOfRepetition" BO_ 2164277249 0;
BA_ "VFrameFormat" BO_ 2164277249 1;
BA_ "Description" SG_ 2164277249 TCU_Crc1Val "The data area for CRC calculation is based on the data length (DLC) of the message DB.

The CRC shall be calculated over the entire data block (excluding the CRC bytes) including the user data, alive counter and Data ID

 

- CRC Polynomial (0x1021) , Initial Value : 0xFFFF, XOR value : 0x0000, Data ID : Message ID + 0xF800 

- The initial value is for CRC calculation and the message should be sent with the calculated result value. 

- The mathematical expression to 16 bit CRC polynomial is given here. G(x) = x16 + x12 + x5 + 1";
BA_ "GenSigStartValue" SG_ 2164277249 TCU_Crc1Val 65535;
BA_ "UserSigValidity" SG_ 2164277249 TCU_Crc1Val 3;
BA_ "RoutingFactor" SG_ 2164277249 TCU_Crc1Val 5;
BA_ "Version" SG_ 2164277249 TCU_Crc1Val "18.11.08";
BA_ "Description" SG_ 2164277249 TCU_AlvCnt1Val "For the first transmission request for a data element the counter shall be initialized with 0 and shall be incremented by 1 for every subsequent send request. 

When the counter reaches the maximum value(0xFF), then it shall restart with 0 for the next send request";
BA_ "UserSigValidity" SG_ 2164277249 TCU_AlvCnt1Val 3;
BA_ "RoutingFactor" SG_ 2164277249 TCU_AlvCnt1Val 5;
BA_ "Version" SG_ 2164277249 TCU_AlvCnt1Val "18.11.08";
BA_ "Description" SG_ 2164277249 TCU_GearSlctDis "Position (P, R, N..), which was identified by the gear selector.

In case the gear selector is in a intermediate position, the last clear recognized position is used.

There is no specific phase relationship between the output and any other signal.";
BA_ "GenSigStartValue" SG_ 2164277249 TCU_GearSlctDis 9;
BA_ "UserSigValidity" SG_ 2164277249 TCU_GearSlctDis 3;
BA_ "RoutingFactor" SG_ 2164277249 TCU_GearSlctDis 5;
BA_ "Version" SG_ 2164277249 TCU_GearSlctDis "17.11.00";
BA_ "Description" SG_ 2164277249 TCU_Typ "Information regarding the type of transmission - Step A/T or CVT or DCT / AMT / eClutch";
BA_ "UserSigValidity" SG_ 2164277249 TCU_Typ 3;
BA_ "RoutingFactor" SG_ 2164277249 TCU_Typ 5;
BA_ "Version" SG_ 2164277249 TCU_Typ "18.12.02";
BA_ "Description" SG_ 2164277249 TCU_TqRdctnVal "The TCU requests a torque reduction via this signal to the EMS. 



If MSB is 1, this signal is - value.

else, this signal is +value.

0~10bit is used for absolute value.";
BA_ "GenSigStartValue" SG_ 2164277249 TCU_TqRdctnVal 2047;
BA_ "UserSigValidity" SG_ 2164277249 TCU_TqRdctnVal 3;
BA_ "RoutingFactor" SG_ 2164277249 TCU_TqRdctnVal 5;
BA_ "Version" SG_ 2164277249 TCU_TqRdctnVal "20.03.05";
BA_ "Description" SG_ 2164277249 TCU_GearStepTyp "This signal indicates number of gear steps of step type automatic transmission(A/T) or Dual Clutch Transmission(DCT). A vehicle can have A/T or DCT variant according to its option, for example 4-speed A/T or 5-speed A/T can be equipped in the same kind of vehicles and other control systems (e.g. ESC, TCS, ¡¦) can need this information to apply appropriate control logic.



The CVT (Continuously Variable Transmission) should set this signal to 00H.";
BA_ "UserSigValidity" SG_ 2164277249 TCU_GearStepTyp 3;
BA_ "RoutingFactor" SG_ 2164277249 TCU_GearStepTyp 5;
BA_ "Version" SG_ 2164277249 TCU_GearStepTyp "19.02.07";
BA_ "Description" SG_ 2164277249 TCU_GearShftSta "SWI_GS indicates whether a gear change is being executed in the gearbox.



Note : Gear change means a gear shift at D-range and Garage shift(PRND).";
BA_ "UserSigValidity" SG_ 2164277249 TCU_GearShftSta 3;
BA_ "RoutingFactor" SG_ 2164277249 TCU_GearShftSta 5;
BA_ "Version" SG_ 2164277249 TCU_GearShftSta "17.11.00";
BA_ "Description" SG_ 2164277249 TCU_TqCnvrtrSta "Status converter clutch



There is no specific phase relationship between the output and any other signal.";
BA_ "UserSigValidity" SG_ 2164277249 TCU_TqCnvrtrSta 3;
BA_ "RoutingFactor" SG_ 2164277249 TCU_TqCnvrtrSta 5;
BA_ "Version" SG_ 2164277249 TCU_TqCnvrtrSta "17.11.00";
BA_ "GenMsgSendType" BO_ 2164277250 0;
BA_ "GenMsgCycleTime" BO_ 2164277250 50;
BA_ "GenMsgCycleTimeFast" BO_ 2164277250 0;
BA_ "GenMsgNrOfRepetition" BO_ 2164277250 0;
BA_ "VFrameFormat" BO_ 2164277250 1;
BA_ "Description" SG_ 2164277250 TCU_CurrGearSta "CUR_GR indicates the gear speed which is currently engaged in the gearbox.";
BA_ "UserSigValidity" SG_ 2164277250 TCU_CurrGearSta 3;
BA_ "RoutingFactor" SG_ 2164277250 TCU_CurrGearSta 5;
BA_ "Version" SG_ 2164277250 TCU_CurrGearSta "17.11.00";
BA_ "Description" SG_ 2164277250 TCH_EngTrgtGearSta "TCH_EngTrgtGearSta informs about target gear of SS timing 

(For indicating Paddle shift or Manual mode on cluster)";
BA_ "UserSigValidity" SG_ 2164277250 TCH_EngTrgtGearSta 3;
BA_ "RoutingFactor" SG_ 2164277250 TCH_EngTrgtGearSta 5;
BA_ "Version" SG_ 2164277250 TCH_EngTrgtGearSta "17.11.00";
BA_ "Description" SG_ 2164277250 TCU_EngTqLimVal "The TCU requests a engine torque limit(ETL) from the EMS. 

There is no time limitation of the intervention.

TCU requests engine torque limit below the TCU requesting torque.

The engine torque request signal means the absolute torque limitation.

TCU sends it through CAN system and makes it change every moment.

In any non-requesting situations, TCU sends the maximum value of CAN message.



If MSB is 1, this signal is - value.

else, this signal is +value.

0~10bit is used for absolute value.";
BA_ "GenSigStartValue" SG_ 2164277250 TCU_EngTqLimVal 2047;
BA_ "UserSigValidity" SG_ 2164277250 TCU_EngTqLimVal 3;
BA_ "RoutingFactor" SG_ 2164277250 TCU_EngTqLimVal 5;
BA_ "Version" SG_ 2164277250 TCU_EngTqLimVal "20.03.05";
BA_ "Description" SG_ 2164277250 TCU_CluTrgtGearConfg "This signal indicates the signal source configuration of target gear for CLU";
BA_ "UserSigValidity" SG_ 2164277250 TCU_CluTrgtGearConfg 3;
BA_ "RoutingFactor" SG_ 2164277250 TCU_CluTrgtGearConfg 5;
BA_ "Version" SG_ 2164277250 TCU_CluTrgtGearConfg "18.08.01";
BA_ "Description" SG_ 2164277250 TCU_VehSpdKphVal "The vehicle speed calculated by TCU is transferred. 

If a vehicle has no vehicle speed sensor, no wheel speed sensor and no ABS(TCS/ESC) then it is impossible for an EMS to calculate veficle speed. In this case a TCU should calculate vehicle speed and send to other ECUs.

The calculation can be done with output speed of gearbox, final gear ratio and actual radius of a tire. 

In case of failure the value FFH is used as error identifier.";
BA_ "UserSigValidity" SG_ 2164277250 TCU_VehSpdKphVal 3;
BA_ "RoutingFactor" SG_ 2164277250 TCU_VehSpdKphVal 5;
BA_ "Version" SG_ 2164277250 TCU_VehSpdKphVal "17.11.00";
BA_ "Description" SG_ 2164277250 TCU_TrgtGearSta "CF_Tcu_TarGr informs about the speed, which is currently engaged in the gearbox, or, in case of a gear change (SWI_GS), which speed is reached.



Note: Gear changes covering more than one speed are also possible.

In the P and N positions, the frictional connection is interrupted hydraulically.

Depending on the type of error, the 3rd or 4th (forward) speed, and the R (reverse) speed are engaged in the limp home program.";
BA_ "UserSigValidity" SG_ 2164277250 TCU_TrgtGearSta 3;
BA_ "RoutingFactor" SG_ 2164277250 TCU_TrgtGearSta 5;
BA_ "Version" SG_ 2164277250 TCU_TrgtGearSta "17.11.00";
BA_ "Description" SG_ 2164277250 TCU_DcmlVehSpdKphVal "The signal VS_TCU_DECIAMAL means the value which is below decimal point of the vehicle speed.

For instance, if a vehicle speed is 13.75Km/h, VS_TCU means 13Km/h and VS_TCU_DECIMAL means 0.75Km/h.



Example)   VS_TCU = 13,  VS_TCU_DECIAMAL  = 96

Vehicle speed  = VS_TCU + ( VS_TCU_DECIMAL / 128 )

= 13 + ( 96 / 128 ) = 13.75 [Km/h]";
BA_ "UserSigValidity" SG_ 2164277250 TCU_DcmlVehSpdKphVal 3;
BA_ "RoutingFactor" SG_ 2164277250 TCU_DcmlVehSpdKphVal 5;
BA_ "Version" SG_ 2164277250 TCU_DcmlVehSpdKphVal "17.11.00";
BA_ "Description" SG_ 2164277250 TCU_SprkRtrdReq "The TCU requests a spark angle retard via the signal SPK_RTD_TCU to the EMS for torque reduction during the gear engage condition.



(PH) = ((HEX) - 3FH) * 0.375 (Advance) (PH) = (3FH - (HEX)) * (-0.375) (Retard)

-15¢ª  ... 0¢ª= 17H .. 3FH (Retard)

0.375¢ª. 15¢ª= 40H .. 67H (Advance)";
BA_ "GenSigStartValue" SG_ 2164277250 TCU_SprkRtrdReq 255;
BA_ "UserSigValidity" SG_ 2164277250 TCU_SprkRtrdReq 3;
BA_ "RoutingFactor" SG_ 2164277250 TCU_SprkRtrdReq 5;
BA_ "Version" SG_ 2164277250 TCU_SprkRtrdReq "17.11.00";
BA_ "Description" SG_ 2164277250 TCU_EngRpmDisSta "Flag for Engine RPM(from TCU) Display on Cluster, Only when this flag is set to 1, Cluster shall display the Engine RPM from TCU";
BA_ "UserSigValidity" SG_ 2164277250 TCU_EngRpmDisSta 3;
BA_ "RoutingFactor" SG_ 2164277250 TCU_EngRpmDisSta 5;
BA_ "Version" SG_ 2164277250 TCU_EngRpmDisSta "17.11.00";
BA_ "Description" SG_ 2164277250 TCU_GearLmpBlnkngReq "Cluster controls blinking of Gear lamp receiving the request signal from TCU.";
BA_ "UserSigValidity" SG_ 2164277250 TCU_GearLmpBlnkngReq 3;
BA_ "RoutingFactor" SG_ 2164277250 TCU_GearLmpBlnkngReq 5;
BA_ "Version" SG_ 2164277250 TCU_GearLmpBlnkngReq "17.11.00";
BA_ "Description" SG_ 2164277250 TCU_FuelCutInhbtReq "During coast down shifting, EMS may cut off fuel injection and as a result, a driver can feel bad shift feeling. In this case, to enhance shift quality, TCU needs inhibition of fuel cut off control.

This signal indicates inhibition of engine fuel cut off control.";
BA_ "UserSigValidity" SG_ 2164277250 TCU_FuelCutInhbtReq 3;
BA_ "RoutingFactor" SG_ 2164277250 TCU_FuelCutInhbtReq 5;
BA_ "Version" SG_ 2164277250 TCU_FuelCutInhbtReq "17.11.00";
BA_ "Description" SG_ 2164277250 TCU_IdleUpReq "When ATF(Automatic Transmission Fluid) rises in high temperauture, the TCU requests engine idle RPM up via the signal IDLE_UP_TCU to the EMS for reduction of gearshift time form Neutral to Reverse.



THIS SIGNAL IS FOR ¡°LAMBDA ENGINE¡± SYSTEM ONLY.";
BA_ "UserSigValidity" SG_ 2164277250 TCU_IdleUpReq 3;
BA_ "RoutingFactor" SG_ 2164277250 TCU_IdleUpReq 5;
BA_ "Version" SG_ 2164277250 TCU_IdleUpReq "17.11.00";
BA_ "Description" SG_ 2164277250 TCU_CluTrgtGearSta "TCH_CluTrgtGearSta informs about target gear of SS timing 

(For indicating Paddle shift or Manual mode on cluster)";
BA_ "UserSigValidity" SG_ 2164277250 TCU_CluTrgtGearSta 3;
BA_ "RoutingFactor" SG_ 2164277250 TCU_CluTrgtGearSta 5;
BA_ "Version" SG_ 2164277250 TCU_CluTrgtGearSta "17.11.00";
BA_ "GenMsgSendType" BO_ 2164277251 0;
BA_ "GenMsgCycleTime" BO_ 2164277251 50;
BA_ "GenMsgCycleTimeFast" BO_ 2164277251 0;
BA_ "GenMsgNrOfRepetition" BO_ 2164277251 0;
BA_ "VFrameFormat" BO_ 2164277251 1;
BA_ "Description" SG_ 2164277251 TCU_EngRpmDis "Engine RPM from TCU (Only for the display on Cluster)";
BA_ "UserSigValidity" SG_ 2164277251 TCU_EngRpmDis 3;
BA_ "RoutingFactor" SG_ 2164277251 TCU_EngRpmDis 5;
BA_ "Version" SG_ 2164277251 TCU_EngRpmDis "17.11.00";
BA_ "Description" SG_ 2164277251 TCU_SlpVal "This signal is used to avoid busy shifting during uphill driving.

It is calculated using engine torque, turbine torque and gearbox torque so on.

It has some restrictions like the following sentences

- No slope calculation during shifting, braking, 1st gear, or at low oil temperature (Under 10 degree).

- The slope calculation is inaccurate at low vehicle speed (under 30 KPH).

- Slope is calculated according to (CVW + 180Kg). It means that if the vehicle weight increases more than it, then the calculated slope value increases.

If calculated road gradient is less than -16%, SLOPE_TCU should be set to 00h, and if calculated road gradient is more than 15.5%, SLOPE_TCU should be set to 3Fh.";
BA_ "GenSigStartValue" SG_ 2164277251 TCU_SlpVal 32;
BA_ "UserSigValidity" SG_ 2164277251 TCU_SlpVal 3;
BA_ "RoutingFactor" SG_ 2164277251 TCU_SlpVal 5;
BA_ "Version" SG_ 2164277251 TCU_SlpVal "17.11.00";
BA_ "Description" SG_ 2164277251 TCU_EngSpdIncReq "This signal is a target engine speed requirement start flag signal by TCU, 

which is sent to ECU. It is synchronized to the signal engine speed increasing target speed value.";
BA_ "UserSigValidity" SG_ 2164277251 TCU_EngSpdIncReq 3;
BA_ "RoutingFactor" SG_ 2164277251 TCU_EngSpdIncReq 5;
BA_ "Version" SG_ 2164277251 TCU_EngSpdIncReq "17.11.00";
BA_ "Description" SG_ 2164277251 TCU_ObdSta "The signal TCU_OBD is used to inform the OBD master (EMS-ECU) in case a OBD relevant fault is detected. According to the OBD regulations the TCU could request MIL on. If a freeze frame request by the TCU has not been acknowledged (OBD_FRF_ACK) within 2 seconds, this request has to be canceled.

-> Related signal : See ¡°EngFrzFrm¡± message

Bit0 : Reserved

Bit1 : Failure information of TCU

Bit2 : MIL on request



The exact meaning of this signals and under which conditions they are used has to be defined by the TCU supplier (in accordance with the OBD II regulations).";
BA_ "UserSigValidity" SG_ 2164277251 TCU_ObdSta 3;
BA_ "RoutingFactor" SG_ 2164277251 TCU_ObdSta 5;
BA_ "Version" SG_ 2164277251 TCU_ObdSta "19.02.07";
BA_ "Description" SG_ 2164277251 TCU_SprtyIndxSta "Sporty index based on the driver's driving behaviour";
BA_ "UserSigValidity" SG_ 2164277251 TCU_SprtyIndxSta 3;
BA_ "RoutingFactor" SG_ 2164277251 TCU_SprtyIndxSta 5;
BA_ "Version" SG_ 2164277251 TCU_SprtyIndxSta "17.11.00";
BA_ "Description" SG_ 2164277251 TCU_DrvngModDis "Driving mode display by TCU";
BA_ "UserSigValidity" SG_ 2164277251 TCU_DrvngModDis 3;
BA_ "RoutingFactor" SG_ 2164277251 TCU_DrvngModDis 5;
BA_ "Version" SG_ 2164277251 TCU_DrvngModDis "17.11.00";
BA_ "Description" SG_ 2164277251 TCU_DrvngModReq "Driving mode request with Normal, Eco, Eco+, Sport, Sport+

and Snow only TCU automode is on, otherwise, inactive";
BA_ "UserSigValidity" SG_ 2164277251 TCU_DrvngModReq 3;
BA_ "RoutingFactor" SG_ 2164277251 TCU_DrvngModReq 5;
BA_ "Version" SG_ 2164277251 TCU_DrvngModReq "17.11.00";
BA_ "Description" SG_ 2164277251 TCU_SmrtShftSta "Information of SmartShift";
BA_ "UserSigValidity" SG_ 2164277251 TCU_SmrtShftSta 3;
BA_ "RoutingFactor" SG_ 2164277251 TCU_SmrtShftSta 5;
BA_ "Version" SG_ 2164277251 TCU_SmrtShftSta "17.11.00";
BA_ "Description" SG_ 2164277251 TCU_LupTrgtEngSpdVal "This signal is a target engine speed requested by TCU, which is sent to ECU. 

It is intended for OFF-SLIP to be more successful in triggering fuel cut-off under more various driving conditions.";
BA_ "GenSigStartValue" SG_ 2164277251 TCU_LupTrgtEngSpdVal 255;
BA_ "UserSigValidity" SG_ 2164277251 TCU_LupTrgtEngSpdVal 3;
BA_ "RoutingFactor" SG_ 2164277251 TCU_LupTrgtEngSpdVal 5;
BA_ "Version" SG_ 2164277251 TCU_LupTrgtEngSpdVal "17.11.00";
BA_ "Description" SG_ 2164277251 TCU_FrtStcShftSta "Status of fisrt static shift";
BA_ "UserSigValidity" SG_ 2164277251 TCU_FrtStcShftSta 3;
BA_ "RoutingFactor" SG_ 2164277251 TCU_FrtStcShftSta 5;
BA_ "Version" SG_ 2164277251 TCU_FrtStcShftSta "17.11.00";
BA_ "Description" SG_ 2164277251 TCU_IsgInhbtReq "TCU requests ECU to inhibit the ISG function when ISG start condition of AT is not met (oil temp is too low , AT ISG system malfunction, etc ¡¦ )";
BA_ "UserSigValidity" SG_ 2164277251 TCU_IsgInhbtReq 3;
BA_ "RoutingFactor" SG_ 2164277251 TCU_IsgInhbtReq 5;
BA_ "Version" SG_ 2164277251 TCU_IsgInhbtReq "17.11.00";
BA_ "Description" SG_ 2164277251 TCU_CdaInhbtReq "TCU requests ECU to prohibit the CDA transition during gear shifting or lock-up clutch operation in the automatic transmission in order to prevent a shock on the vehicle. Without gear shifting and lock-up clutch operation, CDA transition can be performed.";
BA_ "UserSigValidity" SG_ 2164277251 TCU_CdaInhbtReq 3;
BA_ "RoutingFactor" SG_ 2164277251 TCU_CdaInhbtReq 5;
BA_ "Version" SG_ 2164277251 TCU_CdaInhbtReq "17.11.00";
BA_ "Description" SG_ 2164277251 TCU_BrkOnReq "The TCU request the ESC to activate the Brake.

The ESC holds the Brake ON during the TCU¡¯s Brake ON Request.";
BA_ "UserSigValidity" SG_ 2164277251 TCU_BrkOnReq 3;
BA_ "RoutingFactor" SG_ 2164277251 TCU_BrkOnReq 5;
BA_ "Version" SG_ 2164277251 TCU_BrkOnReq "17.11.00";
BA_ "Description" SG_ 2164277251 TCU_TqGrdntLimVal "TCU requests EMS to perform the engine torque gradient limitation control with a rate of Nm per second(Nm/sec).



Downshift : The engine torque gradient limitation for downshift will be a function of pedal and shift-time. 

Upshift : The engine torque gradient limitation for upshift will be a function of shift-time.";
BA_ "UserSigValidity" SG_ 2164277251 TCU_TqGrdntLimVal 3;
BA_ "RoutingFactor" SG_ 2164277251 TCU_TqGrdntLimVal 5;
BA_ "Version" SG_ 2164277251 TCU_TqGrdntLimVal "17.11.00";
BA_ "GenMsgSendType" BO_ 2164277252 0;
BA_ "GenMsgCycleTime" BO_ 2164277252 50;
BA_ "GenMsgCycleTimeFast" BO_ 2164277252 0;
BA_ "GenMsgNrOfRepetition" BO_ 2164277252 0;
BA_ "VFrameFormat" BO_ 2164277252 1;
BA_ "Description" SG_ 2164277252 TCU_NetrlCtrlSta "This signal indicates the status of Neutral Control.";
BA_ "UserSigValidity" SG_ 2164277252 TCU_NetrlCtrlSta 3;
BA_ "RoutingFactor" SG_ 2164277252 TCU_NetrlCtrlSta 5;
BA_ "Version" SG_ 2164277252 TCU_NetrlCtrlSta "17.11.00";
BA_ "Description" SG_ 2164277252 TCU_ShftPtrnSta "It is an ID of current shift pattern which is being used by TCU.

The ID is assigned for each TCU.";
BA_ "UserSigValidity" SG_ 2164277252 TCU_ShftPtrnSta 3;
BA_ "RoutingFactor" SG_ 2164277252 TCU_ShftPtrnSta 5;
BA_ "Version" SG_ 2164277252 TCU_ShftPtrnSta "17.11.00";
BA_ "Description" SG_ 2164277252 TCU_EPBReq "This is EPB Request signal for prevent P-D Shift shock on the hill";
BA_ "UserSigValidity" SG_ 2164277252 TCU_EPBReq 3;
BA_ "RoutingFactor" SG_ 2164277252 TCU_EPBReq 5;
BA_ "Version" SG_ 2164277252 TCU_EPBReq "19.03.09";
BA_ "Description" SG_ 2164277252 IMT_EOLstate "If this signal is set, Cluster should display gear info using alphabet 'E' regardless the signal 'TCU_GearSlctDis'";
BA_ "UserSigValidity" SG_ 2164277252 IMT_EOLstate 3;
BA_ "RoutingFactor" SG_ 2164277252 IMT_EOLstate 5;
BA_ "Version" SG_ 2164277252 IMT_EOLstate "19.02.06";
BA_ "Description" SG_ 2164277252 IMT_DisCmd "This signal is used for cluster to change gear display type. 

Always Display / Not Display / Blinking";
BA_ "UserSigValidity" SG_ 2164277252 IMT_DisCmd 3;
BA_ "RoutingFactor" SG_ 2164277252 IMT_DisCmd 5;
BA_ "Version" SG_ 2164277252 IMT_DisCmd "19.02.06";
BA_ "Description" SG_ 2164277252 IMT_CltchPdlPos "Clutch Position Sensor value for 3 pedal IMT system.

This value is not supported by 2 pedal IMT system.



0% means pedal off 

99.21875% (0xFE) means pedal fully pressed

99.609375 (0xFF) means  error";
BA_ "UserSigValidity" SG_ 2164277252 IMT_CltchPdlPos 3;
BA_ "RoutingFactor" SG_ 2164277252 IMT_CltchPdlPos 5;
BA_ "Version" SG_ 2164277252 IMT_CltchPdlPos "19.02.06";
BA_ "Description" SG_ 2164277252 DCT_RegenInhbt "The regen inhibit request from TCU.

ECU is received regen inhibit flag from TCU, then ECU is limited the regen state.";
BA_ "UserSigValidity" SG_ 2164277252 DCT_RegenInhbt 3;
BA_ "RoutingFactor" SG_ 2164277252 DCT_RegenInhbt 5;
BA_ "Version" SG_ 2164277252 DCT_RegenInhbt "18.08.02";
BA_ "Description" SG_ 2164277252 DCT_EngIdleReq "Engine Idle Request from TCU";
BA_ "UserSigValidity" SG_ 2164277252 DCT_EngIdleReq 3;
BA_ "RoutingFactor" SG_ 2164277252 DCT_EngIdleReq 5;
BA_ "Version" SG_ 2164277252 DCT_EngIdleReq "18.08.02";
BA_ "Description" SG_ 2164277252 DCT_CltchState "Status of DCT clutches. This signal gives information about the frictional connection between the engine and the drive train.";
BA_ "UserSigValidity" SG_ 2164277252 DCT_CltchState 3;
BA_ "RoutingFactor" SG_ 2164277252 DCT_CltchState 5;
BA_ "Version" SG_ 2164277252 DCT_CltchState "18.08.02";
BA_ "Description" SG_ 2164277252 DCT_FuelCutReq "Fuel Cut request bit signal to let EMS perform ¡®Fuel Cut torque intervention¡¯ during shift";
BA_ "UserSigValidity" SG_ 2164277252 DCT_FuelCutReq 3;
BA_ "RoutingFactor" SG_ 2164277252 DCT_FuelCutReq 5;
BA_ "Version" SG_ 2164277252 DCT_FuelCutReq "18.08.02";
BA_ "Description" SG_ 2164277252 DCT_TqIncReq "An Identifier of a DCT TCU controller for increasing torque intervention. 

This bit is to prevent the triggering of unintended DCT TCU interventions.



In the case of a torque increase, following conditions must be fulfilled.

DCT_TqIncReq = 1 and TCU_EngTqIncReqVal > 00H.";
BA_ "UserSigValidity" SG_ 2164277252 DCT_TqIncReq 3;
BA_ "RoutingFactor" SG_ 2164277252 DCT_TqIncReq 5;
BA_ "Version" SG_ 2164277252 DCT_TqIncReq "18.08.02";
BA_ "Description" SG_ 2164277252 DCT_CrpTqReq "During creep mode (engine in idle, brake pedal not pressed, gear engaged) clutch torque will be applied. In order to support the engine¡¯s idle controller DCT_CrpTqReq gives the information how much clutch torque will be applied within the next 50 ms.";
BA_ "GenSigStartValue" SG_ 2164277252 DCT_CrpTqReq 512;
BA_ "UserSigValidity" SG_ 2164277252 DCT_CrpTqReq 3;
BA_ "RoutingFactor" SG_ 2164277252 DCT_CrpTqReq 5;
BA_ "Version" SG_ 2164277252 DCT_CrpTqReq "18.08.02";
BA_ "Description" SG_ 2164277252 DCT_ShftTqReq "To ensure a torque increasing during gear shift within short time, ECU needs to build up a torque reserve determined by the pre-control torque. 

Open throttle valve (more air) and automatic ignition angle reduction (within limited range based on engine characteristic) to ensure constant torque level.

The DCT TCU informs a pre-control torque via the signal DCT_ShftTqReq to the EMS.



If MSB is 1, this signal is - value. else, this signal is +value.

0~10bit is used for absolute value.";
BA_ "UserSigValidity" SG_ 2164277252 DCT_ShftTqReq 3;
BA_ "RoutingFactor" SG_ 2164277252 DCT_ShftTqReq 5;
BA_ "Version" SG_ 2164277252 DCT_ShftTqReq "20.03.05";
BA_ "Description" SG_ 2164277252 TCU_VgisInhbtReq "TCU requests ECU to inhibit the VGIS fuction from changing its status.";
BA_ "UserSigValidity" SG_ 2164277252 TCU_VgisInhbtReq 3;
BA_ "RoutingFactor" SG_ 2164277252 TCU_VgisInhbtReq 5;
BA_ "Version" SG_ 2164277252 TCU_VgisInhbtReq "17.11.00";
BA_ "Description" SG_ 2164277252 TCU_EngTqIncReqVal "The TCU requests the engine torque increase via this signal to the EMS.



If MSB is 1, this signal is - value.

else, this signal is +value.

0~10bit is used for absolute value.";
BA_ "UserSigValidity" SG_ 2164277252 TCU_EngTqIncReqVal 3;
BA_ "RoutingFactor" SG_ 2164277252 TCU_EngTqIncReqVal 5;
BA_ "Version" SG_ 2164277252 TCU_EngTqIncReqVal "20.03.05";
BA_ "GenMsgSendType" BO_ 2189467649 0;
BA_ "GenMsgCycleTime" BO_ 2189467649 50;
BA_ "GenMsgCycleTimeFast" BO_ 2189467649 0;
BA_ "GenMsgNrOfRepetition" BO_ 2189467649 0;
BA_ "VFrameFormat" BO_ 2189467649 1;
BA_ "Description" SG_ 2189467649 WHL_Crc1Val "The data area for CRC calculation is based on the data length (DLC) of the message DB.

The CRC shall be calculated over the entire data block (excluding the CRC bytes) including the user data, alive counter and Data ID

 

- CRC Polynomial (0x1021) , Initial Value : 0xFFFF, XOR value : 0x0000, Data ID : Message ID + 0xF800 

- The initial value is for CRC calculation and the message should be sent with the calculated result value. 

- The mathematical expression to 16 bit CRC polynomial is given here. G(x) = x16 + x12 + x5 + 1";
BA_ "GenSigStartValue" SG_ 2189467649 WHL_Crc1Val 65535;
BA_ "UserSigValidity" SG_ 2189467649 WHL_Crc1Val 3;
BA_ "RoutingFactor" SG_ 2189467649 WHL_Crc1Val 5;
BA_ "Version" SG_ 2189467649 WHL_Crc1Val "18.11.08";
BA_ "Description" SG_ 2189467649 WHL_AlvCnt1Val "For the first transmission request for a data element the counter shall be initialized with 0 and shall be incremented by 1 for every subsequent send request. 

When the counter reaches the maximum value(0xFF), then it shall restart with 0 for the next send request";
BA_ "UserSigValidity" SG_ 2189467649 WHL_AlvCnt1Val 3;
BA_ "RoutingFactor" SG_ 2189467649 WHL_AlvCnt1Val 5;
BA_ "Version" SG_ 2189467649 WHL_AlvCnt1Val "18.11.08";
BA_ "Description" SG_ 2189467649 WHL_PlsFLVal "This signal indicates accumulated pulse counter of ABS^ESC wheel speed sensor (FL^FR^RL^RR)

Receiver unit uses this signal for calculation of vehicle movement distance.

Requested resolution of this signal is 0.5 pulses and refer to below (wheel sensor signal).";
BA_ "UserSigValidity" SG_ 2189467649 WHL_PlsFLVal 3;
BA_ "RoutingFactor" SG_ 2189467649 WHL_PlsFLVal 5;
BA_ "Version" SG_ 2189467649 WHL_PlsFLVal "17.12.00";
BA_ "Description" SG_ 2189467649 WHL_PlsFRVal "This signal indicates accumulated pulse counter of ABS^ESC wheel speed sensor (FL^FR^RL^RR)

Receiver unit uses this signal for calculation of vehicle movement distance.

Requested resolution of this signal is 0.5 pulses and refer to below (wheel sensor signal).";
BA_ "UserSigValidity" SG_ 2189467649 WHL_PlsFRVal 3;
BA_ "RoutingFactor" SG_ 2189467649 WHL_PlsFRVal 5;
BA_ "Version" SG_ 2189467649 WHL_PlsFRVal "17.12.00";
BA_ "Description" SG_ 2189467649 WHL_PlsRLVal "This signal indicates accumulated pulse counter of ABS^ESC wheel speed sensor (FL^FR^RL^RR)

Receiver unit uses this signal for calculation of vehicle movement distance.

Requested resolution of this signal is 0.5 pulses and refer to below (wheel sensor signal).";
BA_ "UserSigValidity" SG_ 2189467649 WHL_PlsRLVal 3;
BA_ "RoutingFactor" SG_ 2189467649 WHL_PlsRLVal 5;
BA_ "Version" SG_ 2189467649 WHL_PlsRLVal "17.12.00";
BA_ "Description" SG_ 2189467649 WHL_PlsRRVal "This signal indicates accumulated pulse counter of ABS^ESC wheel speed sensor (FL^FR^RL^RR)

Receiver unit uses this signal for calculation of vehicle movement distance.

Requested resolution of this signal is 0.5 pulses and refer to below (wheel sensor signal).";
BA_ "UserSigValidity" SG_ 2189467649 WHL_PlsRRVal 3;
BA_ "RoutingFactor" SG_ 2189467649 WHL_PlsRRVal 5;
BA_ "Version" SG_ 2189467649 WHL_PlsRRVal "17.12.00";
BA_ "Description" SG_ 2189467649 WHL_DirFLVal "This signal is used to check the moving direction of WHL_PUL_FL signal.";
BA_ "UserSigValidity" SG_ 2189467649 WHL_DirFLVal 3;
BA_ "RoutingFactor" SG_ 2189467649 WHL_DirFLVal 5;
BA_ "Version" SG_ 2189467649 WHL_DirFLVal "17.12.00";
BA_ "Description" SG_ 2189467649 WHL_DirFRVal "This signal is used to check the moving direction of WHL_PUL_FR signal.";
BA_ "UserSigValidity" SG_ 2189467649 WHL_DirFRVal 3;
BA_ "RoutingFactor" SG_ 2189467649 WHL_DirFRVal 5;
BA_ "Version" SG_ 2189467649 WHL_DirFRVal "17.12.00";
BA_ "Description" SG_ 2189467649 WHL_DirRLVal "This signal is used to check the moving direction of WHL_PUL_RL signal.";
BA_ "UserSigValidity" SG_ 2189467649 WHL_DirRLVal 3;
BA_ "RoutingFactor" SG_ 2189467649 WHL_DirRLVal 5;
BA_ "Version" SG_ 2189467649 WHL_DirRLVal "17.12.00";
BA_ "Description" SG_ 2189467649 WHL_DirRRVal "This signal is used to check the moving direction of WHL_PUL_RR signal.";
BA_ "UserSigValidity" SG_ 2189467649 WHL_DirRRVal 3;
BA_ "RoutingFactor" SG_ 2189467649 WHL_DirRRVal 5;
BA_ "Version" SG_ 2189467649 WHL_DirRRVal "17.12.00";
BA_ "GenMsgSendType" BO_ 2189467650 0;
BA_ "GenMsgCycleTime" BO_ 2189467650 50;
BA_ "GenMsgCycleTimeFast" BO_ 2189467650 0;
BA_ "GenMsgNrOfRepetition" BO_ 2189467650 0;
BA_ "VFrameFormat" BO_ 2189467650 1;
BA_ "Description" SG_ 2189467650 WHL_SpdFLVal "This signal provides the wheel velocity of each wheel and have 14 bits length and a resolution of 0.03125 km^h.(This resolution is higher than that of signal in TCS5).

In case of failure of one wheel speed sensor, the value 3FFFH is used as error identifier.";
BA_ "UserSigValidity" SG_ 2189467650 WHL_SpdFLVal 3;
BA_ "RoutingFactor" SG_ 2189467650 WHL_SpdFLVal 5;
BA_ "Version" SG_ 2189467650 WHL_SpdFLVal "17.12.00";
BA_ "Description" SG_ 2189467650 WHL_SpdFRVal "This signal provides the wheel velocity of each wheel and have 14 bits length and a resolution of 0.03125 km^h.(This resolution is higher than that of signal in TCS5).

In case of failure of one wheel speed sensor, the value 3FFFH is used as error identifier.";
BA_ "UserSigValidity" SG_ 2189467650 WHL_SpdFRVal 3;
BA_ "RoutingFactor" SG_ 2189467650 WHL_SpdFRVal 5;
BA_ "Version" SG_ 2189467650 WHL_SpdFRVal "17.12.00";
BA_ "Description" SG_ 2189467650 WHL_SpdRLVal "This signal provides the wheel velocity of each wheel and have 14 bits length and a resolution of 0.03125 km^h.(This resolution is higher than that of signal in TCS5).

In case of failure of one wheel speed sensor, the value 3FFFH is used as error identifier.";
BA_ "UserSigValidity" SG_ 2189467650 WHL_SpdRLVal 3;
BA_ "RoutingFactor" SG_ 2189467650 WHL_SpdRLVal 5;
BA_ "Version" SG_ 2189467650 WHL_SpdRLVal "17.12.00";
BA_ "Description" SG_ 2189467650 WHL_SpdRRVal "This signal provides the wheel velocity of each wheel and have 14 bits length and a resolution of 0.03125 km^h.(This resolution is higher than that of signal in TCS5).

In case of failure of one wheel speed sensor, the value 3FFFH is used as error identifier.";
BA_ "UserSigValidity" SG_ 2189467650 WHL_SpdRRVal 3;
BA_ "RoutingFactor" SG_ 2189467650 WHL_SpdRRVal 5;
BA_ "Version" SG_ 2189467650 WHL_SpdRRVal "17.12.00";
BA_ "GenMsgSendType" BO_ 2189467651 0;
BA_ "GenMsgCycleTime" BO_ 2189467651 50;
BA_ "GenMsgCycleTimeFast" BO_ 2189467651 0;
BA_ "GenMsgNrOfRepetition" BO_ 2189467651 0;
BA_ "VFrameFormat" BO_ 2189467651 1;
BA_ "Description" SG_ 2189467651 WHL_SpdCalParmtr "ÀÌ ½ÅÈ£´Â ABS/ESC ³»ºÎ¿¡¼­ ÈÙ ÆÞ½º °ªÀ» ÈÙ ½ºÇÇµå·Î º¯È¯ÇÏ´Âµ¥ »ç¿ëÇÏ´Â ESC ³»ºÎ ÆÄ¶ó¹ÌÅÍ¸¦ ÀÇ¹ÌÇÔ.

º» ½ÅÈ£´Â ½ÇÁ¦ Å¸ÀÌ¾î µ¿¹Ý°æ°ú ´Ù¸¦ ¼ö ÀÖÀ¸¸ç, ABS/ESCÀÇ Á¦¾î¸¦ À§ÇÑ Â÷¼Ó ÃßÁ¤À» À§ÇØ °³¹ß °úÁ¤ Áß¿¡ ÀÓÀÇ·Î º¯°æÀÌ °¡´ÉÇÑ Calibration Value ÀÓ.

½ÅÈ£ »ç¿ëÀ» À§ÇØ¼­´Â »çÀü¿¡ ÇùÀÇ ÈÄ »ç¿ëÇØ¾ßÇÔ.";
BA_ "UserSigValidity" SG_ 2189467651 WHL_SpdCalParmtr 3;
BA_ "RoutingFactor" SG_ 2189467651 WHL_SpdCalParmtr 5;
BA_ "Version" SG_ 2189467651 WHL_SpdCalParmtr "19.05.02";
VAL_ 2239848449 FCA_OnOffEquipSta 0 "Default" 1 "Off" 2 "Warning" 3 "Assist" 4 "Reserved" 5 "Reserved" 6 "Reserved" 7 "Invalid" ;
VAL_ 2239848449 FCA_SysFlrSta 0 "Normal" 1 "Temp. Unavailable by Front View Camera (Sensor fusion)" 2 "Temp. Unavailable by Front Radar (Radar only or Sensor fusion in Radar)" 3 "Service Required" 4 "Temp. Unavailable by Front View Camera (Camera only)" 5 "Temp. Unavailable by Front View Camera (Sensor fusion in ADAS_DRV)" 6 "Temp. Unavailable by Front Radar (Sensor fusion in Camera)" 7 "Reserved" ;
VAL_ 2239848449 FCA_WrngLvlSta 0 "No warning" 1 "Warning level 1" 2 "Warning level 2" 3 "Warning level 3" ;
VAL_ 2239848449 FCA_VehStpReq 0 "No request" 1 "Stop control is required" 2 "Reserved" 3 "Error Indicator" ;
VAL_ 2239848449 FCA_StbltActvReq 0 "Release No alert" 1 "Pre-crash full retraction" 2 "Haptic warning" 3 "Reserved" 4 "Reserved" 5 "Reserved" 6 "Reserved" 7 "Reserved" ;
VAL_ 2239848449 FCA_HydrlcBstAsstReq 0 "Standard threshold" 1 "Lowered threshold 1" 2 "Lowered threshold 2" 3 "Lowered threshold 3" ;
VAL_ 2239848449 FCA_PrefillActvReq 0 "No pre-fill" 1 "Pre-fill act" 2 "Reserved" 3 "Error Indicator" ;
VAL_ 2239848449 FCA_PartialActvReq 0 "No Partial act" 1 "Partail act" 2 "Reserved" 3 "Error Indicator" ;
VAL_ 2239848449 FCA_FullActvReq 0 "No Full act" 1 "Full act" 2 "Reserved" 3 "Error Indicator" ;
VAL_ 2239848449 FCA_Regulation 0 "No warning" 1 "FCA Amber warning on" 2 "FCA Red warning blinking" 3 "Reserved" ;
VAL_ 2239848449 FCA_SnstvtyModRetVal 0 "Default" 1 "Late" 2 "Normal" 3 "Early" 4 "Reserved" 5 "Reserved" 6 "Reserved" 7 "Invalid" ;
VAL_ 2239848449 FCA_WrngSndSta 0 "No warning" 1 "Warning 1" 2 "Warning 2" 3 "Warning 3" 4 "Reserved" 5 "Reserved" 6 "Reserved" 7 "Error indicator" ;
VAL_ 2239848450 FCA_RelVel 511 "Signal Invalid" ;
VAL_ 2239848450 Nmode_FCAOff_Sta 0 "Not Applied" 1 "Disable" 2 "Enable" 3 "Invalid" ;
VAL_ 2239848450 FCA_Jnctn_OnOffEquipSta 0 "Default" 1 "Off" 2 "On" 3 "Invalid" ;
VAL_ 2239848450 HDP_EMOpSta 0 "Off" 1 "On (Not Active)" 2 "On (Active)" 3 "Reserved" 4 "Reserved" 5 "Reserved" 6 "Reserved" 7 "Error indicator" ;
VAL_ 2239848450 FCA_WrngTrgtDis 0 "None" 1 "FCA-Pedestrian" 2 "Reserved" 3 "FCA-Cyclist" 4 "Reserved" 5 "FCA-Car" 6 "Reserved" 7 "FCA-JC (L)" 8 "FCA-JC (R)" 9 "Reserved" 10 "Reserved" 11 "FCA-JT (L)" 12 "FCA-JT (R)" 13 "Reserved" 14 "Reserved" ;
VAL_ 2239848450 ADAS_DRV_FCA_Plus_Sta 0 "FCA-Car/Ped/Cyc+ »óÈ² ¹ÌÇØ´ç" 1 "FCA-Car/Ped/Cyc+ »óÈ² ÇØ´ç" 2 "Not Used" 3 "Error Indicator" ;
VAL_ 2239848450 ADAS_TrlOffStaDisp 0 "Normal" 1 "Auto Off by Trailer connected" 2 "Reserved" 3 "Reserved" ;
VAL_ 2239848450 FCA_FrOnOffEquipSta 0 "Default" 1 "Off" 2 "On" 3 "Invalid" ;
VAL_ 2239848450 FCA_JC_OnOffEquipSta 0 "Default" 1 "Off" 2 "On" 3 "Invalid" ;
VAL_ 2239848450 FCA_FrSdOnOffEquipSta 0 "Default" 1 "Off" 2 "On" 3 "Invalid" ;
VAL_ 2239848450 EM_WrngLvlSta 0 "No warning" 1 "Prefill (Warning level1)" 2 "Partial brake (Warning level2)" 3 "Full brake (Warning level3)" 4 "Reserved" 5 "Reserved" 6 "Reserved" 7 "Error indicator" ;
VAL_ 2239848450 BrkDelVLimReq 0 "Delta V limit required (Release brake control over ¥ÄV 50km/h)" 1 "Delta V limit not required w/ additional signal (Not release brake control)" 2 "Delta V limit not required w/o additional signal (Not release brake control)" 3 "Reserved" 4 "Reserved" 5 "Reserved" 6 "Reserved" 7 "Error indicator" ;
VAL_ 2239848450 ADAS_InhbtOffDispSta 0 "Default" 1 "Inhibit off in regulation (Cluster)" 2 "Inhibit off in regulation (H/UNIT)" 3 "Inhibit off in HDP (Cluster)" 4 "Reserved" 5 "Reserved" 6 "Reserved" 7 "Invalid" ;
VAL_ 2239848450 FCA_WarnTimeSta 0 "Default" 1 "Late" 2 "Normal" 3 "Reserved" 4 "Reserved" 5 "Reserved" 6 "Reserved" 7 "Invalid" ;
VAL_ 788 APSU_AstSlidePosition 0 "0x0x0~0xFE:POSITION" 254 "0x0x0~0xFE:POSITION" 255 "invalid" ;
VAL_ 788 APSU_AstHeightPosition 0 "0x0x0~0xFE:POSITION" 254 "0x0x0~0xFE:POSITION" 255 "invalid" ;
VAL_ 788 APSU_AstReclinePosition 0 "0x0x0~0xFE:POSITION" 254 "0x0x0~0xFE:POSITION" 255 "invalid" ;
VAL_ 788 APSU_AstRelaxTiltPosition 0 "0x0x0~0xFE:POSITION" 254 "0x0x0~0xFE:POSITION" 255 "invalid" ;
VAL_ 271 ASAU_AirSptTimeRValueSet 0 "Default" 1 "Short" 2 "Normal" 3 "Long" 4 "Reserved" 5 "Reserved" 6 "Reserved" 7 "Reserved" ;
VAL_ 271 ASAU_AstSmtAirSptRValueSet 0 "Default" 1 "Off" 2 "On" 3 "Invalid" ;
VAL_ 271 ASAU_CushSoftRValueSet 0 "Default" 1 "Off" 2 "Soft" 3 "Mid" 4 "Hard" 5 "Reserved" 6 "Reserved" 7 "Reserved" ;
VAL_ 271 ASAU_BackSoftRValueSet 0 "Default" 1 "Off" 2 "Soft" 3 "Mid" 4 "Hard" 5 "Reserved" 6 "Reserved" 7 "Reserved" ;
VAL_ 271 ASAU_AirSptModeRValueSet 0 "Default" 1 "Mode 1" 2 "Mode 2" 3 "Mode 3" 4 "Mode 4" 5 "Mode 5" 6 "Reserved" 7 "Reserved" ;
VAL_ 271 ASAU_NotFootMsgOperStaWarnPE 0 "Default" 1 "Off (Disable)" 2 "On (Enable)" 3 "Invalid" ;
VAL_ 271 ASAU_RRFootAirSptRValueSet 0 "Default" 1 "Off" 2 "On" 3 "Invalid" ;
VAL_ 271 ASAU_RRFootAirSptHeatRValueSet 0 "Default" 1 "Off" 2 "On" 3 "Invalid" ;
VAL_ 271 ASAU_MoodTrpyRValueSet 0 "Default" 1 "Off" 2 "On" 3 "Invalid" ;
VAL_ 271 ASAU_MoodTrpyCareSta 0 "Default" 1 "Off" 2 "On" 3 "Invalid" ;
VAL_ 271 ASAU_MoodTrpyComfSta 0 "Default" 1 "Off" 2 "On" 3 "Invalid" ;
VAL_ 271 ASAU_AirSptStrRValueSet 0 "Default" 1 "Low" 2 "Mid" 3 "High" 4 "Off" 5 "Reserved" 6 "Reserved" 7 "Reserved" ;
VAL_ 2395189761 DATC_Typ 255 "Error Indicator" ;
VAL_ 2395189761 DATC_Opt1Typ 255 "Error Indicator" ;
VAL_ 2395189761 DATC_Opt3Typ 255 "Error Indicator" ;
VAL_ 2395189761 DATC_Opt2Typ 15 "Error Indicator" ;
VAL_ 2395189761 DATC_TxtPopupReq 0 "Off" 1 "TEXT POP-UP Request On" 2 "reserverd" 3 "Error Indicator" ;
VAL_ 2395189761 DATC_StrWhlUSMSta 0 "NOT APPLY" 1 "OFF" 2 "ON" 3 "Error Indicator" ;
VAL_ 2395189761 DATC_StrWhlHtngReq 0 "Default" 1 "Integrated control OFF" 2 "Steering Wheel heat OFF" 3 "Steering Wheel heat 1st ON" 4 "Steering Wheel heat 1st & 2nd ON" 5 "Reserved" 6 "Reserved" 7 "Invalid" ;
VAL_ 2193667329 EMS_Crc1Val 65535 "Signal Invalid (Message with unused CRC. CRC signal is transmitted fixed value)" ;
VAL_ 2193667329 EMS_AlvCnt1Val 255 "Signal Invalid (Message with unused Alive counter. Alive counter signal is transmitted fixed value)" ;
VAL_ 2193667330 ENG_EngSpdErrSta 0 "No error" 1 "Engine speed sensor defective" 2 "Not used" 3 "Error indicator" ;
VAL_ 2193667330 ENG_MafErrSta 0 "No error" 1 "Error on Torque Measurement" 2 "Not used" 3 "Error indicator" ;
VAL_ 2193667330 ENG_EtcLmphModSta 0 "Engine control is available" 1 "ETC Limphome mode by ECU" 2 "Not used" 3 "Error indicator" ;
VAL_ 2193667330 ENG_SpltInjctnSta 0 "Split injection OFF" 1 "Split injection ON" 2 "Not used" 3 "Error indicator" ;
VAL_ 2193667330 ENG_MaxAirconTqVal 255 "Error indicator" ;
VAL_ 2193667330 ENG_AirconPrsrSnsrVal 255 "Error indicator" ;
VAL_ 2193667330 ENG_IsgSta 0 "ISG is not operating Normal engine operating without ISG" 1 "Idle stop is activated Idle is stopped by ECU during driving" 2 "Automatically started by ECU Engine is automatically started by ECU regardless driver¡¯s volition during idle stop because the condition that ISG function to be prohibited is satisfied, for example SOC is too low." 3 "ISG is prohibited Driver prohibits to activate ISG in order to avoid start lag when he met traffic jam for example." 4 "Fault  existing in ISG. Idle stop is prohibited and engine started automatically if it is idle stop condition." 5 "Idle stop is inhibited by system automatically for safety and  convenient condition related with battery SOC, brake vacuum pressure etc. ISG function check for EOL." 6 "Auto start is deactivated system automatically to keep safety, Such as door open, hood open and seat belt unlock." 7 "If driver shift gear N to D range without braking to make auto starting. (Economy ISG Only)" ;
VAL_ 2193667330 ENG_OilLvlSta 0 "OIL LEVEL LAMP Off" 1 "OIL LEVEL LAMP On" 2 "Not used" 3 "Error indicator" ;
VAL_ 2214659329 EMS_Crc7Val 65535 "Signal Invalid (Message with unused CRC. CRC signal is transmitted fixed value)" ;
VAL_ 2214659329 EMS_AlvCnt7Val 255 "Signal Invalid (Message with unused Alive counter. Alive counter signal is transmitted fixed value)" ;
VAL_ 2214659330 HEV_EngOpSta 0 "ES(Engine Stop)" 1 "ST(Start)" 2 "IS(Idle speed)" 3 "PL(Part Load)" 4 "PU(Pull)" 5 "PUC(Fuel Cut off)" ;
VAL_ 2214659330 HEV_AccelPdlVal 0 "Accelerator Pedal not activated" 1022 "Accelerator Pedal fully activated" 1023 "Accelerator Pedal is defective (fail state) or Non-ETC system (APS is not installed)" ;
VAL_ 2277634049 EPB_LmpStaDis 0 "Release State (EPB AVH)" 1 "Apply State (EPB)" 2 "Dynamic Braking (EPB) or Driver Action Requested" ;
VAL_ 2277634049 EPB_FlrLmpStaDis 0 "No failure" 1 "Failure detected or in diagnosis mode" 2 "EOL configuration not done or Emergency released" 3 "Reserved" 4 "Reserved" 5 "Reserved" 6 "Reserved" 7 "Reserved" 8 "Reserved" 9 "Reserved" 10 "Reserved" 11 "Reserved" 12 "Reserved" 13 "Reserved" 14 "Not used" 15 "Error Indicator" ;
VAL_ 2277634049 EPB_OutDataDis 0 "Off" 1 "EPB is in maintenance mode" 2 "Driver tries to DAR but safety condition is not satisfied" 3 "EPB applies by ESC request" 4 "Driver tries to DAR but safety condition is not satisfied for China" 5 "Driver tries to release EPB by operating the switch without pressing the brake pedal" 6 "Driver tries to park in the N(Neutral) position" ;
VAL_ 2277634049 EPB_AlrmReq 0 "Off" 1 "Comfortable tone (Sound once)" 2 "Uncomfortable tone" 3 "Error Indicator" ;
VAL_ 2277634049 EPB_SwPosSta 0 "Neutral position" 1 "Apply position (pull)" 2 "Release position (push)" 3 "Switch failure" ;
VAL_ 2277634049 EPB_RrBrkLtActvReq 0 "No request" 1 "Request to turn on rear brake lights" 2 "Not used" 3 "Error Indicator" ;
VAL_ 2277634049 EPB_FrcErrSta 0 "No failure" 1 "Clamp position not reached" 2 "Emergency release" 3 "Force not measurable (e.g. sensor failure)" ;
VAL_ 2277634049 EPB_DynmBrkFrcReqSigSta 0 "EPB_DynmBrkFrcReqSigSta signal is invalid" 1 "EPB_DynmBrkFrcReqSigSta signal is valid" 2 "Not used" 3 "Error Indicator" ;
VAL_ 2277634049 EPB_FrcSta 0 "See details in EPB_FRC_ERR" 1 "Released" 2 "Clamped" 3 "Clamping in progress" 4 "Releasing in progress" 5 "Dynamic braking via EPB" 6 "Releasing in progress by switch" 7 "Clamping in progress by switch" ;
VAL_ 2277634049 EPB_FlSta 0 "Not valid" 1 "EPB No failure" 2 "EPB Initialization State" 3 "EPB Diagnostic" 4 "EPB Temporarily Not Available" 5 "EPB Permanently Not Available" ;
VAL_ 2277634049 EPB_EscReqAckSta 0 "Idle / No acknowledge" 1 "Acknowledge for external ESC request" 2 "Not used" 3 "Error Indicator" ;
VAL_ 2277634049 EPB_DynmBrkFrcReq 0 "No Request" 1 "Dynamic braking request" 2 "Not used" 3 "Error Indicator" ;
VAL_ 2277634049 EPB_EmerModReq 0 "No Request" 1 "Emergency EPB Mode Request" 2 "Normal EPB Mode Request" 3 "Not Used" ;
VAL_ 2277634049 EPB_EpbSta4VcuReq 0 "Undefined (Initialization or Unknown State)" 1 "Clamped by VCU Parking Command" 2 "Moving for EPB applying or releasing" 3 "Release State by VCU Not Parking Command" ;
VAL_ 2277634050 EPB_ActlFrcVal 0 "EPB Fully released" ;
VAL_ 2244048129 ESC_VehAccelVal 2047 "Error" ;
VAL_ 2244048129 ESC_AccelBasisVal 2047 "Error" ;
VAL_ 2244048129 PWI_STATE 0 "nomarl" 1 "pad wear" 2 "reserved" 3 "invaild or Error" ;
VAL_ 2244048130 SCC_OptTyp 0 "SCC is not equipped" 1 "SCC is equipped" 2 "Not used" 3 "Not Coded" ;
VAL_ 2244048130 ESC_BrkLtReq 0 "No request" 1 "Activate brake lights" 2 "Not used" 3 "Error Indicator" ;
VAL_ 2244048130 ESC_DclEnblReq 0 "Disable deceleration control" 1 "Enable deceleration control" 2 "Not used" 3 "Error Indicator" ;
VAL_ 2244048130 ESC_DrvOvrdSta 0 "No override" 1 "Override by acceleration pedal" 2 "Override by deceleration" 3 "Error Indicator" ;
VAL_ 2244048130 ESC_DrvBrkSta 0 "Driver is not braking / failure" 1 "Driver is braking" 2 "Not used" 3 "Error Indicator" ;
VAL_ 2244048130 SCC_EnblReq 0 "SCC enabled" 1 "SCC disabled reversible" 2 "SCC disabled irreversible" 3 "SCC disabled irreversible due to communication error" ;
VAL_ 2244048130 ESC_DrvBrkActvSta 0 "Brake pedal not pressed" 1 "Brake pedal pressed" 2 "Not used" 3 "Error Indicator" ;
VAL_ 2244048130 ESC_PrkBrkActvSta 0 "Parking brake is not activated" 1 "Parking brake is activated" 2 "Not used" 3 "Error Indicator" ;
VAL_ 2244048130 ESC_HDP_FltMonSta 0 "No Fault" 1 "Main Controller Fault Detected (ADAS_DRV 2)" 2 "Sub Controller Fault Detected (FR_CMR)" 3 "Main & Sub Controller Fault Detected (ADAS_DRV 2 & FR_CMR)" 4 "Reserved" 5 "Reserved" 6 "Reserved" 7 "Reserved" ;
VAL_ 2244048130 FCA_EquipSta 0 "FCA is not equipped" 1 "FCA is equipped" 2 "Not used" 3 "Not Coded" ;
VAL_ 2244048130 FCA_AvlblSta 0 "Available" 1 "Temporarily not available" 2 "Permanently not available" 3 "FCA Communication Error" ;
VAL_ 2244048130 ESC_FCA_ActvSta 0 "FCA Brake is not in activation" 1 "FCA Pre-Brake" 2 "FCA Full-Brake" 3 "Invalid" ;
VAL_ 2244048130 ESC_DBS_ActvSta 0 "DBS control is inactive" 1 "DBS control is active" 2 "Not used" 3 "Not used" ;
VAL_ 2244048130 SCC_TqReq 0 "No request" 1 "Enable SCC torque request" 2 "Not used" 3 "Error Indicator" ;
VAL_ 2244048130 ESC_HDP_EgSta 0 "Not engaged" 1 "Engaged in main controller by IEB (ESC)" 2 "Engaged in sub controller by IEB (ESC)" 3 "MRM with IEB (ESC) alone" 4 "Engaged in main controller by RCU" 5 "Engaged in sub controller by RCU" 6 "MRM with RCU alone" 7 "Reserved" ;
VAL_ 2244048130 ESC_HDP_EnblReq 0 "No Fault" 1 "Req. longitudinal control normal, Functional Fault" 2 "Req. longitudinal control normal, Partial performance degradation" 3 "Req. longitudinal control abnormal, Brake control possible" 4 "Req. longitudinal control abnormal, Brake control impossible" 5 "Req. longitudinal control normal, Acceleration control Fault (eg. Engine Fault)" 6 "Reserved" 7 "Reserved" ;
VAL_ 2244048130 CSC_WrngSta 0 "Not Control(Default)" 1 "Control" 2 "Reserved" 3 "Error Indicator" ;
VAL_ 2244048130 ESC_BrkdFltStndstill 0 "Undetected" 1 "Detected" 2 "Not used" 3 "Not used" ;
VAL_ 2244048130 SCC_ReqLimSta 0 "No request" 1 "Limited No Limitation" 2 "Acceleration Limited" 3 "Deceleration Limited" ;
VAL_ 2244048130 ESC_StdStillVal 0 "No stand still detected" 1 "stand still detected" 2 "Not used" 3 "Error Indicator" ;
VAL_ 2244048131 ESC_RccaSta 0 "RCCA availble" 1 "RCCA brake started" 2 "RCCA braking is ended" 3 "RCCA braking error" ;
VAL_ 2244048131 ESC_RspaCanFlFlag 0 "ESC received RSPA CAN message successfully" 1 "ESC failed to receive RSPA CAN message successfully" 2 "Not used" 3 "Error Indicator" ;
VAL_ 2244048131 ESC_RspaDclActv 0 "Inactive" 1 "Active" 2 "Not used" 3 "Error Indicator" ;
VAL_ 2244048131 ESC_RspaStandStill 0 "Initial" 1 "ESC stopped the vehicle by RSPA request" 2 "Not used" 3 "Error Indicator" ;
VAL_ 2244048131 ESC_PcaSta 0 "PCA available" 1 "PCA brake started" 2 "PCA brake ended" 3 "PCA disable" ;
VAL_ 2244048131 MCB_ReqBrkAck 0 "Wait Status for Crash" 1 "Received ACU Crash Information" 2 "Not used" 3 "Not used" ;
VAL_ 2244048131 MCB_CtlSta 0 "Not Activation" 1 "Activation" ;
VAL_ 2244048131 MCB_DefSta 0 "Normal state" 1 "Fail" ;
VAL_ 2244048131 ESC_DiffBrkFuncSta 0 "Differential braking available without error" 1 "Differential braking disable" 2 "Differential braking is activated" 3 "Error Indicator" ;
VAL_ 2244048131 ESC_LsdLimMod 0 "Maximum limitation mode" 1 "Minimum limitation mode" ;
VAL_ 2244048131 ESC_LsdOpn 0 "Passive" 1 "Fast Open" 2 "Slow Open" 3 "Torque Limit" 4 "eLSD Fail OPEN" 5 "Reserved" 6 "Reserved" 7 "Error" ;
VAL_ 2244048131 ESC_BcaRPlusSta 0 "BCA-R+ available" 1 "BCA-R+ braking is started" 2 "BCA-R+ braking is ended" 3 "BCA-R+ braking error" ;
VAL_ 2244048131 ESC_RspaSta 0 "Not used" 1 "ESC Initial" 2 "ESC New Start" 3 "ESC Ready" 4 "Not used" 5 "ESC Assist" 6 "ESC Assist Fail" 7 "ESC Abort" 8 "ESC Ready Fail" ;
VAL_ 787 DPSU_DrvSlidePosition 0 "0x0x00~0xFE:POSITION" 254 "0x0x00~0xFE:POSITION" 255 "invalid" ;
VAL_ 787 DPSU_DrvHeightPosition 0 "0x0x00~0xFE:POSITION" 254 "0x0x00~0xFE:POSITION" 255 "invalid" ;
VAL_ 787 DPSU_DrvReclinePosition 0 "0x0x00~0xFE:POSITION" 254 "0x0x00~0xFE:POSITION" 255 "invalid" ;
VAL_ 787 DPSU_DrvRelaxTiltPosition 0 "0x0x00~0xFE:POSITION" 254 "0x0x00~0xFE:POSITION" 255 "invalid" ;
VAL_ 799 DRV_CrashUnlockCmd 0 "Off" 1 "Unlock(Crash)" ;
VAL_ 799 C_ApprOpenStatus 0 "Approach Open Off" 1 "Approach Open On" ;
VAL_ 799 DoorLock_DrvKeyLkSwSta_SBCM 0 "Off" 1 "Lock" 2 "Not Used" 3 "Error Indicator" ;
VAL_ 799 DoorLock_DrvKeyUnLkSwSta_SBCM 0 "Off" 1 "Unlock" 2 "Not Used" 3 "Error Indicator" ;
VAL_ 799 Warn_DrvDrSwSta_SBCM 0 "Close" 1 "Open" 2 "RESERVED" 3 "Error Indicator" ;
VAL_ 799 DoorLock_DrvDrUnLkSta_SBCM 0 "Lock" 1 "Unlock" 2 "Not Used" 3 "Error Indicator" ;
VAL_ 799 DRV_SEAWarn_LH 0 "SEA Left Warning OFF" 1 "SEA Left Warning ON" 2 "Reserved" 3 "Invalid" ;
VAL_ 799 DRV_SEAWarn_RH 0 "SEA Right Warning OFF" 1 "SEA Right  Warning ON" 2 "Reserved" 3 "Invalid" ;
VAL_ 799 DRV_SEWWarn_LH 0 "SEW Left Warning OFF" 1 "SEW Left Warning ON" 2 "Reserved" 3 "Invalid" ;
VAL_ 799 DRV_SEWWarn_RH 0 "SEW Right Warning OFF" 1 "SEW Right Warning ON" 2 "Reserved" 3 "Invalid" ;
VAL_ 799 DRV_MRActivationAlarm 0 "Off" 1 "On" 2 "Not Used" 3 "Error Indicator" ;
VAL_ 799 DRV_ReleaseWarn 0 "Release Warning OFF" 1 "Release Warning ON" 2 "Reserved" 3 "Invalid" ;
VAL_ 799 Latch_TypeOption_DRV 0 "Off" 1 "On" 2 "Not Used" 3 "Error Indicator" ;
VAL_ 799 DRV_SWFailAlarm 0 "Off" 1 "On" 2 "Not Used" 3 "Error Indicator" ;
VAL_ 799 USM_PwrDRApprOpnSetSta 0 "Default" 1 "Off" 2 "On" 3 "Invalid" ;
VAL_ 799 USM_PwrDRApprOpnSetOpt 0 "Default" 1 "Off" 2 "On" 3 "Invalid" ;
VAL_ 799 USM_PwrDRCloseByRKELockSta 0 "Default" 1 "Off" 2 "On" 3 "Invalid" ;
VAL_ 799 USM_PwrDRCloseByRKELockOpt 0 "Default" 1 "Off" 2 "On" 3 "Invalid" ;
VAL_ 799 USM_PwrDRCloseByBrakeSta 0 "Default" 1 "Off" 2 "On" 3 "Invalid" ;
VAL_ 799 USM_PwrDRCloseByBrakeOpt 0 "Default" 1 "Off" 2 "On" 3 "Invalid" ;
VAL_ 799 USM_PwrDRBuzzerSta 0 "Default" 1 "Off" 2 "On" 3 "Invalid" ;
VAL_ 799 USM_PwrDRBuzzerOpt 0 "Default" 1 "Off" 2 "On" 3 "Invalid" ;
VAL_ 799 PDS_TypeOption_DRV 0 "Off" 1 "On" 2 "Not Used" 3 "Error Indicator" ;
VAL_ 799 C_DrvDoorApproachOpen 0 "Default" 1 "Approach Open Request" 2 "Approach Open Stop" 3 "Not Used" ;
VAL_ 799 C_DrvDoorApproachClose 0 "Default" 1 "Approach Close Request" 2 "Approach Close Stop" 3 "Not Used" ;
VAL_ 799 DoorLock_PDSLkSwSta_DRV 0 "Default" 1 "Lock" 2 "Not Used" 3 "Error Indicator" ;
VAL_ 799 DRVDoorPushAlarm 0 "Off" 1 "On" 2 "Not Used" 3 "Error Indicator" ;
VAL_ 2164277249 TCU_GearSlctDis 0 "P" 1 "L" 2 "2" 3 "3" 4 "DS Mode" 5 "D" 6 "N" 7 "R" 8 "sports mode / manual shift / paddle shift" 9 "Not Display at Cluster" 10 "Sub-Rom Communication" 11 "Sub-Rom Communication Error" 12 "Paddle shift (D-position)" 13 "Reserved" 14 "Intermediate Position" 15 "fault" ;
VAL_ 2164277249 TCU_Typ 0 "Reserved" 1 "Step A" 2 "CVT" 3 "DCT" 4 "AMT" 5 "eClutch (2pedal)" 6 "eClutch (3pedal)" ;
VAL_ 2164277249 TCU_TqRdctnVal 0 "Max. reduction" 2047 "No reduction" 2048 "reduction to 0 torque" ;
VAL_ 2164277249 TCU_GearStepTyp 3 "3 - Speed AT or DCT" 4 "4 - Speed AT or DCT" 5 "5 - Speed AT or DCT" 6 "6 - Speed AT or DCT" 7 "7- Speed AT or DCT" 8 "8 - Speed AT or DCT" ;
VAL_ 2164277249 TCU_GearShftSta 0 "no gear change" 1 "gear change is active" 2 "Not used" 3 "Error Indicator" ;
VAL_ 2164277249 TCU_TqCnvrtrSta 0 "No lock up control" 1 "Slip lock up" 2 "Fully lock up" 3 "Off slip lock up" ;
VAL_ 2164277250 TCU_CurrGearSta 0 "if N or P are detected (no frictional connection)" 1 "1st speed" 2 "2nd speed" 3 "3rd speed" 4 "4th speed" 5 "5th speed" 6 "6th speed" 7 "7th speed" 8 "8th speed" 14 "Reverse speed" ;
VAL_ 2164277250 TCH_EngTrgtGearSta 0 "if N or P are detected (no frictional connection)" 1 "1st speed" 2 "2nd speed" 3 "3rd speed" 4 "4th speed" 5 "5th speed" 6 "6th speed" 7 "7th speed" 8 "8th speed" 14 "Reverse speed" ;
VAL_ 2164277250 TCU_EngTqLimVal 0 "Max. reduction" 2047 "No reduction" 2048 "reduction to 0 torque" ;
VAL_ 2164277250 TCU_CluTrgtGearConfg 0 "TCU_TrgtGearSta" 1 "TCU_CluTrgtGearSta" 2 "Not Used" 3 "Error Indicator" ;
VAL_ 2164277250 TCU_VehSpdKphVal 255 "Error Indicator" ;
VAL_ 2164277250 TCU_TrgtGearSta 0 "if N or P are detected (no frictional connection)" 1 "1st speed" 2 "2nd speed" 3 "3rd speed" 4 "4th speed" 5 "5th speed" 6 "6th speed" 7 "7th speed" 8 "8th speed" 14 "Reverse speed" ;
VAL_ 2164277250 TCU_DcmlVehSpdKphVal 0 "Error Indicator" ;
VAL_ 2164277250 TCU_GearLmpBlnkngReq 0 "No blink" 1 "Request lamp blinking" 2 "Not used" 3 "Error Indicator" ;
VAL_ 2164277250 TCU_FuelCutInhbtReq 0 "No request" 1 "Fuel cut inhibition request from TCU" 2 "Not used" 3 "Error Indicator" ;
VAL_ 2164277250 TCU_IdleUpReq 0 "No IDLE UP request" 1 "IDLE UP request" 2 "Not used" 3 "Error Indicator" ;
VAL_ 2164277250 TCU_CluTrgtGearSta 0 "if N or P are detected (no frictional connection)" 1 "1st speed" 2 "2nd speed" 3 "3rd speed" 4 "4th speed" 5 "5th speed" 6 "6th speed" 7 "7th speed" 8 "8th speed" 14 "Reverse speed" ;
VAL_ 2164277251 TCU_EngRpmDis 65535 "Error Indicator" ;
VAL_ 2164277251 TCU_EngSpdIncReq 0 "No request" 1 "Engine speed increase is requested" 2 "Not used" 3 "Error Indicator" ;
VAL_ 2164277251 TCU_ObdSta 0 "Default" 2 "Failure information of TCU" 3 "Failure information of TCU" 4 "MIL on request" 5 "MIL on request" 6 "Failure information of TCU & MIL on request" 7 "Failure information of TCU & MIL on request" ;
VAL_ 2164277251 TCU_SprtyIndxSta 0 "Invalid" 1 "Step 1" 2 "Step 2" 3 "Step 3" 4 "Step 4" 5 "Step 5" 6 "Step 6" 7 "Step 7" 8 "Step 8" 9 "Step 9" 10 "Step 10" 11 "Step 11" 12 "Step 12" 13 "Step 13" 14 "Step 14" 15 "Step 15" 16 "Step 16" 17 "Step 17" 18 "Step 18" 19 "Step 19" 20 "Step 20" 21 "Step 21" 22 "Step 22" 23 "Step 23" 24 "Step 24" 25 "Step 25" 26 "Invalid" 27 "Invalid" 28 "Invalid" 29 "Invalid" 30 "Invalid" 31 "Invalid" ;
VAL_ 2164277251 TCU_DrvngModDis 0 "Inactive" 1 "Normal" 2 "Eco" 3 "Eco+" 4 "Sport" 5 "Sport+" 6 "Snow" 7 "Reserved" ;
VAL_ 2164277251 TCU_DrvngModReq 0 "Inactive" 1 "Normal" 2 "Eco" 3 "Eco+" 4 "Sport" 5 "Sport+" 6 "Snow" 7 "Reserved" ;
VAL_ 2164277251 TCU_SmrtShftSta 0 "Smart Shift not Applied" 1 "Smart Shift Applied" 2 "Not used" 3 "Error Indicator" ;
VAL_ 2164277251 TCU_FrtStcShftSta 0 "First static shift function is not activated." 1 "First static shift function is activated" 2 "Not used" 3 "Error Indicator" ;
VAL_ 2164277251 TCU_IsgInhbtReq 0 "TCU inhibits the ISG function" 1 "ISG is available" 2 "Not used" 3 "Error Indicator" ;
VAL_ 2164277251 TCU_CdaInhbtReq 0 "CDA transition is available" 1 "TCU prohibits CDA transition" 2 "Not used" 3 "Error Indicator" ;
VAL_ 2164277251 TCU_BrkOnReq 0 "No request" 1 "Brake On Request" 2 "Not used" 3 "Error Indicator" ;
VAL_ 2164277251 TCU_TqGrdntLimVal 255 "No torque gradient limitation" ;
VAL_ 2164277252 TCU_NetrlCtrlSta 0 "No NC" 1 "NC Entry" 2 "NC Applied" 3 "NC Exit" ;
VAL_ 2164277252 TCU_ShftPtrnSta 0 "Normal (ECO)" 1 "Uphill 1 (Optional)" 2 "Uphill 2 (Optional)" 3 "Reserved" 4 "Downhill 1 (Optional)" 5 "Cruise (Optional)" 6 "Cruise_Uphill 1 (Optional)" 7 "Cruise_Uphill 2 (Optional)" 8 "Active ECO (Optional)" 9 "Sport Drive (Optional)" 15 "None of the above" ;
VAL_ 2164277252 TCU_EPBReq 0 "No Request (default)" 1 "EPB Request" ;
VAL_ 2164277252 IMT_EOLstate 0 "display gear info using 'TCU_GearSlctDis'" 1 "display gear info by alphabet 'E'" ;
VAL_ 2164277252 IMT_DisCmd 0 "Not Display" 1 "Display (Not blinking)" 2 "Display (blinking)" 3 "Reserved" ;
VAL_ 2164277252 DCT_RegenInhbt 0 "No Inhibit" 1 "Regen. Inhibit" 2 "Not Used" 3 "Error Indicator" ;
VAL_ 2164277252 DCT_EngIdleReq 0 "No Request" 1 "Idle Request" 2 "Not Used" 3 "Error Indicator" ;
VAL_ 2164277252 DCT_CltchState 0 "Drivetrain (Both Clutch) Open" 1 "Odd Clutch Slipping" 2 "Even Clutch Slipping" 3 "Clutch Locked" ;
VAL_ 2164277252 DCT_FuelCutReq 0 "No request" 1 "Fuel Cut Request" 2 "Not Used" 3 "Error Indicator" ;
VAL_ 2164277252 DCT_TqIncReq 0 "No Request" 1 "Torque increase Request" 2 "Not Used" 3 "Error Indicator" ;
VAL_ 2164277252 DCT_ShftTqReq 0 "No request" 2047 "Max. Increase" 2048 "reduction to 0 torque" ;
VAL_ 2164277252 TCU_VgisInhbtReq 0 "There¡¯s no request from TCU" 1 "TCU inhibits ECU from changing VGIS status" 2 "Not used" 3 "Error Indicator" ;
VAL_ 2164277252 TCU_EngTqIncReqVal 0 "No request" 2047 "Max. Increase" 2048 "reduction to 0 torque" ;
VAL_ 2189467649 WHL_PlsFLVal 255 "Error" ;
VAL_ 2189467649 WHL_PlsFRVal 255 "Error" ;
VAL_ 2189467649 WHL_PlsRLVal 255 "Error" ;
VAL_ 2189467649 WHL_PlsRRVal 255 "Error" ;
VAL_ 2189467649 WHL_DirFLVal 0 "Unknown (Wheel moving stop state or Not applied wheel sensor for direction)" 1 "Forward direction" 2 "Backward direction" 3 "Error identifier" ;
VAL_ 2189467649 WHL_DirFRVal 0 "Unknown (Wheel moving stop state or Not applied wheel sensor for direction)" 1 "Forward direction" 2 "Backward direction" 3 "Error identifier" ;
VAL_ 2189467649 WHL_DirRLVal 0 "Unknown (Wheel moving stop state or Not applied wheel sensor for direction)" 1 "Forward direction" 2 "Backward direction" 3 "Error identifier" ;
VAL_ 2189467649 WHL_DirRRVal 0 "Unknown (Wheel moving stop state or Not applied wheel sensor for direction)" 1 "Forward direction" 2 "Backward direction" 3 "Error identifier" ;
VAL_ 2189467650 WHL_SpdFLVal 16383 "Error" ;
VAL_ 2189467650 WHL_SpdFRVal 16383 "Error" ;
VAL_ 2189467650 WHL_SpdRLVal 16383 "Error" ;
VAL_ 2189467650 WHL_SpdRRVal 16383 "Error" ;
